VERSION "HNNBNNNYNNNNNNNNNNNNNNNNNNNNNNNNNNNNNNNNNN/4/%%%/4/'%**4NNN///"

NS_ :

BS_:

BU_: BAP_Tester BCM Gateway_Max TSGGen3_BFS TSGGen3_FS TSGGen3_HBFS TSGGen3_HFS WLC_01_CFD

BO_ 2527679923 ADA_01: 16 Gateway_Max
 SG_ ADA_DistractionLevel : 12|7@1+ (0.01,0) [0.00|1.00] "Unit_None"  Vector__XXX
 SG_ ADA_DrowsinessLevel : 19|7@1+ (0.01,0) [0.00|1.00] "Unit_None"  Vector__XXX
 SG_ ADA_AttentionLevel : 26|7@1+ (0.01,0) [0.00|1.00] "Unit_None"  Vector__XXX
 SG_ ADA_DriverIsOperating : 33|2@1+ (1.0,0.0) [0.0|3] ""  Vector__XXX
 SG_ ADA_HMI_Ablenkung_Deaktivierung : 35|1@1+ (1.0,0.0) [0.0|1] ""  Vector__XXX
 SG_ ADA_HMI_Ablenkung_Fehler_Popup : 36|2@1+ (1.0,0.0) [0.0|3] ""  Vector__XXX
 SG_ ADA_HMI_Ablenkung_Meldeakustik : 38|1@1+ (1.0,0.0) [0.0|1] ""  Vector__XXX
 SG_ ADA_HMI_Ablenkung_Meldung : 39|2@1+ (1.0,0.0) [0.0|3] ""  Vector__XXX
 SG_ ADA_HMI_Fahrzeit_seit_Pause : 41|10@1+ (1,0) [0|1022] "Unit_Minut"  Vector__XXX
 SG_ ADA_HMI_Muedigkeit_Deaktivierung : 51|1@1+ (1.0,0.0) [0.0|1] ""  Vector__XXX
 SG_ ADA_HMI_Muedigkeit_Fehler_Popup : 52|2@1+ (1.0,0.0) [0.0|3] ""  Vector__XXX
 SG_ ADA_HMI_Muedigkeit_Meldeakustik : 54|1@1+ (1.0,0.0) [0.0|1] ""  Vector__XXX
 SG_ ADA_HMI_Muedigkeit_Meldung : 55|3@1+ (1.0,0.0) [0.0|7] ""  BCM
 SG_ ADA_HMI_Muedigkeit_Event_Meldung : 58|2@1+ (1.0,0.0) [0.0|3] ""  BCM
 SG_ ADA_DrowsinessSystemState : 60|3@1+ (1.0,0.0) [0.0|7] ""  Vector__XXX
 SG_ ADA_Microsleep : 63|3@1+ (1.0,0.0) [0.0|7] ""  Vector__XXX
 SG_ ADA_TriggerEmergencyAssist : 66|3@1+ (1.0,0.0) [0.0|7] ""  Vector__XXX
 SG_ ADA_Upcoming_Microsleep : 69|1@1+ (1.0,0.0) [0.0|1] ""  Vector__XXX
 SG_ SOK_ADA_01_Signatur : 96|32@1+ (1,0) [0|4294967295] ""  Vector__XXX

BO_ 64 Airbag_01: 8 Gateway_Max
 SG_ Airbag_01_CRC : 0|8@1+ (1,0) [0|255] ""  BCM,TSGGen3_BFS,TSGGen3_FS,TSGGen3_HBFS,TSGGen3_HFS
 SG_ Airbag_01_BZ : 8|4@1+ (1,0) [0|15] ""  BCM,TSGGen3_BFS,TSGGen3_FS,TSGGen3_HBFS,TSGGen3_HFS
 SG_ AB_RGS_Anst : 12|4@1+ (1.0,0.0) [0.0|15] ""  BCM
 SG_ AB_Front_Crash : 16|1@1+ (1.0,0.0) [0.0|1] ""  BCM,TSGGen3_BFS,TSGGen3_FS,TSGGen3_HBFS,TSGGen3_HFS
 SG_ AB_Heck_Crash : 17|1@1+ (1.0,0.0) [0.0|1] ""  BCM,TSGGen3_BFS,TSGGen3_FS,TSGGen3_HBFS,TSGGen3_HFS
 SG_ AB_SF_Crash : 18|1@1+ (1.0,0.0) [0.0|1] ""  BCM,TSGGen3_BFS,TSGGen3_FS,TSGGen3_HBFS,TSGGen3_HFS
 SG_ AB_SB_Crash : 19|1@1+ (1.0,0.0) [0.0|1] ""  BCM,TSGGen3_BFS,TSGGen3_FS,TSGGen3_HBFS,TSGGen3_HFS
 SG_ AB_Rollover_Crash : 20|1@1+ (1.0,0.0) [0.0|1] ""  BCM,TSGGen3_BFS,TSGGen3_FS,TSGGen3_HBFS,TSGGen3_HFS
 SG_ AB_Crash_Int : 21|3@1+ (1.0,0.0) [0.0|7] ""  BCM,TSGGen3_BFS,TSGGen3_FS,TSGGen3_HBFS,TSGGen3_HFS
 SG_ AB_Lampe : 24|1@1+ (1.0,0.0) [0.0|1] ""  BCM
 SG_ AB_Deaktiviert : 25|1@1+ (1.0,0.0) [0.0|1] ""  BCM
 SG_ AB_VB_deaktiviert : 26|1@1+ (1.0,0.0) [0.0|1] ""  BCM
 SG_ AB_Systemfehler : 27|1@1+ (1.0,0.0) [0.0|1] ""  BCM
 SG_ AB_Diagnose : 28|1@1+ (1.0,0.0) [0.0|1] ""  BCM
 SG_ AB_Stellgliedtest : 29|1@1+ (1.0,0.0) [0.0|1] ""  BCM
 SG_ AB_Erh_Auf_VB : 30|2@1+ (1.0,0.0) [0.0|3] ""  BCM
 SG_ AB_Gurtwarn_VF : 32|1@1+ (1.0,0.0) [0.0|1] ""  BCM,TSGGen3_FS,TSGGen3_HBFS,TSGGen3_HFS
 SG_ AB_Gurtwarn_VB : 33|1@1+ (1.0,0.0) [0.0|1] ""  BCM,TSGGen3_BFS,TSGGen3_HBFS,TSGGen3_HFS
 SG_ AB_Anzeige_Fussg : 34|2@1+ (1.0,0.0) [0.0|3] ""  BCM
 SG_ AB_Texte_AKS : 36|2@1+ (1.0,0.0) [0.0|3] ""  BCM
 SG_ AB_PAO_Leuchte_Anf : 38|1@1+ (1.0,0.0) [0.0|1] ""  BCM
 SG_ AB_MKB_gueltig : 39|1@1+ (1.0,0.0) [0.0|1] ""  BCM
 SG_ AB_MKB_Anforderung : 40|1@1+ (1.0,0.0) [0.0|1] ""  BCM
 SG_ AB_Versorgungsspannung : 41|1@1+ (1.0,0.0) [0.0|1] ""  BCM
 SG_ AB_Deaktivierung_HV : 42|3@1+ (1.0,0.0) [0.0|7] ""  BCM
 SG_ AB_EDR_Trigger : 45|2@1+ (1.0,0.0) [0.0|3] ""  BCM
 SG_ AB_Belegung_VF : 47|2@1+ (1.0,0.0) [0.0|3] ""  BCM
 SG_ AB_Gurtschloss_FA_ext : 49|3@1+ (1.0,0.0) [0.0|7] ""  BCM
 SG_ AB_Gurtschloss_FA_ext_aktiv : 52|1@1+ (1.0,0.0) [0.0|1] ""  BCM
 SG_ AB_eCS_Error : 53|1@1+ (1.0,0.0) [0.0|1] ""  BCM
 SG_ ASM_Masterzeit_02 : 56|8@1+ (0.04,0) [0.00|10.16] "Unit_Secon"  BCM

BO_ 1312 Airbag_02: 8 Gateway_Max
 SG_ Airbag_02_CRC : 0|8@1+ (1,0) [0|255] ""  BCM
 SG_ Airbag_02_BZ : 8|4@1+ (1,0) [0|15] ""  BCM
 SG_ LoGeWa_Event_Kombiwarnung : 12|4@1+ (1.0,0.0) [0.0|15] ""  BCM
 SG_ AB_Anforderung_eCall : 16|1@1+ (1.0,0.0) [0.0|1] ""  BCM
 SG_ AB_Anprall_Seite_Beifahrer : 17|1@1+ (1.0,0.0) [0.0|1] ""  BCM
 SG_ AB_Anprall_Rollover : 18|1@1+ (1.0,0.0) [0.0|1] ""  BCM
 SG_ AB_Anprall_FGS : 19|1@1+ (1.0,0.0) [0.0|1] ""  BCM
 SG_ AB_Anprall_Front_Beifahrer : 20|1@1+ (1.0,0.0) [0.0|1] ""  BCM
 SG_ AB_Anprall_Front_Fahrer : 21|1@1+ (1.0,0.0) [0.0|1] ""  BCM
 SG_ AB_Anprall_Heck_Beifahrer : 22|1@1+ (1.0,0.0) [0.0|1] ""  BCM
 SG_ AB_Anprall_Heck_Fahrer : 23|1@1+ (1.0,0.0) [0.0|1] ""  BCM
 SG_ AB_Wickelklappung_Reihe2_MI : 24|2@1+ (1.0,0.0) [0.0|3] ""  BCM
 SG_ AB_Belegung_VB : 26|2@1+ (1.0,0.0) [0.0|3] ""  BCM,TSGGen3_BFS
 SG_ AB_Abschaltanf_SIH_BF : 28|1@1+ (1.0,0.0) [0.0|1] ""  BCM
 SG_ AB_Anprall_Seite_Fahrer : 29|1@1+ (1.0,0.0) [0.0|1] ""  BCM
 SG_ SC_PAO_Schriftzug_Anf : 30|2@1+ (1.0,0.0) [0.0|3] ""  BCM
 SG_ SC_PAO_ON_Anf : 32|2@1+ (1.0,0.0) [0.0|3] ""  BCM
 SG_ SC_PAO_OFF_Anf : 34|2@1+ (1.0,0.0) [0.0|3] ""  BCM
 SG_ AB_Crashschwere : 36|3@1+ (1.0,0.0) [0.0|7] ""  BCM
 SG_ AB_Anforderung_USM : 39|1@1+ (1.0,0.0) [0.0|1] ""  BCM
 SG_ AB_Gurtschloss_FA : 40|2@1+ (1.0,0.0) [0.0|3] ""  BCM,TSGGen3_FS,TSGGen3_HBFS,TSGGen3_HFS
 SG_ AB_Gurtschloss_BF : 42|2@1+ (1.0,0.0) [0.0|3] ""  BCM,TSGGen3_BFS,TSGGen3_HBFS,TSGGen3_HFS
 SG_ AB_Gurtschloss_Reihe2_FA : 44|2@1+ (1.0,0.0) [0.0|3] ""  BCM
 SG_ AB_Gurtschloss_Reihe2_MI : 46|2@1+ (1.0,0.0) [0.0|3] ""  BCM
 SG_ AB_Gurtschloss_Reihe2_BF : 48|2@1+ (1.0,0.0) [0.0|3] ""  BCM
 SG_ AB_Gurtschloss_Reihe3_FA : 50|2@1+ (1.0,0.0) [0.0|3] ""  BCM
 SG_ AB_Gurtschloss_Reihe3_MI : 52|2@1+ (1.0,0.0) [0.0|3] ""  BCM
 SG_ AB_Gurtschloss_Reihe3_BF : 54|2@1+ (1.0,0.0) [0.0|3] ""  BCM
 SG_ AB_Sitzpos_Sens_FA : 56|2@1+ (1.0,0.0) [0.0|3] ""  BCM,TSGGen3_FS,TSGGen3_HBFS,TSGGen3_HFS
 SG_ AB_Sitzpos_Sens_BF : 58|2@1+ (1.0,0.0) [0.0|3] ""  BCM,TSGGen3_BFS,TSGGen3_HBFS,TSGGen3_HFS
 SG_ AB_Wickelklappung_Reihe2_BF : 60|2@1+ (1.0,0.0) [0.0|3] ""  BCM
 SG_ AB_Wickelklappung_Reihe2_FA : 62|2@1+ (1.0,0.0) [0.0|3] ""  BCM

BO_ 1349 Airbag_04: 8 Gateway_Max
 SG_ Airbag_04_CRC : 0|8@1+ (1,0) [0|255] ""  BCM
 SG_ Airbag_04_BZ : 8|4@1+ (1,0) [0|15] ""  BCM
 SG_ AB_Anprall_Front : 12|1@1+ (1.0,0.0) [0.0|1] ""  Vector__XXX
 SG_ AB_Anprall_Heck : 13|1@1+ (1.0,0.0) [0.0|1] ""  Vector__XXX
 SG_ AB_Gurtwarn_Reihe4_FA : 14|2@1+ (1.0,0.0) [0.0|3] ""  BCM
 SG_ AB_Gurtwarn_Reihe4_BF : 16|2@1+ (1.0,0.0) [0.0|3] ""  BCM
 SG_ AB_Gurtwarn_Reihe4_MI : 18|2@1+ (1.0,0.0) [0.0|3] ""  BCM
 SG_ AB_Gurtwarn_Reihe2_FA : 20|2@1+ (1.0,0.0) [0.0|3] ""  BCM
 SG_ AB_Gurtwarn_Reihe2_BF : 22|2@1+ (1.0,0.0) [0.0|3] ""  BCM
 SG_ AbstWarn_MV_FAS_Fkt_Status : 24|2@1+ (1.0,0.0) [0.0|3] ""  Vector__XXX
 SG_ WarnBrems_Charisma_Status : 26|2@1+ (1.0,0.0) [0.0|3] ""  Vector__XXX
 SG_ WarnBrems_Charisma_FahrPr : 28|4@1+ (1.0,0.0) [0.0|15] ""  Vector__XXX
 SG_ AB_Gurtwarn_Reihe2_MI : 32|2@1+ (1.0,0.0) [0.0|3] ""  BCM
 SG_ AB_Gurtwarn_Reihe3_FA : 34|2@1+ (1.0,0.0) [0.0|3] ""  BCM
 SG_ AB_Gurtwarn_Reihe3_MI : 36|2@1+ (1.0,0.0) [0.0|3] ""  BCM
 SG_ AB_Gurtwarn_Reihe3_BF : 38|2@1+ (1.0,0.0) [0.0|3] ""  BCM
 SG_ LGI_FAS_Fkt_Status : 40|2@1+ (1.0,0.0) [0.0|3] ""  Vector__XXX
 SG_ PreCrash_FAS_Fkt_Status : 42|3@1+ (1.0,0.0) [0.0|7] ""  Vector__XXX
 SG_ AB_Belegung_VF_ext : 45|3@1+ (1.0,0.0) [0.0|7] ""  BCM
 SG_ AB_SBR_hinten_verbau : 48|2@1+ (1.0,0.0) [0.0|3] ""  Vector__XXX
 SG_ AB_Belegung_VF_ext_aktiv : 50|1@1+ (1.0,0.0) [0.0|1] ""  BCM
 SG_ AWV_Einstellung_System_ASG : 51|1@1+ (1.0,0.0) [0.0|1] ""  Vector__XXX
 SG_ AWV_Einstellung_Warnung_ASG : 52|3@1+ (1.0,0.0) [0.0|7] ""  Vector__XXX
 SG_ SC_PreSense_Modus_Warnung_NV : 55|3@1+ (1.0,0.0) [0.0|7] ""  Vector__XXX
 SG_ SC_PreSense_Modus_Warnung_MV : 58|3@1+ (1.0,0.0) [0.0|7] ""  Vector__XXX
 SG_ SC_PreSense_Modus_System_MV : 61|1@1+ (1.0,0.0) [0.0|1] ""  Vector__XXX
 SG_ SC_PreSense_Modus_System_NV : 62|1@1+ (1.0,0.0) [0.0|1] ""  Vector__XXX
 SG_ SC_PreSense_Modus_System_KAS : 63|1@1+ (1.0,0.0) [0.0|1] ""  Vector__XXX

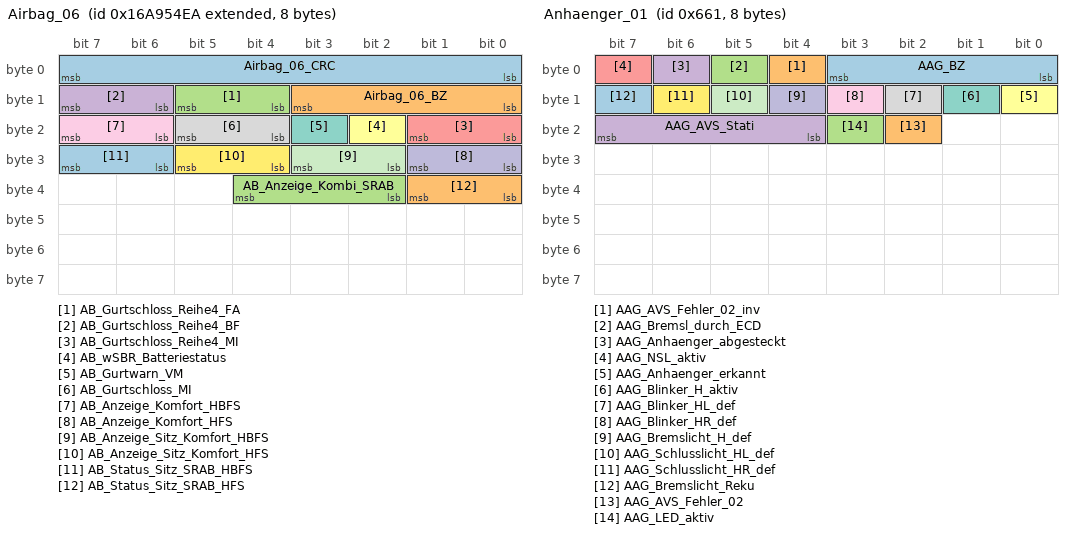
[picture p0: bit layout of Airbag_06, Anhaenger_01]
BO_ 2527679722 Airbag_06: 8 Gateway_Max
 SG_ Airbag_06_CRC : 0|8@1+ (1,0) [0|255] ""  Vector__XXX
 SG_ Airbag_06_BZ : 8|4@1+ (1,0) [0|15] ""  Vector__XXX
 SG_ AB_Gurtschloss_Reihe4_FA : 12|2@1+ (1.0,0.0) [0.0|3] ""  BCM
 SG_ AB_Gurtschloss_Reihe4_BF : 14|2@1+ (1.0,0.0) [0.0|3] ""  BCM
 SG_ AB_Gurtschloss_Reihe4_MI : 16|2@1+ (1.0,0.0) [0.0|3] ""  BCM
 SG_ AB_wSBR_Batteriestatus : 18|1@1+ (1.0,0.0) [0.0|1] ""  Vector__XXX
 SG_ AB_Gurtwarn_VM : 19|1@1+ (1.0,0.0) [0.0|1] ""  BCM
 SG_ AB_Gurtschloss_MI : 20|2@1+ (1.0,0.0) [0.0|3] ""  BCM
 SG_ AB_Anzeige_Komfort_HBFS : 22|2@1+ (1.0,0.0) [0.0|3] ""  Vector__XXX
 SG_ AB_Anzeige_Komfort_HFS : 24|2@1+ (1.0,0.0) [0.0|3] ""  Vector__XXX
 SG_ AB_Anzeige_Sitz_Komfort_HBFS : 26|2@1+ (1.0,0.0) [0.0|3] ""  Vector__XXX
 SG_ AB_Anzeige_Sitz_Komfort_HFS : 28|2@1+ (1.0,0.0) [0.0|3] ""  Vector__XXX
 SG_ AB_Status_Sitz_SRAB_HBFS : 30|2@1+ (1.0,0.0) [0.0|3] ""  Vector__XXX
 SG_ AB_Status_Sitz_SRAB_HFS : 32|2@1+ (1.0,0.0) [0.0|3] ""  Vector__XXX
 SG_ AB_Anzeige_Kombi_SRAB : 34|3@1+ (1.0,0.0) [0.0|7] ""  Vector__XXX

BO_ 1633 Anhaenger_01: 8 Gateway_Max
 SG_ AAG_BZ : 0|4@1+ (1,0) [0|15] ""  Vector__XXX
 SG_ AAG_AVS_Fehler_02_inv : 4|1@1+ (1.0,0.0) [0.0|1] ""  BCM
 SG_ AAG_Bremsl_durch_ECD : 5|1@1+ (1.0,0.0) [0.0|1] ""  Vector__XXX
 SG_ AAG_Anhaenger_abgesteckt : 6|1@1+ (1.0,0.0) [0.0|1] ""  Vector__XXX
 SG_ AAG_NSL_aktiv : 7|1@1+ (1.0,0.0) [0.0|1] ""  Vector__XXX
 SG_ AAG_Anhaenger_erkannt : 8|1@1+ (1.0,0.0) [0.0|1] ""  BCM
 SG_ AAG_Blinker_H_aktiv : 9|1@1+ (1.0,0.0) [0.0|1] ""  Vector__XXX
 SG_ AAG_Blinker_HL_def : 10|1@1+ (1.0,0.0) [0.0|1] ""  BCM
 SG_ AAG_Blinker_HR_def : 11|1@1+ (1.0,0.0) [0.0|1] ""  BCM
 SG_ AAG_Bremslicht_H_def : 12|1@1+ (1.0,0.0) [0.0|1] ""  Vector__XXX
 SG_ AAG_Schlusslicht_HL_def : 13|1@1+ (1.0,0.0) [0.0|1] ""  Vector__XXX
 SG_ AAG_Schlusslicht_HR_def : 14|1@1+ (1.0,0.0) [0.0|1] ""  Vector__XXX
 SG_ AAG_Bremslicht_Reku : 15|1@1+ (1.0,0.0) [0.0|1] ""  Vector__XXX
 SG_ AAG_AVS_Fehler_02 : 18|1@1+ (1.0,0.0) [0.0|1] ""  BCM
 SG_ AAG_LED_aktiv : 19|1@1+ (1.0,0.0) [0.0|1] ""  Vector__XXX
 SG_ AAG_AVS_Stati : 20|4@1+ (1.0,0.0) [0.0|15] ""  BCM

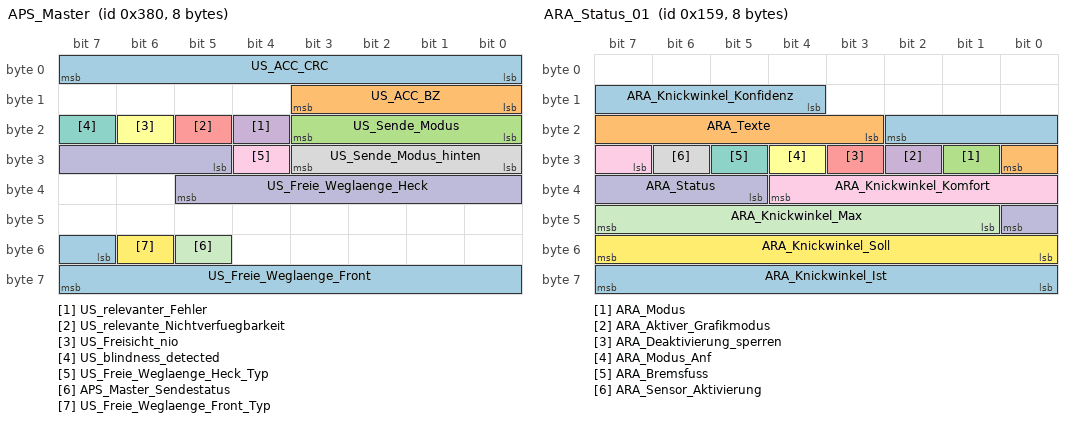
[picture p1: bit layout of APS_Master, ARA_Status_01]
BO_ 896 APS_Master: 8 Gateway_Max
 SG_ US_ACC_CRC : 0|8@1+ (1,0) [0|255] ""  Vector__XXX
 SG_ US_ACC_BZ : 8|4@1+ (1,0) [0|15] ""  Vector__XXX
 SG_ US_Sende_Modus : 16|4@1+ (1.0,0.0) [0.0|15] ""  Vector__XXX
 SG_ US_relevanter_Fehler : 20|1@1+ (1.0,0.0) [0.0|1] ""  Vector__XXX
 SG_ US_relevante_Nichtverfuegbarkeit : 21|1@1+ (1.0,0.0) [0.0|1] ""  Vector__XXX
 SG_ US_Freisicht_nio : 22|1@1+ (1.0,0.0) [0.0|1] ""  Vector__XXX
 SG_ US_blindness_detected : 23|1@1+ (1.0,0.0) [0.0|1] ""  Vector__XXX
 SG_ US_Sende_Modus_hinten : 24|4@1+ (1.0,0.0) [0.0|15] ""  Vector__XXX
 SG_ US_Freie_Weglaenge_Heck_Typ : 28|1@1+ (1.0,0.0) [0.0|1] ""  BCM
 SG_ US_Freie_Weglaenge_Heck : 29|9@1+ (0.01,0) [0.00|5.00] "Unit_Meter"  BCM
 SG_ APS_Master_Sendestatus : 53|1@1+ (1.0,0.0) [0.0|1] ""  Vector__XXX
 SG_ US_Freie_Weglaenge_Front_Typ : 54|1@1+ (1.0,0.0) [0.0|1] ""  Vector__XXX
 SG_ US_Freie_Weglaenge_Front : 55|9@1+ (0.01,0) [0.00|5.00] "Unit_Meter"  Vector__XXX

BO_ 345 ARA_Status_01: 8 Gateway_Max
 SG_ ARA_Knickwinkel_Konfidenz : 12|7@1+ (1,0) [0|120] "Unit_DegreOfArc"  Vector__XXX
 SG_ ARA_Texte : 19|6@1+ (1.0,0.0) [0.0|63] ""  Vector__XXX
 SG_ ARA_Modus : 25|1@1+ (1.0,0.0) [0.0|1] ""  Vector__XXX
 SG_ ARA_Aktiver_Grafikmodus : 26|1@1+ (1.0,0.0) [0.0|1] ""  Vector__XXX
 SG_ ARA_Deaktivierung_sperren : 27|1@1+ (1.0,0.0) [0.0|1] ""  Vector__XXX
 SG_ ARA_Modus_Anf : 28|1@1+ (1.0,0.0) [0.0|1] ""  TSGGen3_FS
 SG_ ARA_Bremsfuss : 29|1@1+ (1.0,0.0) [0.0|1] ""  Vector__XXX
 SG_ ARA_Sensor_Aktivierung : 30|1@1+ (1.0,0.0) [0.0|1] ""  Vector__XXX
 SG_ ARA_Knickwinkel_Komfort : 31|6@1+ (1,0) [0|60] "Unit_DegreOfArc"  Vector__XXX
 SG_ ARA_Status : 37|4@1+ (1.0,0.0) [0.0|15] ""  Vector__XXX
 SG_ ARA_Knickwinkel_Max : 41|7@1+ (1,0) [0|120] "Unit_DegreOfArc"  Vector__XXX
 SG_ ARA_Knickwinkel_Soll : 48|8@1+ (1,-125) [-125|126] "Unit_DegreOfArc"  Vector__XXX
 SG_ ARA_Knickwinkel_Ist : 56|8@1+ (1,-125) [-125|126] "Unit_DegreOfArc"  Vector__XXX

BO_ 2527679661 AWV_02: 8 Gateway_Max
 SG_ WBA_Warnblinken : 0|2@1+ (1.0,0.0) [0.0|3] ""  BCM
 SG_ AWV_KA_Konfiguration : 2|1@1+ (1.0,0.0) [0.0|1] ""  Vector__XXX
 SG_ AWV_Warnung : 12|3@1+ (1.0,0.0) [0.0|7] ""  Vector__XXX
 SG_ AWV_Texte_02 : 15|3@1+ (1.0,0.0) [0.0|7] ""  Vector__XXX
 SG_ AWV_Warnlevel : 18|6@1+ (1.0,0.0) [0.0|63] ""  Vector__XXX
 SG_ AWV_Einstellung_System_FSG : 24|1@1+ (1.0,0.0) [0.0|1] ""  Vector__XXX
 SG_ AWV_Einstellung_Warnung_FSG : 25|3@1+ (1.0,0.0) [0.0|7] ""  Vector__XXX
 SG_ AWV_Status_Anzeige : 28|2@1+ (1.0,0.0) [0.0|3] ""  Vector__XXX
 SG_ AWV_LED_Leiste : 30|2@1+ (1.0,0.0) [0.0|3] ""  Vector__XXX
 SG_ AWV_Priowarnung : 32|1@1+ (1.0,0.0) [0.0|1] ""  Vector__XXX
 SG_ AWV_AW_Abstand : 33|9@1+ (1,0) [0|508] "Unit_Meter"  Vector__XXX
 SG_ AWV_AW_Zeitluecke : 42|3@1+ (1.0,0.0) [0.0|7] ""  Vector__XXX
 SG_ AWV_AW_Texte : 45|3@1+ (1.0,0.0) [0.0|7] ""  Vector__XXX
 SG_ AWV_AW_Texte_Zusatzanzeige : 48|4@1+ (1.0,0.0) [0.0|15] ""  Vector__XXX
 SG_ AWV_KA_ObjektFront : 52|1@1+ (1.0,0.0) [0.0|1] ""  Vector__XXX
 SG_ AWV_Warnung_Richtung : 53|3@1+ (1.0,0.0) [0.0|7] ""  Vector__XXX
 SG_ AWV_Kamera_Objekt_ID : 56|8@1+ (1,0) [1|255] "Unit_None"  Vector__XXX

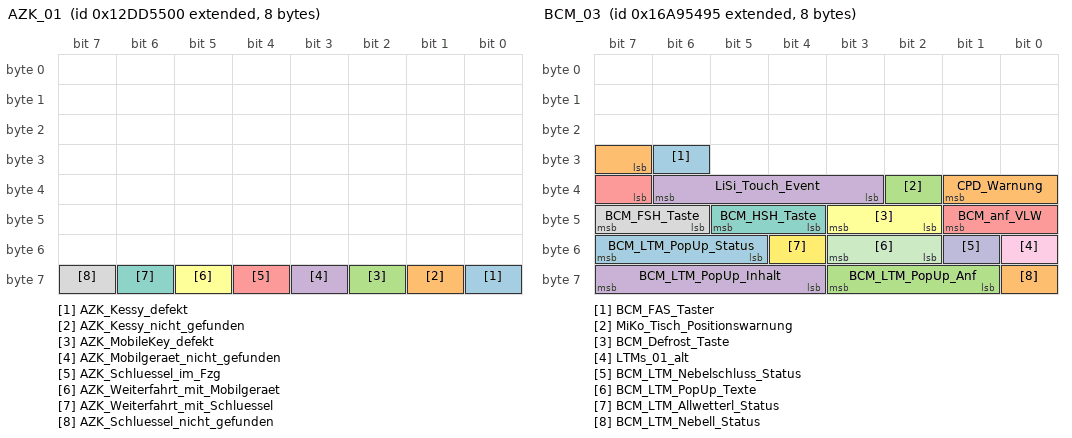
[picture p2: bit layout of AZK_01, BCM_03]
BO_ 2463978752 AZK_01: 8 BCM
 SG_ AZK_Kessy_defekt : 56|1@1+ (1.0,0.0) [0.0|1] ""  Gateway_Max
 SG_ AZK_Kessy_nicht_gefunden : 57|1@1+ (1.0,0.0) [0.0|1] ""  Gateway_Max
 SG_ AZK_MobileKey_defekt : 58|1@1+ (1.0,0.0) [0.0|1] ""  Gateway_Max
 SG_ AZK_Mobilgeraet_nicht_gefunden : 59|1@1+ (1.0,0.0) [0.0|1] ""  Gateway_Max
 SG_ AZK_Schluessel_im_Fzg : 60|1@1+ (1.0,0.0) [0.0|1] ""  Gateway_Max
 SG_ AZK_Weiterfahrt_mit_Mobilgeraet : 61|1@1+ (1.0,0.0) [0.0|1] ""  Gateway_Max
 SG_ AZK_Weiterfahrt_mit_Schluessel : 62|1@1+ (1.0,0.0) [0.0|1] ""  Gateway_Max
 SG_ AZK_Schluessel_nicht_gefunden : 63|1@1+ (1.0,0.0) [0.0|1] ""  Gateway_Max

BO_ 2536704256 BAP_Aussenlicht_ASG_01: 8 Gateway_Max
 SG_ BAP_Aussenlicht_ASG_01_Header : 0|8@1+ (1.0,0.0) [0.0|255] ""  BCM

BO_ 2536704257 BAP_Aussenlicht_ASG_02: 8 Gateway_Max
 SG_ BAP_Aussenlicht_ASG_02_Header : 0|8@1+ (1,0) [0|255] "Unit_None"  BCM

BO_ 2536704272 BAP_Aussenlicht_FSG_01: 8 BCM
 SG_ BAP_Aussenlicht_FSG_01_Header : 0|8@1+ (1.0,0.0) [0.0|255] ""  Gateway_Max

BO_ 2536726786 BAP_Car2X_ASG_03: 8 Gateway_Max
 SG_ BAP_Car2X_ASG_03_Header : 0|64@1+ (1.0,0.0) [0.0|18446744073709551615] ""  BCM

BO_ 2536726802 BAP_Car2X_FSG_03: 8 BCM
 SG_ BAP_Car2X_FSG_03_Header : 0|64@1+ (1.0,0.0) [0.0|18446744073709551615] ""  Gateway_Max

BO_ 2536767264 BAP_Debug_Cmd: 8 BAP_Tester
 SG_ BAP_Debug_Cmd : 0|16@1+ (1.0,0.0) [0.0|65535] ""  BCM,TSGGen3_BFS,TSGGen3_FS

BO_ 2536767280 BAP_Debug_Data: 8 BCM
 SG_ BAP_Debug_Data : 0|64@1+ (1.0,0.0) [0.0|18446744073709551615] ""  BAP_Tester

BO_ 2536705280 BAP_Doorlocking_ASG_01: 8 Gateway_Max
 SG_ BAP_Doorlocking_ASG_01_Header : 0|8@1+ (1.0,0.0) [0.0|255] ""  BCM

BO_ 2536705281 BAP_Doorlocking_ASG_02: 8 Gateway_Max
 SG_ BAP_Doorlocking_ASG_02_Header : 0|8@1+ (1.0,0.0) [0.0|255] ""  BCM

BO_ 2536705282 BAP_Doorlocking_ASG_03: 8 Gateway_Max
 SG_ BAP_Doorlocking_ASG_03_Header : 0|8@1+ (1.0,0.0) [0.0|255] ""  BCM

BO_ 2536705296 BAP_Doorlocking_FSG_01: 8 BCM
 SG_ BAP_Doorlocking_FSG_01_Header : 0|8@1+ (1.0,0.0) [0.0|255] ""  Gateway_Max

BO_ 2536727296 BAP_Doors2_ASG_01: 8 Gateway_Max
 SG_ BAP_Doors2_ASG_01_Header : 0|64@1+ (1.0,0.0) [0.0|18446744073709551615] ""  TSGGen3_BFS

BO_ 2536727312 BAP_Doors2_FSG_01: 8 TSGGen3_BFS
 SG_ BAP_Doors2_FSG_01_Header : 0|64@1+ (1.0,0.0) [0.0|18446744073709551615] ""  Gateway_Max

BO_ 2536724736 BAP_Doors_ASG_01: 8 Gateway_Max
 SG_ BAP_Doors_ASG_01_Header : 0|8@1+ (1,0) [0|255] "Unit_None"  TSGGen3_FS

BO_ 2536724752 BAP_Doors_FSG_01: 8 TSGGen3_FS
 SG_ BAP_Doors_FSG_01_Header : 0|8@1+ (1,0) [0|255] "Unit_None"  Gateway_Max

BO_ 2536724480 BAP_ENI2_ASG_01: 8 Gateway_Max
 SG_ BAP_ENI2_ASG_01_Header : 0|8@1+ (1,0) [0|255] "Unit_None"  BCM

BO_ 2536724481 BAP_ENI2_ASG_02: 8 Gateway_Max
 SG_ BAP_ENI2_ASG_02_Header : 0|8@1+ (1,0) [0|255] "Unit_None"  BCM

BO_ 2536724496 BAP_ENI2_FSG_01: 8 BCM
 SG_ BAP_ENI2_FSG_01_Header : 0|8@1+ (1,0) [0|255] "Unit_None"  Gateway_Max

BO_ 2536724497 BAP_ENI2_FSG_02: 8 BCM
 SG_ BAP_ENI2_FSG_02_Header : 0|8@1+ (1,0) [0|255] "Unit_None"  Gateway_Max

BO_ 2536707072 BAP_Homelink_ASG_01: 8 Gateway_Max
 SG_ BAP_Homelink_ASG_01_Header : 0|64@1+ (1.0,0.0) [0.0|18446744073709551615] ""  BCM

BO_ 2536707088 BAP_Homelink_FSG_01: 8 BCM
 SG_ BAP_Homelink_FSG_01_Header : 0|64@1+ (1.0,0.0) [0.0|18446744073709551615] ""  Gateway_Max

BO_ 2536722946 BAP_IAA_PSO_ASG_03: 8 BCM
 SG_ BAP_IAA_PSO_ASG_03_Header : 0|8@1+ (1,0) [0|255] "Unit_None"  Gateway_Max

BO_ 2536722960 BAP_IAA_PSO_FSG_01: 8 Gateway_Max
 SG_ BAP_IAA_PSO_FSG_01_Header : 0|8@1+ (1,0) [0|255] "Unit_None"  BCM

BO_ 2536704000 BAP_Innenlicht_ASG_01: 8 Gateway_Max
 SG_ BAP_Innenlicht_ASG_01_Header : 0|8@1+ (1.0,0.0) [0.0|255] ""  BCM

BO_ 2536704001 BAP_Innenlicht_ASG_02: 8 Gateway_Max
 SG_ BAP_Innenlicht_ASG_02_Header : 0|8@1+ (1,0) [0|255] "Unit_None"  BCM

BO_ 2536704003 BAP_Innenlicht_ASG_04: 8 Gateway_Max
 SG_ BAP_Innenlicht_ASG_04_Header : 0|64@1+ (1.0,0.0) [0.0|18446744073709551615] ""  BCM

BO_ 2536704016 BAP_Innenlicht_FSG_01: 8 BCM
 SG_ BAP_Innenlicht_FSG_01_Header : 0|8@1+ (1.0,0.0) [0.0|255] ""  Gateway_Max

BO_ 2536705536 BAP_Mirror_ASG_01: 8 Gateway_Max
 SG_ BAP_Mirror_ASG_01_Header : 0|8@1+ (1.0,0.0) [0.0|255] ""  BCM

BO_ 2536705537 BAP_Mirror_ASG_02: 8 Gateway_Max
 SG_ BAP_Mirror_ASG_02_Header : 0|8@1+ (1,0) [0|255] "Unit_None"  BCM

BO_ 2536705552 BAP_Mirror_FSG_01: 8 BCM
 SG_ BAP_Mirror_FSG_01_Header : 0|8@1+ (1.0,0.0) [0.0|255] ""  Gateway_Max

BO_ 2536732416 BAP_MobDevKey_ASG_01: 8 Gateway_Max
 SG_ BAP_MobDevKey_ASG_01_Header : 0|64@1+ (1.0,0.0) [0.0|18446744073709551615] ""  BCM

BO_ 2536732417 BAP_MobDevKey_ASG_02: 8 Gateway_Max
 SG_ BAP_MobDevKey_ASG_02_Header : 0|64@1+ (1.0,0.0) [0.0|18446744073709551615] ""  BCM

BO_ 2536732432 BAP_MobDevKey_FSG_01: 8 BCM
 SG_ BAP_MobDevKey_FSG_01_Header : 0|64@1+ (1.0,0.0) [0.0|18446744073709551615] ""  Gateway_Max

BO_ 2536734464 BAP_MobDevKeyOnline_ASG_01: 8 BCM
 SG_ BAP_MobDevKeyOnline_ASG_01_Heade : 0|64@1+ (1.0,0.0) [0.0|18446744073709551615] ""  Gateway_Max

BO_ 2536734480 BAP_MobDevKeyOnline_FSG_01: 8 Gateway_Max
 SG_ BAP_MobDevKeyOnline_FSG_01_Heade : 0|64@1+ (1.0,0.0) [0.0|18446744073709551615] ""  BCM

BO_ 2536704517 BAP_OPS_ASG_06: 8 BCM
 SG_ BAP_OPS_ASG_06_Header : 0|64@1+ (1.0,0.0) [0.0|18446744073709551615] ""  Gateway_Max

BO_ 2536704528 BAP_OPS_FSG_01: 8 Gateway_Max
 SG_ BAP_OPS_FSG_01_Header : 0|8@1+ (1.0,0.0) [0.0|255] ""  BCM

BO_ 2536704529 BAP_OPS_FSG_02: 8 Gateway_Max
 SG_ BAP_OPS_FSG_02_Header : 0|8@1+ (1.0,0.0) [0.0|255] ""  BCM

BO_ 2536721920 BAP_RemoteServices_ASG_01: 8 Gateway_Max
 SG_ BAP_RemoteServices_ASG_01_Header : 0|8@1+ (1,0) [0|255] "Unit_None"  BCM

BO_ 2536721921 BAP_RemoteServices_ASG_02: 8 Gateway_Max
 SG_ BAP_RemoteServices_ASG_02_Header : 0|8@1+ (1,0) [0|255] "Unit_None"  BCM

BO_ 2536721936 BAP_RemoteServices_FSG_01: 8 BCM
 SG_ BAP_RemoteServices_FSG_01_Header : 0|8@1+ (1,0) [0|255] "Unit_None"  Gateway_Max

BO_ 2536731904 BAP_RollingAbility_ASG_01: 8 Gateway_Max
 SG_ BAP_RollingAbility_ASG_01_Header : 0|64@1+ (1.0,0.0) [0.0|18446744073709551615] ""  BCM

BO_ 2536731920 BAP_RollingAbility_FSG_01: 8 BCM
 SG_ BAP_RollingAbility_FSG_01_Header : 0|64@1+ (1.0,0.0) [0.0|18446744073709551615] ""  Gateway_Max

BO_ 2536730624 BAP_RSO_ASG_01: 8 Gateway_Max
 SG_ BAP_RSO_ASG_01_Header : 0|64@1+ (1.0,0.0) [0.0|18446744073709551615] ""  BCM

BO_ 2536730640 BAP_RSO_FSG_01: 8 BCM
 SG_ BAP_RSO_FSG_01_Header : 0|64@1+ (1.0,0.0) [0.0|18446744073709551615] ""  Gateway_Max

BO_ 2536717056 BAP_SeatPneumatic_ASG_01: 8 Gateway_Max
 SG_ BAP_SeatPneumatic_ASG_01_Header : 0|8@1+ (1.0,0.0) [0.0|255] ""  BCM

BO_ 2536717057 BAP_SeatPneumatic_ASG_02: 8 Gateway_Max
 SG_ BAP_SeatPneumatic_ASG_02_Header : 0|64@1+ (1.0,0.0) [0.0|18446744073709551615] ""  BCM

BO_ 2536717072 BAP_SeatPneumatic_FSG_01: 8 BCM
 SG_ BAP_SeatPneumatic_FSG_01_Header : 0|8@1+ (1.0,0.0) [0.0|255] ""  Gateway_Max

BO_ 2536705024 BAP_Wiper_ASG_01: 8 Gateway_Max
 SG_ BAP_Wiper_ASG_01_Header : 0|8@1+ (1.0,0.0) [0.0|255] ""  BCM

BO_ 2536705025 BAP_Wiper_ASG_02: 8 Gateway_Max
 SG_ BAP_Wiper_ASG_02_Header : 0|8@1+ (1,0) [0|255] "Unit_None"  BCM

BO_ 2536705040 BAP_Wiper_FSG_01: 8 BCM
 SG_ BAP_Wiper_FSG_01_Header : 0|8@1+ (1.0,0.0) [0.0|255] ""  Gateway_Max

BO_ 2583694872 BCM1_AuthTime_Req: 8 BCM
 SG_ BCM1_AuthTime_Req_Data : 0|64@1+ (1.0,0.0) [0.0|18446744073709551615] ""  Gateway_Max

BO_ 2583825944 BCM1_AuthTime_Resp: 8 Gateway_Max
 SG_ BCM1_AuthTime_Resp_Data : 0|64@1+ (1.0,0.0) [0.0|18446744073709551615] ""  BCM

BO_ 2527679636 BCM1_DML_01: 8 BCM
 SG_ BCM1_DML_Einsteigelicht_aktiv : 7|1@1+ (1.0,0.0) [0.0|1] ""  Gateway_Max
 SG_ BCM1_DML_Lichtfuehrung_aktiv : 8|1@1+ (1.0,0.0) [0.0|1] ""  Gateway_Max
 SG_ BCM1_DML_Lichtassistenz_aktiv : 9|1@1+ (1.0,0.0) [0.0|1] ""  Gateway_Max
 SG_ BCM1_DML_Fahrbereit : 10|1@1+ (1.0,0.0) [0.0|1] ""  Gateway_Max
 SG_ BCM1_DML_Aussteigelicht_aktiv : 11|1@1+ (1.0,0.0) [0.0|1] ""  Gateway_Max
 SG_ BCM1_DML_TraLi_Variante : 12|4@1+ (1.0,0.0) [0.0|15] ""  Gateway_Max
 SG_ BCM1_DML_BauLi_Variante : 16|4@1+ (1.0,0.0) [0.0|15] ""  Gateway_Max
 SG_ BCM1_DML_SitLi_Variante : 20|4@1+ (1.0,0.0) [0.0|15] ""  Gateway_Max
 SG_ BCM1_DML_aCH_Variante : 24|4@1+ (1.0,0.0) [0.0|15] ""  Gateway_Max
 SG_ BCM1_DML_aLH_Variante : 28|4@1+ (1.0,0.0) [0.0|15] ""  Gateway_Max
 SG_ BCM1_DML_AbbiegeWa_Variante : 32|4@1+ (1.0,0.0) [0.0|15] ""  Gateway_Max
 SG_ BCM1_DML_AbsAss_Variante : 36|4@1+ (1.0,0.0) [0.0|15] ""  Gateway_Max
 SG_ BCM1_DML_AccAss_Variante : 40|4@1+ (1.0,0.0) [0.0|15] ""  Gateway_Max
 SG_ BCM1_DML_BeAss_Variante : 44|4@1+ (1.0,0.0) [0.0|15] ""  Gateway_Max
 SG_ BCM1_DML_EffAss_Variante : 48|4@1+ (1.0,0.0) [0.0|15] ""  Gateway_Max
 SG_ BCM1_DML_PreSAss_Variante : 52|4@1+ (1.0,0.0) [0.0|15] ""  Gateway_Max
 SG_ BCM1_DML_RouLi_Variante : 56|4@1+ (1.0,0.0) [0.0|15] ""  Gateway_Max
 SG_ BCM1_DML_SpuLi_Variante : 60|4@1+ (1.0,0.0) [0.0|15] ""  Gateway_Max

BO_ 1626 BCM_01: 8 BCM
 SG_ BCM_Bremsbelag_Sensor : 12|1@1+ (1.0,0.0) [0.0|1] ""  Gateway_Max
 SG_ BCM_Bremsfluessigkeit_Sensor : 13|1@1+ (1.0,0.0) [0.0|1] ""  Gateway_Max
 SG_ BCM1_Licht_Warn : 14|1@1+ (1.0,0.0) [0.0|1] ""  Gateway_Max
 SG_ BCM_Waschwasser_Sensor : 15|1@1+ (1.0,0.0) [0.0|1] ""  Gateway_Max
 SG_ BCM_Kuehlmittel_Sensor : 16|1@1+ (1.0,0.0) [0.0|1] ""  Gateway_Max
 SG_ BCM1_Kl_15_HW_erkannt : 17|1@1+ (1.0,0.0) [0.0|1] ""  Gateway_Max
 SG_ BCM1_Kl_15_Sig_HW_erkannt : 18|1@1+ (1.0,0.0) [0.0|1] ""  Gateway_Max
 SG_ BCM_Kuehlmittel_Sensor_02 : 19|1@1+ (1.0,0.0) [0.0|1] ""  Gateway_Max
 SG_ BCM1_Hinweis_Lichtnachlauf : 20|1@1+ (1.0,0.0) [0.0|1] ""  Gateway_Max
 SG_ BCM_Offroad_Taste : 21|1@1+ (1.0,0.0) [0.0|1] ""  Gateway_Max
 SG_ BCM_Charisma_Taste2 : 22|1@1+ (1.0,0.0) [0.0|1] ""  Gateway_Max
 SG_ BCM_Hybrid_StSt_Taste_Fehler : 23|1@1+ (1.0,0.0) [0.0|1] ""  Gateway_Max
 SG_ BCM_Hybrid_StartStopp_Taste : 24|1@1+ (1.0,0.0) [0.0|1] ""  Gateway_Max
 SG_ BCM1_Warnblink_Taster : 25|1@1+ (1.0,0.0) [0.0|1] ""  Gateway_Max
 SG_ BCM1_Valet_Parking_Taster : 26|1@1+ (1.0,0.0) [0.0|1] ""  Gateway_Max
 SG_ BCM1_LDS_Stellung : 27|3@1+ (1.0,0.0) [0.0|7] ""  Gateway_Max
 SG_ BCM1_Rueckfahrlicht_Schalter : 30|1@1+ (1.0,0.0) [0.0|1] ""  Gateway_Max,TSGGen3_BFS,TSGGen3_FS,TSGGen3_HBFS,TSGGen3_HFS
 SG_ BCM1_MH_Schalter : 31|1@1+ (1.0,0.0) [0.0|1] ""  Gateway_Max
 SG_ BCM1_MH_WIV_Schalter : 32|1@1+ (1.0,0.0) [0.0|1] ""  Gateway_Max
 SG_ BCM_Eco_Charisma_Taste : 33|1@1+ (1.0,0.0) [0.0|1] ""  Gateway_Max
 SG_ BCM1_NV_Taster : 34|1@1+ (1.0,0.0) [0.0|1] ""  Gateway_Max
 SG_ BCM1_AFS_Lampe : 35|1@1+ (1.0,0.0) [0.0|1] ""  Gateway_Max
 SG_ BCM1_Reisemodus_Texte : 36|2@1+ (1.0,0.0) [0.0|3] ""  Gateway_Max
 SG_ BCM1_Lichtwarn_Texte : 38|2@1+ (1.0,0.0) [0.0|3] ""  Gateway_Max
 SG_ Gong_TFL_Umschaltung : 40|1@1+ (1.0,0.0) [0.0|1] ""  Gateway_Max
 SG_ BCM_ValetTaster_Fkts_LED : 42|1@1+ (1.0,0.0) [0.0|1] ""  Gateway_Max
 SG_ LRH_Taster : 43|1@1+ (1.0,0.0) [0.0|1] ""  Gateway_Max
 SG_ APS_Tongeber_defekt : 44|1@1+ (1.0,0.0) [0.0|1] ""  Gateway_Max
 SG_ BCM1_EasyEntry_Status : 45|1@1+ (1.0,0.0) [0.0|1] ""  Gateway_Max
 SG_ BCM1_Lenksaeule_aktiv : 46|1@1+ (1.0,0.0) [0.0|1] ""  Gateway_Max
 SG_ BCM1_Spannungs_Anf : 47|2@1+ (1.0,0.0) [0.0|3] ""  Gateway_Max
 SG_ DWA_Alarmquelle : 49|5@1+ (1.0,0.0) [0.0|31] ""  Gateway_Max
 SG_ DWA_Einschraenkung : 54|1@1+ (1.0,0.0) [0.0|1] ""  Gateway_Max
 SG_ BCM_HBFS_EOE_aktiv : 56|1@1+ (1.0,0.0) [0.0|1] ""  Gateway_Max
 SG_ BCM_HFS_EOE_aktiv : 57|1@1+ (1.0,0.0) [0.0|1] ""  Gateway_Max
 SG_ BCM_Anf_AAW_MoLaWa : 58|2@1+ (1.0,0.0) [0.0|3] ""  Gateway_Max
 SG_ BCM_Handbremse_Hinweis : 60|1@1+ (1.0,0.0) [0.0|1] ""  Gateway_Max
 SG_ BCM_Waehlhebel_P_Hinweis : 61|1@1+ (1.0,0.0) [0.0|1] ""  Gateway_Max
 SG_ BCM1_Fahrlicht_Hinweis : 62|1@1+ (1.0,0.0) [0.0|1] ""  Gateway_Max
 SG_ BCM_HDF_betaetigt : 63|1@1+ (1.0,0.0) [0.0|1] ""  Gateway_Max

BO_ 2527679637 BCM_03: 8 BCM
 SG_ BCM_FAS_Taster : 30|1@1+ (1.0,0.0) [0.0|1] ""  Gateway_Max
 SG_ CPD_Warnung : 31|3@1+ (1.0,0.0) [0.0|7] ""  Gateway_Max
 SG_ MiKo_Tisch_Positionswarnung : 34|1@1+ (1.0,0.0) [0.0|1] ""  Gateway_Max
 SG_ LiSi_Touch_Event : 35|4@1+ (1.0,0.0) [0.0|15] ""  Gateway_Max
 SG_ BCM_anf_VLW : 39|3@1+ (1.0,0.0) [0.0|7] ""  Gateway_Max
 SG_ BCM_Defrost_Taste : 42|2@1+ (1.0,0.0) [0.0|3] ""  Gateway_Max
 SG_ BCM_HSH_Taste : 44|2@1+ (1.0,0.0) [0.0|3] ""  Gateway_Max
 SG_ BCM_FSH_Taste : 46|2@1+ (1.0,0.0) [0.0|3] ""  Gateway_Max
 SG_ LTMs_01_alt : 48|1@1+ (1.0,0.0) [0.0|1] ""  Gateway_Max
 SG_ BCM_LTM_Nebelschluss_Status : 49|1@1+ (1.0,0.0) [0.0|1] ""  Gateway_Max
 SG_ BCM_LTM_PopUp_Texte : 50|2@1+ (1.0,0.0) [0.0|3] ""  Gateway_Max
 SG_ BCM_LTM_Allwetterl_Status : 52|1@1+ (1.0,0.0) [0.0|1] ""  Gateway_Max
 SG_ BCM_LTM_PopUp_Status : 53|3@1+ (1.0,0.0) [0.0|7] ""  Gateway_Max
 SG_ BCM_LTM_Nebell_Status : 56|1@1+ (1.0,0.0) [0.0|1] ""  Gateway_Max
 SG_ BCM_LTM_PopUp_Anf : 57|3@1+ (1.0,0.0) [0.0|7] ""  Gateway_Max
 SG_ BCM_LTM_PopUp_Inhalt : 60|4@1+ (1.0,0.0) [0.0|15] ""  Gateway_Max

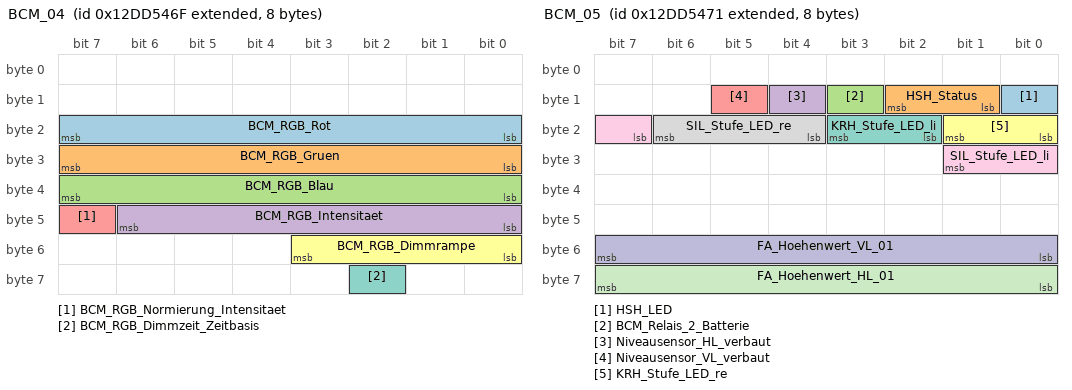
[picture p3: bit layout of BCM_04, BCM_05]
BO_ 2463978607 BCM_04: 8 BCM
 SG_ BCM_RGB_Rot : 16|8@1+ (1,0) [0|255] ""  Gateway_Max
 SG_ BCM_RGB_Gruen : 24|8@1+ (1,0) [0|255] ""  Gateway_Max
 SG_ BCM_RGB_Blau : 32|8@1+ (1,0) [0|255] ""  Gateway_Max
 SG_ BCM_RGB_Intensitaet : 40|7@1+ (1,0) [0|100] "Unit_PerCent"  Gateway_Max
 SG_ BCM_RGB_Normierung_Intensitaet : 47|1@1+ (1.0,0.0) [0.0|1] ""  Gateway_Max
 SG_ BCM_RGB_Dimmrampe : 48|4@1+ (0.25,0) [0.00|3.75] "Unit_Secon"  Gateway_Max
 SG_ BCM_RGB_Dimmzeit_Zeitbasis : 58|1@1+ (1.0,0.0) [0.0|1] ""  Gateway_Max

BO_ 2463978609 BCM_05: 8 BCM
 SG_ HSH_LED : 8|1@1+ (1.0,0.0) [0.0|1] ""  Gateway_Max
 SG_ HSH_Status : 9|2@1+ (1.0,0.0) [0.0|3] ""  Gateway_Max,TSGGen3_BFS,TSGGen3_FS
 SG_ BCM_Relais_2_Batterie : 11|1@1+ (1.0,0.0) [0.0|1] ""  Gateway_Max
 SG_ Niveausensor_HL_verbaut : 12|1@1+ (1.0,0.0) [0.0|1] ""  Gateway_Max
 SG_ Niveausensor_VL_verbaut : 13|1@1+ (1.0,0.0) [0.0|1] ""  Gateway_Max
 SG_ KRH_Stufe_LED_re : 16|2@1+ (1.0,0.0) [0.0|3] ""  Gateway_Max
 SG_ KRH_Stufe_LED_li : 18|2@1+ (1.0,0.0) [0.0|3] ""  Gateway_Max
 SG_ SIL_Stufe_LED_re : 20|3@1+ (1.0,0.0) [0.0|7] ""  Gateway_Max
 SG_ SIL_Stufe_LED_li : 23|3@1+ (1.0,0.0) [0.0|7] ""  Gateway_Max
 SG_ FA_Hoehenwert_VL_01 : 48|8@1+ (0.4,0) [0.0|100.0] "Unit_PerCent"  Gateway_Max
 SG_ FA_Hoehenwert_HL_01 : 56|8@1+ (0.4,0) [0.0|100.0] "Unit_PerCent"  Gateway_Max

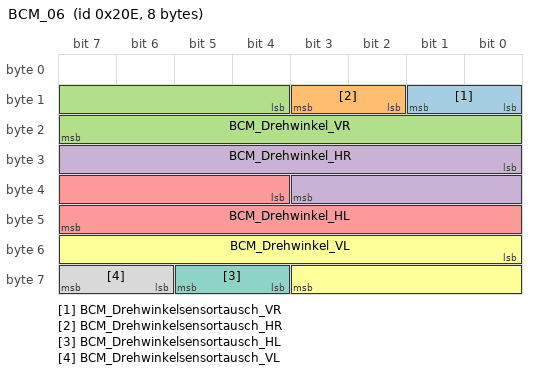
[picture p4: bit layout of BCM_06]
BO_ 526 BCM_06: 8 BCM
 SG_ BCM_Drehwinkelsensortausch_VR : 8|2@1+ (1,0) [1|3] ""  Gateway_Max
 SG_ BCM_Drehwinkelsensortausch_HR : 10|2@1+ (1,0) [1|3] ""  Gateway_Max
 SG_ BCM_Drehwinkel_VR : 12|12@1+ (0.088,0) [0.000|359.920] ""  Gateway_Max
 SG_ BCM_Drehwinkel_HR : 24|12@1+ (0.088,0) [0.000|359.920] ""  Gateway_Max
 SG_ BCM_Drehwinkel_HL : 36|12@1+ (0.088,0) [0.000|359.920] ""  Gateway_Max
 SG_ BCM_Drehwinkel_VL : 48|12@1+ (0.088,0) [0.000|359.920] ""  Gateway_Max
 SG_ BCM_Drehwinkelsensortausch_HL : 60|2@1+ (1,0) [1|3] ""  Gateway_Max
 SG_ BCM_Drehwinkelsensortausch_VL : 62|2@1+ (1,0) [1|3] ""  Gateway_Max

BO_TX_BU_ 2536767280 :BCM,TSGGen3_BFS,TSGGen3_FS;

CM_ "K2CANFD_V14.09F Generated by BusNet_NG_Produktiv 9.25.5";
CM_ BU_ BCM "Body Controller Module im MQBw_Baseline";
CM_ BU_ TSGGen3_BFS "TSG Gen3 Module";
CM_ BU_ TSGGen3_FS "TSG Gen3 Module";
CM_ BU_ TSGGen3_HBFS "TSG Gen3 Module";
CM_ BU_ TSGGen3_HFS "TSG Gen3 Module";
CM_ BU_ WLC_01_CFD "Wireless Charger 1 - Ladegerät 1 für mobile Endgeräte - Charger 1 Mobile Devices";

CM_ BO_ 1633 "ab MQB 7.2";

CM_ SG_ 2527679923 ADA_AttentionLevel "combined attention level";
CM_ SG_ 2527679923 ADA_DistractionLevel "combined distraction level";
CM_ SG_ 2527679923 ADA_DriverIsOperating "combined signal from all driver HMI inputs";
CM_ SG_ 2527679923 ADA_DrowsinessLevel "combined drowsiness level.";
CM_ SG_ 2527679923 ADA_DrowsinessSystemState "This signal contain the system state of the drowsiness detection of the customer driving function Attention and Drowsiness Assist (ADA).";
CM_ SG_ 2527679923 ADA_HMI_Ablenkung_Deaktivierung "This signal contain the deactivation notification of the distraction detection in form of a popup of the customer driving function Attention and Drowsiness Assist (ADA).";
CM_ SG_ 2527679923 ADA_HMI_Ablenkung_Fehler_Popup "This signal contain the different distraction detection error notifications in form of a popup of the customer driving function Attention and Drowsiness Assist (ADA).";
CM_ SG_ 2527679923 ADA_HMI_Ablenkung_Meldeakustik "This signal contain the information, if the different distraction detection notifications of the customer driving function Attention and Drowsiness Assist (ADA) should play with acoustic or without acoustic.";
CM_ SG_ 2527679923 ADA_HMI_Ablenkung_Meldung "This signal contain the different distraction detection notifications in form of a popup of the customer driving function Attention and Drowsiness Assist (ADA).";
CM_ SG_ 2527679923 ADA_HMI_Fahrzeit_seit_Pause "This signal contain the driving time since the last break of the driver.";
CM_ SG_ 2527679923 ADA_HMI_Muedigkeit_Deaktivierung "This signal contain the deactivation notification of the drowsiness detection in form of a popup of the customer driving function Attention and Drowsiness Assist (ADA).";
CM_ SG_ 2527679923 ADA_HMI_Muedigkeit_Event_Meldung "This signal contain the different drowsiness event notifications (e. g. yawning, microsleep, ...) in form of a popup of the customer driving function Attention and Drowsiness Assist (ADA).";
CM_ SG_ 2527679923 ADA_HMI_Muedigkeit_Fehler_Popup "This signal contain the different drowsiness detection error notifications in form of a popup of the customer driving function Attention and Drowsiness Assist (ADA).";
CM_ SG_ 2527679923 ADA_HMI_Muedigkeit_Meldeakustik "This signal contain the information, if the different drowsiness detection notifications of the customer driving function Attention and Drowsiness Assist (ADA) should play with acoustic or without acoustic.";
CM_ SG_ 2527679923 ADA_HMI_Muedigkeit_Meldung "This signal contain the different drowsiness detection notifications in form of a popup of the customer driving function Attention and Drowsiness Assist (ADA).";
CM_ SG_ 2527679923 ADA_Microsleep "microsleep detection";
CM_ SG_ 2527679923 ADA_TriggerEmergencyAssist "Signal dient zum Triggern des Emergency Assists durch ADA im Fall von einem unresponsed Driver";
CM_ SG_ 2527679923 ADA_Upcoming_Microsleep "Über das Signal wird der Zustand ausgegeben, ob der Fahrer kurz vor einem Sekundenschlaf steht";
CM_ SG_ 2527679923 SOK_ADA_01_Signatur "Signatur im Rahmen der durch SOK geschützen Broadcast-Kommunikation
";

CM_ SG_ 64 AB_Anzeige_Fussg "Anzeige für ausgelöste Fussgängerschutz-Aktuatorik";
CM_ SG_ 64 AB_Belegung_VF "Belegungserkennung vorne Fahrer.";
CM_ SG_ 64 AB_Crash_Int "Crash_Intensität_1 = fahrzeugabhängige Reaktionen im Crash
Crash_Intensität_2 = fahrzeugabhängige Reaktionen im Crash
Crash_Intensität_3 = fahrzeugabhängige Reaktionen im Crash

Die jeweiligen fahrzeugabhängigen Reaktionen im Crash sind in einem separ";
CM_ SG_ 64 AB_Deaktiviert "Airbag oder Gurtstraffer wurden per Anpassung deaktiviert: Aktualisierung erst nach Selbsttest";
CM_ SG_ 64 AB_Deaktivierung_HV "Deaktivierung des HV-Systems und der HV-Teilnehmer im Crash (u.a. Hybrid- und Elektrofahrzeuge)";
CM_ SG_ 64 AB_Diagnose "Airbag in Diagnose";
CM_ SG_ 64 AB_eCS_Error "Signal zur Anforderung der Anzeige von Störungen im System der elektrischen Gurtverriegelung";
CM_ SG_ 64 AB_EDR_Trigger "Triggerbedingung zur dezentralen Aufzeichnung unfallrelevanter Daten im Event Data Recorder";
CM_ SG_ 64 AB_Erh_Auf_VB "Der Fahrer soll bei einem Statuswechsel des Beifahrerairbags (ausgelöst durch die Beifahrerinsassenerkennung oder den Schlüsselschloßschalter) aufmerksam gemacht werden durch eine Anzeige im Kombi. Nur Audi: gültig für: AB2 (4-Türer AU352), B7, C6, D3";
CM_ SG_ 64 AB_Front_Crash "Bit wird bei Überschreitung der Gurtstraffer-, US- und RdW-Schwelle gesetzt";
CM_ SG_ 64 AB_Gurtschloss_FA_ext "Das Ergebnis der Basisfunktion 'Plausibilisierung Gurtschloss' des Verlassenskonzepts wird im Signal dargestellt.";
CM_ SG_ 64 AB_Gurtschloss_FA_ext_aktiv "Über dieses Signal wird signalisiert ob die Erweiterte Gurtdiagnose (Ergebnis wird im Signal AB_Gurtschloss_FA_ext dargestellt) aktiviert oder deaktiviert ist.";
CM_ SG_ 64 AB_Gurtwarn_VB "Beifahrer hat Gurt nicht gesteckt, Anzeige im Kombi";
CM_ SG_ 64 AB_Gurtwarn_VF "Fahrer hat Gurt nicht gesteckt, Anzeige im Kombi";
CM_ SG_ 64 AB_Heck_Crash "Wird für alle neu anlaufenden Projekte umgesetzt: AB8.4, Audi8/VW8";
CM_ SG_ 64 AB_Lampe "Sicherheitswarnlampe im Kombi wird vom Airbag-SG angesteuert; Zustand der Lampe wird auf dem CAN-Bus ausgegeben (auch Blinkinformation).";
CM_ SG_ 64 AB_MKB_Anforderung "Anforderung Multi-Kollisions-Bremsung";
CM_ SG_ 64 AB_MKB_gueltig "Multi-Kollisions-Bremsung im Airbag freigeschaltet";
CM_ SG_ 64 AB_PAO_Leuchte_Anf "Anforderung an die Passenger-Airbag-Off Leuchte in der Dachkonsole (ein / aus), Einsatz nur bei PAG";
CM_ SG_ 64 AB_RGS_Anst "PreCrash-Ansteuerung reversibler Gurtstraffer (Aktivierung und Kraftniveau)

10xx = deaktiviert";
CM_ SG_ 64 AB_Rollover_Crash "Wird im B6/B7 Cabrio und New Beetle Cabrio bedient. ";
CM_ SG_ 64 AB_SB_Crash "Z.Zt. nur in Verbindung mit Crash-Intensität >= 100b (Kraftstoffpumpenabschaltung) verwendet.
";
CM_ SG_ 64 AB_SF_Crash "Z.Zt. nur in Verbindung mit Crash-Intensität >= 100b (Kraftstoffpumpenabschaltung) verwendet.";
CM_ SG_ 64 AB_Stellgliedtest "Information, ob Airbag im Stellgliedtest ist, um eine Notrufauflösung beim Stellgliedtest zu verhindern";
CM_ SG_ 64 AB_Systemfehler "Systemfehler Ggf. wird Warnlampe dauernd eingeschaltet.";
CM_ SG_ 64 AB_Texte_AKS "Textanzeige für pyrotechnische Auslösung der aktiven Kopfstütze (AKS)";
CM_ SG_ 64 AB_VB_deaktiviert "Als Option vorgehalten, Beifahrerairbag wurden per Schlüsselschalter oder Insassenerkennung deaktiviert";
CM_ SG_ 64 AB_Versorgungsspannung "Übertragung der Plausibilitätsinformation Kl.15-Last vs. Kl.15-CAN.
Bedienung im Fall Kl.15-Last 'EIN' und Kl.15-CAN 'AUS' mit Ausgabe Warnung/Akustik im Kombi.";
CM_ SG_ 64 Airbag_01_CRC "Für MLB:
'Berechnung siehe Lastenheft 'Kommunikationsabsicherung für FlexRay und CAN''

Ab MQB und MLBevo:
'Berechnung siehe Lastenheft 'End-to-End Kommunikationsabsicherung''

Endwerte siehe Begleitdokument 'S-PDU Kennungsfolgen'";
CM_ SG_ 64 ASM_Masterzeit_02 "Masterzeit für alle ASM Sender";

CM_ SG_ 1312 AB_Abschaltanf_SIH_BF "Die Insassenerkennung auf der Beifahrerseite fordert bei Übertemperatur eine Abschaltung der Sitzheizung an. Die Übertemperatur kann bei niederohmigen Nebenschlüssen der Sitzheizungsmatte als Folge von zu hohem resultierenden Strom auftreten.";
CM_ SG_ 1312 AB_Anforderung_eCall "Trigger für Car2X Steuergerät das ein eCall Ereignis erkannt wurde.";
CM_ SG_ 1312 AB_Anforderung_USM "Trigger für Gateway (OBDC) und MIB/MMI, dass ein USM-Ereignis erkannt wurde.";
CM_ SG_ 1312 AB_Anprall_FGS "Uebermittlung der Lage einer Kollision, Fussgaengerschutz-Aktorik";
CM_ SG_ 1312 AB_Anprall_Front_Beifahrer "Uebermittlung der Lage einer Kollision, Anprallzone Front Beifahrerseite";
CM_ SG_ 1312 AB_Anprall_Front_Fahrer "Uebermittlung der Lage einer Kollision, Anprallzone Front Fahrerseite";
CM_ SG_ 1312 AB_Anprall_Heck_Beifahrer "Uebermittlung der Lage einer Kollision, Anprallzone Beifahrerseite hinten";
CM_ SG_ 1312 AB_Anprall_Heck_Fahrer "Uebermittlung der Lage einer Kollision, Anprallzone Fahrerseite hinten";
CM_ SG_ 1312 AB_Anprall_Rollover "Uebermittlung der Lage einer Kollision, Rollover erkannt";
CM_ SG_ 1312 AB_Anprall_Seite_Beifahrer "Uebermittlung der Lage einer Kollision, Anprallzone Beifahrerseite Seite";
CM_ SG_ 1312 AB_Anprall_Seite_Fahrer "Uebermittlung der Lage einer Kollision, Anprallzone Fahrerseite Seite";
CM_ SG_ 1312 AB_Belegung_VB "Belegungserkennung vorne Beifahrer. Wird in US-Steuergeräten über Bladder-Matte bedient, optional bei RdW, falls SBE_EuroNCAP entschieden wird.";
CM_ SG_ 1312 AB_Crashschwere "Übermittlung der Crashschwere an das Gateway (OBDC)";
CM_ SG_ 1312 AB_Gurtschloss_BF "Gurtschlossstatus Beifahrerseite";
CM_ SG_ 1312 AB_Gurtschloss_FA "Gurtschlosstatatus Fahrerseite";
CM_ SG_ 1312 AB_Gurtschloss_Reihe2_BF "Gurtschlossstatus 2. Reihe Beifahrerseite,  Mehrausstattung";
CM_ SG_ 1312 AB_Gurtschloss_Reihe2_FA "Gurtschlossstatus 2. Reihe Fahrerseite, Mehrausstattung";
CM_ SG_ 1312 AB_Gurtschloss_Reihe2_MI "Gurtschlossstatus 2. Reihe Mitte,  Mehrausstattung";
CM_ SG_ 1312 AB_Gurtschloss_Reihe3_BF "Gurtschlossstatus 3. Reihe Beifahrerseite,  Mehrausstattung";
CM_ SG_ 1312 AB_Gurtschloss_Reihe3_FA "Gurtschlossstatus 3. Reihe Fahrerseite,  Mehrausstattung";
CM_ SG_ 1312 AB_Gurtschloss_Reihe3_MI "Gurtschlossstatus 3. Reihe Mitte,  Mehrausstattung";
CM_ SG_ 1312 AB_Sitzpos_Sens_BF "Ausgabe Sitzposition Beifahrer";
CM_ SG_ 1312 AB_Sitzpos_Sens_FA "Ausgabe Sitzposition Fahrer";
CM_ SG_ 1312 AB_Wickelklappung_Reihe2_BF "Status Wickelklappung 2. Reihe Beifahrerseite, Mehrausstattung";
CM_ SG_ 1312 AB_Wickelklappung_Reihe2_FA "Status Wickelklappung 2. Reihe Fahrerseite, Mehrausstattung";
CM_ SG_ 1312 AB_Wickelklappung_Reihe2_MI "Status Wickelklappung 2. Reihe Mitte, Mehrausstattung";
CM_ SG_ 1312 Airbag_02_CRC "Für MLB:
'Berechnung siehe Lastenheft 'Kommunikationsabsicherung für FlexRay und CAN''

Ab MQB und MLBevo:
'Berechnung siehe Lastenheft 'End-to-End Kommunikationsabsicherung''

Endwerte siehe Begleitdokument 'S-PDU Kennungsfolgen'";
CM_ SG_ 1312 LoGeWa_Event_Kombiwarnung "Event für Kombiwarnung";
CM_ SG_ 1312 SC_PAO_OFF_Anf "Sollwert für LED 'OFF' in Anzeige Passenger Airbag On/Off";
CM_ SG_ 1312 SC_PAO_ON_Anf "Sollwert für LED 'ON' in Anzeige Passenger Airbag On/Off";
CM_ SG_ 1312 SC_PAO_Schriftzug_Anf "Sollwert für LED 'PASSENGER AIRBAG' in Anzeige Passenger Airbag On/Off";

CM_ SG_ 1349 AB_Anprall_Front "Uebermittlung der Lage einer Kollision, Anprallzone Front";
CM_ SG_ 1349 AB_Anprall_Heck "Uebermittlung der Lage einer Kollision, Anprallzone Heck";
CM_ SG_ 1349 AB_Belegung_VF_ext "Das Signal kommuniziert den Status des Sitzbelegsensors Fahrer incl. dauerhafter Zustände mit Signalqualität ASIL A.";
CM_ SG_ 1349 AB_Belegung_VF_ext_aktiv "Kennzeichnet aktive Funktion 'Erweiterte Sitzbelegdiagnose' für Signal AB_Belegung_VF_ext";
CM_ SG_ 1349 AB_Gurtwarn_Reihe2_BF "Status Gurtwarnung 2. Sitzreihe Beifahrerseite";
CM_ SG_ 1349 AB_Gurtwarn_Reihe2_FA "Status Gurtwarnung 2. Sitzreihe Fahrerseite";
CM_ SG_ 1349 AB_Gurtwarn_Reihe2_MI "Status Gurtwarnung 2. Sitzreihe Mitte";
CM_ SG_ 1349 AB_Gurtwarn_Reihe3_BF "Status Gurtwarnung 3. Sitzreihe Beifahrerseite";
CM_ SG_ 1349 AB_Gurtwarn_Reihe3_FA "Status Gurtwarnung 3. Sitzreihe Fahrerseite";
CM_ SG_ 1349 AB_Gurtwarn_Reihe3_MI "Status Gurtwarnung 3. Sitzreihe Mitte";
CM_ SG_ 1349 AB_Gurtwarn_Reihe4_BF "Status Gurtwarnung 4. Sitzreihe Beifahrerseite";
CM_ SG_ 1349 AB_Gurtwarn_Reihe4_FA "Status Gurtwarnung 4. Sitzreihe Fahrerseite";
CM_ SG_ 1349 AB_Gurtwarn_Reihe4_MI "Status Gurtwarnung 4. Sitzreihe Mitte";
CM_ SG_ 1349 AB_SBR_hinten_verbau "Verbauinformation Sitzbelegungssensor hinten (2. und 3. Sitzreihe)";
CM_ SG_ 1349 AbstWarn_MV_FAS_Fkt_Status "FAS-ProfileMaster Iststatus der Kundenfunktion";
CM_ SG_ 1349 Airbag_04_BZ "4bit Botschaftszähler, wird mit jeder Sendebotschaft inkrementiert";
CM_ SG_ 1349 Airbag_04_CRC "Für MLB:
Berechnung siehe Lastenheft 'Kommunikationsabsicherung für FlexRay und CAN'
Ab MQB und MLBevo:
Berechnung siehe Lastenheft 'End-to-End Kommunikationsabsicherung'

Endwerte siehe Begleitdokument 'S-PDU Kennungsfolgen'";
CM_ SG_ 1349 AWV_Einstellung_System_ASG "Signal zur Realisierung des BAP-Koordinators";
CM_ SG_ 1349 AWV_Einstellung_Warnung_ASG "Signal zur Realisierung des BAP-Koordinators";
CM_ SG_ 1349 LGI_FAS_Fkt_Status "FAS-ProfileMaster Iststatus der Kundenfunktion (LGI: Lokale Gefahreninformation)";
CM_ SG_ 1349 PreCrash_FAS_Fkt_Status "FAS-ProfileMaster Iststatus der Kundenfunktion";
CM_ SG_ 1349 SC_PreSense_Modus_System_KAS "BAP-Kommunikation zum Kreuzungsassistent";
CM_ SG_ 1349 SC_PreSense_Modus_System_MV "Signal zur Realisierung der BAP-Kommunikation für PreSense";
CM_ SG_ 1349 SC_PreSense_Modus_System_NV "Signal zur Realisierung der BAP-Kommunikation für PreSense";
CM_ SG_ 1349 SC_PreSense_Modus_Warnung_MV "Signal zur Realisierung der BAP-Kommunikation für PreSense";
CM_ SG_ 1349 SC_PreSense_Modus_Warnung_NV "Signal zur Realisierung der BAP-Kommunikation für PreSense";
CM_ SG_ 1349 WarnBrems_Charisma_FahrPr "Aktuell eingestelltes Fahrprogramm der Funktion Warn- und/oder Notbremsfunktion";
CM_ SG_ 1349 WarnBrems_Charisma_Status "Verfügbarkeit der Funktion Warn- und/oder Notbremsfunktion für die Ansteuerung durch den Charisma-Koordinator.";

CM_ SG_ 2527679722 AB_Anzeige_Kombi_SRAB "Status SRAB HMI";
CM_ SG_ 2527679722 AB_Anzeige_Komfort_HBFS "Komfortposition überschritten HBFS";
CM_ SG_ 2527679722 AB_Anzeige_Komfort_HFS "Komfortposition überschritten HFS";
CM_ SG_ 2527679722 AB_Anzeige_Sitz_Komfort_HBFS "Sitzdisplay Komfortposition überschritten HBFS";
CM_ SG_ 2527679722 AB_Anzeige_Sitz_Komfort_HFS "Sitzdisplay Komfortposition überschritten HFS";
CM_ SG_ 2527679722 AB_Gurtschloss_MI "Gurtschloss-Status 1. Reihe Mitte
Ersteinsetzer: T6PA";
CM_ SG_ 2527679722 AB_Gurtschloss_Reihe4_BF "Gurtschlossstatus 4. Reihe Beifahrerseite,  Mehrausstattung";
CM_ SG_ 2527679722 AB_Gurtschloss_Reihe4_FA "Gurtschlossstatus 4. Reihe Fahrerseite, Mehrausstattung";
CM_ SG_ 2527679722 AB_Gurtschloss_Reihe4_MI "Gurtschlossstatus 4. Reihe Mitte,  Mehrausstattung";
CM_ SG_ 2527679722 AB_Gurtwarn_VM "Beifahrer auf mittlerem Sitz (Nutzfahrzeug) hat Gurt nicht gesteckt, Anzeige im Kombi";
CM_ SG_ 2527679722 AB_Status_Sitz_SRAB_HBFS "Status SRAB Sitzdisplay HBFS";
CM_ SG_ 2527679722 AB_Status_Sitz_SRAB_HFS "Status SRAB Sitzdisplay HFS";
CM_ SG_ 2527679722 AB_wSBR_Batteriestatus "Anzeige einer schwachen Batterie in einer Sitzeinheit des wSBR-Systems im Kombi.";
CM_ SG_ 2527679722 Airbag_06_BZ "4bit Botschaftszähler, wird mit jeder Sendebotschaft inkrementiert";
CM_ SG_ 2527679722 Airbag_06_CRC "Für MLB:
Berechnung siehe Lastenheft 'Kommunikationsabsicherung für FlexRay und CAN'
Ab MQB und MLBevo:
Berechnung siehe Lastenheft 'End-to-End Kommunikationsabsicherung'

Endwerte siehe Begleitdokument 'S-PDU Kennungsfolgen'";

CM_ SG_ 1633 AAG_Anhaenger_abgesteckt "Anhaenger wurde bei Kl. 15 aus abgesteckt";
CM_ SG_ 1633 AAG_Anhaenger_erkannt "Erkennung Anhaenger ";
CM_ SG_ 1633 AAG_AVS_Fehler_02 "Fehler AVS";
CM_ SG_ 1633 AAG_AVS_Fehler_02_inv "Fehler AVS (inverses Signal)";
CM_ SG_ 1633 AAG_AVS_Stati "Status AVS (bei abnehmbarer oder mech.schwenkbarer Anhängerkupplung ist der Status immer 0)";
CM_ SG_ 1633 AAG_Blinker_H_aktiv "Status: Anhaenger Blinker aktiv";
CM_ SG_ 1633 AAG_Blinker_HL_def "Anhaenger Blinker links defekt";
CM_ SG_ 1633 AAG_Blinker_HR_def "Anhaenger Blinker rechts defekt";
CM_ SG_ 1633 AAG_Bremsl_durch_ECD "Bremslicht durch ECD aktiv";
CM_ SG_ 1633 AAG_Bremslicht_H_def "Anhaenger Bremslicht defekt";
CM_ SG_ 1633 AAG_Bremslicht_Reku "AAG_Bremslicht_Reku meldet zyklisch den empfangenen Zustand des CAN-Signals MO_Bremslicht_Reku zurück.";
CM_ SG_ 1633 AAG_BZ "4bit-Botschaftszaehler, wird in jeder Sendebotschaft inkrementiert

";
CM_ SG_ 1633 AAG_LED_aktiv "Dieses Signal sendet der Beleuchtungsart des Anhängers (LED oder Lampe)
Bei LED aktiv erfolgt kein Kaltüberwachung";
CM_ SG_ 1633 AAG_NSL_aktiv "Anhaenger Nebelschlusslicht aktiv";
CM_ SG_ 1633 AAG_Schlusslicht_HL_def "Anhaenger Schlußlicht links defekt";
CM_ SG_ 1633 AAG_Schlusslicht_HR_def "Anhaenger Schlußlicht rechts defekt";

CM_ SG_ 896 APS_Master_Sendestatus "Gibt den Sendestatus der Botschaft APS_Master an (notwendig für IL-Unterstützung)";
CM_ SG_ 896 US_ACC_CRC "Ab MQB und MLBevo:
'Berechnung siehe Lastenheft 'End-to-End Kommunikationsabsicherung''

Endwerte siehe Begleitdokument 'S-PDU Kennungsfolgen'";
CM_ SG_ 896 US_blindness_detected "US erkennt selbständig eigene Blindheit durch äußere Einflüsse.";
CM_ SG_ 896 US_Freie_Weglaenge_Front "US_Freie Weglaenge vor dem Fahrzeug - lenkwinkelabhängig. Die freie Weglänge kann dabei durch Hindernisse oder den maximalen Sichtbereich beschränkt sein. Siehe Signal US_Freie_Weglaenge_Front_Typ";
CM_ SG_ 896 US_Freie_Weglaenge_Front_Typ "Beschreibt die Begrenzung der freien Weglänge vor dem Fahrzeug. Gehört somit zum Signal US_Freie_Weglaenge_Front. Die freie Weglänge kann bei einem gemessenen Objekt enden oder bei der maximalen Sensorreichweite.";
CM_ SG_ 896 US_Freie_Weglaenge_Heck "Gibt lenkwinkelabhängig einen Abstand hinter dem Fahrzeug aus. Dabei kann der Abstand entweder den Abstand zu einem Hindernis oder den maximalen Sichtbereich darstellen. Zur Unterscheidung Hindernis oder maximaler Sichtbereich siehe Signal US_Freie_Weglae";
CM_ SG_ 896 US_Freie_Weglaenge_Heck_Typ "US_Freie_Weglaenge_Typ gibt an, ob es sich bei dem Signal US_Freie_Weglaenge_Heck um ein gemessenes Objekt handelt oder um die maximale Sensorreichweite. Gehört somit zum Signal US_Freie_Weglaenge_Front";
CM_ SG_ 896 US_Freisicht_nio "Blindheitserkennung
Nach KL15-Ein konnte Freisichtprüfung noch nicht erfüllt werden";
CM_ SG_ 896 US_relevante_Nichtverfuegbarkeit "US erkennt eine Nichtverfuegbarkeit, die Objektdetektion im Frontbereich betreffend, ohne FSP-Eintrag";
CM_ SG_ 896 US_relevanter_Fehler "US erkennt einen Fehler, die Objektdetektion im Frontbereich betreffend, mit FSP-Eintrag.";
CM_ SG_ 896 US_Sende_Modus "US=Ultraschall
US_SendeModus:
0x0: keine für das ACC-SG relevanten Abstandswerte werden gesendet
0x1: 4K ext. range, 10 Signalwege verfügbar ('4m')
0x2: 4K norm. range, 10 Signalwege verfügbar ('2m')
0x3: 6K ext. range, 16 Signalwege verfügbar ('4m')";
CM_ SG_ 896 US_Sende_Modus_hinten "US=Ultraschall
US_Sende_Modus_hinten:
0x0: keine für das ACC-SG relevanten Abstandswerte werden gesendet
0x1....0x4: frei
0x5: 2-K. ext. range (PLA), 2 Signalwege verfügbar ('4m')
0x6: Modeumschaltung (ext -> norm oder norm -> ext)
0x7: Blindheitspr";

CM_ SG_ 345 ARA_Aktiver_Grafikmodus "Zeigt an  das eine Grafik für ARA aktiviert werden soll";
CM_ SG_ 345 ARA_Bremsfuss "Anforderung des Bremsfusssymbols im Kombi";
CM_ SG_ 345 ARA_Deaktivierung_sperren "Unterdrückt die Deaktivierung der ARA- Visualisierung";
CM_ SG_ 345 ARA_Knickwinkel_Ist "Gibt den aktuellen Knickwinkel zwischen Anhänger und Fahrzeug wieder";
CM_ SG_ 345 ARA_Knickwinkel_Komfort "Knickwinkelgrenze bis zu der, bei maximalem Lenkeinschlag, eine sofortige gerade Rückwärtsfahrt möglich ist.";
CM_ SG_ 345 ARA_Knickwinkel_Konfidenz "irregular trailer angle area value for HMI display";
CM_ SG_ 345 ARA_Knickwinkel_Max "Gibt den maximalen ausregelbaren Knickwinkel zwischen Anhänger und Fahrzeug wieder.";
CM_ SG_ 345 ARA_Knickwinkel_Soll "Vom Fahrer vorgegebener Knickwinkel.";
CM_ SG_ 345 ARA_Modus "Regelmodus ARA für Kombidarstellung";
CM_ SG_ 345 ARA_Modus_Anf "Anforderung des ARA-Modus im Türsteuergerät";
CM_ SG_ 345 ARA_Sensor_Aktivierung "activation  of ARA IP (image processing)";
CM_ SG_ 345 ARA_Status "Status of ARA Controller";
CM_ SG_ 345 ARA_Texte "Anforderung für Kombianzeigetexte und Akustik";

CM_ SG_ 2527679661 AWV_AW_Abstand "Signal dient zur Anzeige des Abstands im Kombi.";
CM_ SG_ 2527679661 AWV_AW_Texte "Signal zur Ansteuerung von Fahrer- und Warnhinweisen des Abstandswarners im Mitteldisplay";
CM_ SG_ 2527679661 AWV_AW_Texte_Zusatzanzeige "Signal zur Ansteuerung von Fahrer- und Warnhinweisen des Abstandswarners im Mitteldisplay";
CM_ SG_ 2527679661 AWV_AW_Zeitluecke "Anzeige der aktuellen Zeitluecke zum vorausfahrenden Fahrzeug (AW == Abstandswarner)";
CM_ SG_ 2527679661 AWV_Einstellung_System_FSG "Signal zur Realisierung des BAP-Koordiantors";
CM_ SG_ 2527679661 AWV_Einstellung_Warnung_FSG "Signal zur Realisierung des BAP-Koordinators";
CM_ SG_ 2527679661 AWV_KA_Konfiguration "Systemstatus Bedienung vom Kreuzungsassistent zum PaCo.";
CM_ SG_ 2527679661 AWV_KA_ObjektFront "Anforderung der MIB Parkenanzeige vom Kreuzungsassistent zum PaCo.";
CM_ SG_ 2527679661 AWV_Kamera_Objekt_ID "Kamera Objekt-ID des AWV-Zielobjekts";
CM_ SG_ 2527679661 AWV_LED_Leiste "Ansteuerung LED Warnleiste";
CM_ SG_ 2527679661 AWV_Priowarnung "Priorisierung der AWV-Warnung über die Spurverlassensanzeige des HCA";
CM_ SG_ 2527679661 AWV_Status_Anzeige "Signal zur Realisierung des BAP-Koordiantors
Signal identisch zu AWV_BAP_Status 
Kl15 aus: nicht bereitgestellt.";
CM_ SG_ 2527679661 AWV_Texte_02 "Hinweisanzeige im Kombi 'Hauptdisplay'
Wert 6 - Eingeschränkte Verfügbarkeit der weiteren Fusionsteilnehmer (z.B. MFK, FER)";
CM_ SG_ 2527679661 AWV_Warnlevel "Warnlevel der Funktion Anhaltewegverkürzung";
CM_ SG_ 2527679661 AWV_Warnung "Hinweisanzeige im Kombi 'Hauptdisplay'";
CM_ SG_ 2527679661 AWV_Warnung_Richtung "Zusätzliche Richtungsanzeige zum Signal AWV_Warnung für die Darstellung im Smartlight und HUD.";
CM_ SG_ 2527679661 WBA_Warnblinken "Ansteuerung des Warnblinkers für die Funktion Warnen, Bremsen, Ausweichen";

CM_ SG_ 2463978752 AZK_Kessy_defekt "Signalisierung der Kessy-Meldung 'Kessy defekt' vom AZK an ein Anzeigeinstrument (Kombiinstrument, I-ID etc.)";
CM_ SG_ 2463978752 AZK_Kessy_nicht_gefunden "Signalisierung der Kessy-Meldung 'Kessy nicht gefunden' vom AZK an ein Anzeigeinstrument (Kombiinstrument, I-ID etc.)";
CM_ SG_ 2463978752 AZK_MobileKey_defekt "Signalisierung der DKM-Meldung 'System Mobile Key defekt' vom AZK an ein Anzeigeinstrument (Kombiinstrument, I-ID etc.)";
CM_ SG_ 2463978752 AZK_Mobilgeraet_nicht_gefunden "Signalisierung der DKM-Meldung 'Mobilgerät nicht gefunden' vom AZK an ein Anzeigeinstrument (Kombiinstrument, I-ID etc.)";
CM_ SG_ 2463978752 AZK_Schluessel_im_Fzg "Signalisierung der Kessy-Meldung 'Schlüssel im Fahrzeug' vom AZK an ein Anzeigeinstrument (Kombiinstrument, I-ID etc.)";
CM_ SG_ 2463978752 AZK_Schluessel_nicht_gefunden "Signalisierung der Meldung 'Schluessel nicht gefunden' der AZK SW-Unit im MDK-ZuKo an ein Anzeigeinstrument (Kombiinstrument, I-ID etc.)";
CM_ SG_ 2463978752 AZK_Weiterfahrt_mit_Mobilgeraet "Signalisierung der DKM-Meldung 'Weiterfahrt mit Mobilgerät möglich' vom AZK an ein Anzeigeinstrument (Kombiinstrument, I-ID etc.)";
CM_ SG_ 2463978752 AZK_Weiterfahrt_mit_Schluessel "Signalisierung der Kessy-Meldung 'Weiterfahrt mit Schlüssel möglich' vom AZK an ein Anzeigeinstrument (Kombiinstrument, I-ID etc.)";

CM_ SG_ 2536704257 BAP_Aussenlicht_ASG_02_Header "Aussenlicht Anzeigesteuergeraet";

CM_ SG_ 2536726786 BAP_Car2X_ASG_03_Header "Car2X-Objekte Anzeigesteuergerät3";

CM_ SG_ 2536726802 BAP_Car2X_FSG_03_Header "Car2X-Objekte Funktionssteuergeraet";

CM_ SG_ 2536727296 BAP_Doors2_ASG_01_Header "BAP Strecke für Tür Beifahrerseite
Anzeigesteuergerät
(Im-/Export PSO2.0)";

CM_ SG_ 2536727312 BAP_Doors2_FSG_01_Header "BAP Strecke für Tür Beifahrerseite
Funktionssteuergerät
(Im-/Export PSO2.0)";

CM_ SG_ 2536724736 BAP_Doors_ASG_01_Header "Doors
Anzeigesteuergerät";

CM_ SG_ 2536724752 BAP_Doors_FSG_01_Header "BAP Strecke für Türen
Funktionssteuergerät
(Im-/Export PSO2.0)";

CM_ SG_ 2536724480 BAP_ENI2_ASG_01_Header "zweite Instanz für ENI für Online-Update für DDA
zweite FSG-Botschaft (DDA)";

CM_ SG_ 2536724481 BAP_ENI2_ASG_02_Header "zweite Instanz für ENI für Online-Update für DDA
zweite ASG-Botschaft (MIB)";

CM_ SG_ 2536724496 BAP_ENI2_FSG_01_Header "zweite Instanz für ENI für Online-Update für DDA
zweite FSG-Botschaft (DDA)";

CM_ SG_ 2536724497 BAP_ENI2_FSG_02_Header "zweite Instanz für ENI für Online-Update für DDA
zweite FSG-Botschaft (DDA)";

CM_ SG_ 2536707072 BAP_Homelink_ASG_01_Header "Homelink Anzeigesteuergeraet";

CM_ SG_ 2536707088 BAP_Homelink_FSG_01_Header "Homelink Funktionssteuergeraet";

CM_ SG_ 2536722946 BAP_IAA_PSO_ASG_03_Header "BAP Strecke für IAA & PSO
Anzeigesteuergeräte BCM";

CM_ SG_ 2536722960 BAP_IAA_PSO_FSG_01_Header "BAP Strecke für IAA & PSO";

CM_ SG_ 2536704001 BAP_Innenlicht_ASG_02_Header "Innenlicht Anzeigesteuergeraet 2";

CM_ SG_ 2536704003 BAP_Innenlicht_ASG_04_Header "Innenlicht Anzeigesteuergeraet4";

CM_ SG_ 2536705537 BAP_Mirror_ASG_02_Header "Mirror Anzeigesteuergeraet";

CM_ SG_ 2536732416 BAP_MobDevKey_ASG_01_Header "MobDevKey Anzeigesteuergeraet 01";

CM_ SG_ 2536732417 BAP_MobDevKey_ASG_02_Header "MobDevKey Anzeigesteuergeraet 02";

CM_ SG_ 2536732432 BAP_MobDevKey_FSG_01_Header "MobDevKey Funktionssteuergeraet 01";

CM_ SG_ 2536734464 BAP_MobDevKeyOnline_ASG_01_Heade "MobDevKeyOnline Anzeigesteuergeraet 01";

CM_ SG_ 2536734480 BAP_MobDevKeyOnline_FSG_01_Heade "MobDevKeyOnline Funktionssteuergeraet 01";

CM_ SG_ 2536704517 BAP_OPS_ASG_06_Header "OPS Anzeigesteuergeraet 6";

CM_ SG_ 2536721920 BAP_RemoteServices_ASG_01_Header "RemoteServices Anzeigesteuergeraet";

CM_ SG_ 2536721921 BAP_RemoteServices_ASG_02_Header "RemoteServices Anzeigesteuergeraet";

CM_ SG_ 2536721936 BAP_RemoteServices_FSG_01_Header "RemoteServices Funktionssteuergeraet";

CM_ SG_ 2536731904 BAP_RollingAbility_ASG_01_Header "RollingAbility ASG-Botschaft";

CM_ SG_ 2536731920 BAP_RollingAbility_FSG_01_Header "RollingAbility FSG-Botschaft";

CM_ SG_ 2536730624 BAP_RSO_ASG_01_Header "RemoteStartOnline ASG1-Botschaft";

CM_ SG_ 2536730640 BAP_RSO_FSG_01_Header "RemoteStartOnline FSG-Botschaft";

CM_ SG_ 2536717057 BAP_SeatPneumatic_ASG_02_Header "Bap für SeatPneumatic";

CM_ SG_ 2536705025 BAP_Wiper_ASG_02_Header "Wiper Anzeigesteuergeraet";

CM_ SG_ 2583694872 BCM1_AuthTime_Req_Data "AuthTime - Authentische Zeit
ISO-TP Datenkanal - NA2FID

BCM1 an Funktion Authentische Zeit (Request)";

CM_ SG_ 2583825944 BCM1_AuthTime_Resp_Data "AuthTime - Authentische Zeit
ISO-TP Datenkanal - NA2FID
Response Funktion 0x18 AuthTime

Funktion Authentische Zeit an BCM1 (Transceiver Modul) (Response)";

CM_ SG_ 2527679636 BCM1_DML_AbbiegeWa_Variante "Gibt die Variante der DML Abbiegewarnung an.";
CM_ SG_ 2527679636 BCM1_DML_AbsAss_Variante "Gibt die Variante des DML Abstandsassistenten an.";
CM_ SG_ 2527679636 BCM1_DML_AccAss_Variante "Gibt die Variante des DML ACC-Assistenten an.";
CM_ SG_ 2527679636 BCM1_DML_aCH_Variante "Gibt die advanced CH Variante des DML an";
CM_ SG_ 2527679636 BCM1_DML_aLH_Variante "Gibt die advanced LH Variante des DML an";
CM_ SG_ 2527679636 BCM1_DML_Aussteigelicht_aktiv "Gibt die De-/Aktivierung des Aussteigelichts für das DML an.";
CM_ SG_ 2527679636 BCM1_DML_BauLi_Variante "Gibt die Variante des Baustellenlichts für das DML an.";
CM_ SG_ 2527679636 BCM1_DML_BeAss_Variante "Gibt die Variante des DML Beschleunigungsassistenten an.";
CM_ SG_ 2527679636 BCM1_DML_EffAss_Variante "Gibt die Variante des DML Effizienzassistenten an.";
CM_ SG_ 2527679636 BCM1_DML_Einsteigelicht_aktiv "Gibt die De-/Aktivierung des Einsteigelichts für das DML an.";
CM_ SG_ 2527679636 BCM1_DML_Fahrbereit "Gibt den Fahrbereitschaftsstatus für das DML an.";
CM_ SG_ 2527679636 BCM1_DML_Lichtassistenz_aktiv "Gibt die De-/Aktivierung der Lichtassistenz für das DML an.";
CM_ SG_ 2527679636 BCM1_DML_Lichtfuehrung_aktiv "Gibt die De-/Aktivierung der Lichtführung für das DML an.";
CM_ SG_ 2527679636 BCM1_DML_PreSAss_Variante "Gibt die Variante des DML PreSense-Assistenten an.";
CM_ SG_ 2527679636 BCM1_DML_RouLi_Variante "Gibt die Variante des Routenlichts für das DML an.";
CM_ SG_ 2527679636 BCM1_DML_SitLi_Variante "Gibt die Variante des Situationslichts für das DML an.";
CM_ SG_ 2527679636 BCM1_DML_SpuLi_Variante "Gibt die Variante des Spurlichts für das DML an.";
CM_ SG_ 2527679636 BCM1_DML_TraLi_Variante "Gibt die Variante des Trajektorienlichts für das DML an.";

CM_ SG_ 1626 APS_Tongeber_defekt "Status APS-Tongeber zur HMI-Ansteuerng der RCTA-Funktion";
CM_ SG_ 1626 BCM1_AFS_Lampe "Ansteuerung der AFS-Fehlermeldung im Kombi";
CM_ SG_ 1626 BCM1_EasyEntry_Status "Status EasyEntry für Lenksäule (wird auch von IVB verwendet)";
CM_ SG_ 1626 BCM1_Fahrlicht_Hinweis "Signal zum Kombi um den Hinweis 'Bitte Fahrlicht einschalten' anzufordern";
CM_ SG_ 1626 BCM1_Hinweis_Lichtnachlauf "Signal dient der Anzeige eines aktiven Lichtnachlaufes beim automatischen Abschalten der Klemme S und Klemme 15. Der Lichtnachlauf wird gestartet, wenn die Klemme 15 bei aktivem Fahrlicht deaktiviert wird.";
CM_ SG_ 1626 BCM1_Kl_15_HW_erkannt "Erkennung Klemme 15 (Hardware) vom BCM1
";
CM_ SG_ 1626 BCM1_Kl_15_Sig_HW_erkannt "Erkennung Klemme 15 Signal (Hardware) vom BCM1";
CM_ SG_ 1626 BCM1_LDS_Stellung "Das Signal wird vom AFS / LWR Steuergerät empfangen und dient der Verifizierung der Lichtdrehschalterstellung. Intelligente Lichtfunktionen wie dyn. KL und gleitende Leuchtweite (GLW) nur bei LDS = 'AUTO'.";
CM_ SG_ 1626 BCM1_Lenksaeule_aktiv "Lenksaeulenverstellung aktiv";
CM_ SG_ 1626 BCM1_Licht_Warn "Lichtwarnung";
CM_ SG_ 1626 BCM1_Lichtwarn_Texte "Anforderung von Lichtwarnungen vom BCM1 zum Kombi
MLB: nur Werte 0..2";
CM_ SG_ 1626 BCM1_MH_Schalter "Motorhaubenkontakt";
CM_ SG_ 1626 BCM1_MH_WIV_Schalter "Bewerteter Motorhaubenkontakt fuer WIV";
CM_ SG_ 1626 BCM1_NV_Taster "BCM1_NV_Taster gibt an, ob der NightVision-Taster im Lichtdrehschalter-Modul aktuell betaetigt wird.";
CM_ SG_ 1626 BCM1_Reisemodus_Texte "Ansteuerung der Reisemodus-Texte im Kombi";
CM_ SG_ 1626 BCM1_Rueckfahrlicht_Schalter "Rückfahrlichtschalter
ab MQB/ MLBevo: Die Ganginformation wird unentprellt übertragen, im AT-Getriebe wird evtl. kurzzeitig der R-Gang angezeigt. Eine Entprellung muß im Empfänger erfolgen (typisch 400ms).";
CM_ SG_ 1626 BCM1_Spannungs_Anf "Forderung des BCM1-SG's zur Spannungsanhebung.";
CM_ SG_ 1626 BCM1_Valet_Parking_Taster "Valet Parking Taster ";
CM_ SG_ 1626 BCM1_Warnblink_Taster "Warnblinktaster";
CM_ SG_ 1626 BCM_Anf_AAW_MoLaWa "Signal zur Anforderung der Antrieb-Aktiv-Warnung und Motorlaufwarnung. Die Berechnung erfolgt im BCM. Die Ausgabe der Warnungen wird vom Kombiinstrument realisiert";
CM_ SG_ 1626 BCM_Bremsbelag_Sensor "Sensorsignal der Stromschleife  für Bremsbelagverschleiß aktuell, entstört, unbewertet";
CM_ SG_ 1626 BCM_Bremsfluessigkeit_Sensor "Kontaktsignal des Sensorschalters für die Bremsflüssigkeitsreserve aktuell, entstört, unbewertet";
CM_ SG_ 1626 BCM_Charisma_Taste2 "Betätigung der Charisma-Taste 2";
CM_ SG_ 1626 BCM_Eco_Charisma_Taste "Betätigung Taster ECO alias BlueKey oder Charisma";
CM_ SG_ 1626 BCM_Handbremse_Hinweis "Infotext fuer das Kombiinstrument zur Oeffnung der elektr. Heckklappe.";
CM_ SG_ 1626 BCM_HBFS_EOE_aktiv "Elektrisch-Oeffnen-Motor aktiv";
CM_ SG_ 1626 BCM_HDF_betaetigt "Betätigung Taster für Heckdeckelfernentriegelung in Mittelkonsole";
CM_ SG_ 1626 BCM_HFS_EOE_aktiv "Elektrisch-Oeffnen-Motor aktiv";
CM_ SG_ 1626 BCM_Hybrid_StartStopp_Taste "Betaetigung Taster 'Hybrid' oder alternativ Taster 'Start/Stopp Deaktivierung', je nach Verbau";
CM_ SG_ 1626 BCM_Hybrid_StSt_Taste_Fehler "Fehlerflag, wenn Tasterdiagnose im BCM für den StSt-Taster anschlägt.";
CM_ SG_ 1626 BCM_Kuehlmittel_Sensor "Signal der Sensorelektroden für die Kühlmittelreserve aktuell, entstört, bewertet (OK/Mangel)";
CM_ SG_ 1626 BCM_Kuehlmittel_Sensor_02 "Signal der zweiten Sensorelektroden für die Kühlmittelreserve aktuell, entstört, bewertet (OK/Mangel)";
CM_ SG_ 1626 BCM_Offroad_Taste "Betätigung der Offroad-Taste";
CM_ SG_ 1626 BCM_ValetTaster_Fkts_LED "Im MQB beschreibt das Signal nur den Zustand der Funktion Valet Parking (aktiv/ inaktiv)
Im MLBevo wird über das Signal zusätzlich die ValetTaster_Fkts_LED (an/ aus) gesteuert";
CM_ SG_ 1626 BCM_Waehlhebel_P_Hinweis "Infotext NAR für die Vorbedingung 'Waehlhebel in P' für Öffnen der Heckklappe über den Fahrerrauminnentaster.";
CM_ SG_ 1626 BCM_Waschwasser_Sensor "Signal der Sensorelektroden für die Waschwasserreserve aktuell, entstört, bewertet (OK/Mangel)";
CM_ SG_ 1626 DWA_Alarmquelle "Signalisiert den Auslösegrund der DWA";
CM_ SG_ 1626 DWA_Einschraenkung "Signalisiert Fehler der DWA";
CM_ SG_ 1626 Gong_TFL_Umschaltung "Aktivierung / Deaktivierung des TFL per Affengriff wird mit einem Gong im Kombi quittiert.";
CM_ SG_ 1626 LRH_Taster "Tasterbetätigung Lenkradheizung";

CM_ SG_ 2527679637 BCM_anf_VLW "Über dieses Signal wird die vom BCM errechnete Verlassenswarnung sowie die Meldung eines aktiven Rollfaehigkeitsmodus zur Ausgabe durch das Kombinstrument angefordert.";
CM_ SG_ 2527679637 BCM_Defrost_Taste "Defrost AN/AUS und Status";
CM_ SG_ 2527679637 BCM_FAS_Taster "Betätigung des FAS-Tasters Schalterleiste.";
CM_ SG_ 2527679637 BCM_FSH_Taste "Frontscheibenheizung AN/AUS und Status";
CM_ SG_ 2527679637 BCM_HSH_Taste "Heckscheibenheizung AN/AUS und Status";
CM_ SG_ 2527679637 BCM_LTM_Allwetterl_Status "Allwetterlicht Status zur Anzeige im Allwetterlicht-PopUp";
CM_ SG_ 2527679637 BCM_LTM_Nebell_Status "Nebellicht Status zur Anzeige im Nebellicht-PopUp";
CM_ SG_ 2527679637 BCM_LTM_Nebelschluss_Status "Nebelschlusslicht Status zur Anzeige im Nebelschlusslicht-PopUp";
CM_ SG_ 2527679637 BCM_LTM_PopUp_Anf "Anforderung der entsprechenden Anzeige im Kombi bei Aussenlichtsteuerung über LTM (LichtTastenModul)";
CM_ SG_ 2527679637 BCM_LTM_PopUp_Inhalt "Definition Inhalt des PopUps zur Aussenlichtbedienung";
CM_ SG_ 2527679637 BCM_LTM_PopUp_Status "Auswahl der aktiven Aussenlichtfunktion im LTM PopUp";
CM_ SG_ 2527679637 BCM_LTM_PopUp_Texte "Anforderung Kombi-Texte bei Bedienung Aussenlicht über LTM (LichtTastenModul)";
CM_ SG_ 2527679637 CPD_Warnung "Ansteuerung einer Warnung im Kombi/ iID mit Ton oder ohne Ton durch die Fkt. ChildPresenceDetection";
CM_ SG_ 2527679637 LiSi_Touch_Event "Touch_Events für Informationen einer Funktionsauslösung auf der LiSi, welches dann für bspw. ein akustiches Signal zentral umgesetzt werden können.";
CM_ SG_ 2527679637 LTMs_01_alt "Veraltet-Bit für den LIN-Frame LTMs_01";
CM_ SG_ 2527679637 MiKo_Tisch_Positionswarnung "Positionswarnung des Tisches in der Mittelkonsole";

CM_ SG_ 2463978607 BCM_RGB_Blau "Farbanteil 'Blau'";
CM_ SG_ 2463978607 BCM_RGB_Dimmrampe "Vorgabe 'Dimmzeit' für RGB-Slave";
CM_ SG_ 2463978607 BCM_RGB_Dimmzeit_Zeitbasis "Umschaltung der Zeitbasis für die Berechnung der Dimmzeit zwischen 250ms (Altwert, log. Signalwert: 1) und 50ms (log. Signalwert: 0)";
CM_ SG_ 2463978607 BCM_RGB_Gruen "Farbanteil 'Grün'";
CM_ SG_ 2463978607 BCM_RGB_Intensitaet "Intensität für RGB-Slave";
CM_ SG_ 2463978607 BCM_RGB_Normierung_Intensitaet "Normierung der Intensität für die RGB-Slaves:
0 = keine Normierung
1 = Normierung";
CM_ SG_ 2463978607 BCM_RGB_Rot "Farbanteil 'Rot'";

CM_ SG_ 2463978609 BCM_Relais_2_Batterie "Zeigt den Zustand des vom BCM bzw KFG angesteuerten Laderelais einer verbauten 2. Batterie an";
CM_ SG_ 2463978609 FA_Hoehenwert_HL_01 "Aktueller Höhenwert (Rohwerte) Hinten Links; ungefiltertes Signal
Einheit, Offset und Faktor sind abhänig von 'FA_Hoehenwert_kalibriert'";
CM_ SG_ 2463978609 FA_Hoehenwert_VL_01 "Aktueller Höhenwert (Rohwerte) Vorne Links; ungefiltertes Signal
Einheit, Offset und Faktor sind abhänig von 'FA_Hoehenwert_kalibriert'";
CM_ SG_ 2463978609 HSH_LED "LED Ansteuerung Heckscheibenheizung";
CM_ SG_ 2463978609 HSH_Status "Status Heckscheibenheizung
";
CM_ SG_ 2463978609 KRH_Stufe_LED_li "Statusmeldung Kopfraumheizung links";
CM_ SG_ 2463978609 KRH_Stufe_LED_re "Statusmeldung Kopfraumheizung rechts";
CM_ SG_ 2463978609 Niveausensor_HL_verbaut "Signal wird gesetzt, wenn Niveausensor_hinten codiert wird.";
CM_ SG_ 2463978609 Niveausensor_VL_verbaut "Signal wird gesetzt, wenn Niveausensor_vorne codiert wird.";
CM_ SG_ 2463978609 SIL_Stufe_LED_li "Statusmeldung Sitzlüftung links";
CM_ SG_ 2463978609 SIL_Stufe_LED_re "Statusmeldung Sitzlüftung rechts";

CM_ SG_ 526 BCM_Drehwinkel_HL "Drehwinkelsensor zur Berechnung von Dämpferweg und  für LWR";
CM_ SG_ 526 BCM_Drehwinkel_HR "Drehwinkelsensor zur Berechnung von Dämpferweg und  für LWR";
CM_ SG_ 526 BCM_Drehwinkel_VL "Drehwinkelsensor zur Berechnung von Dämpferweg und  für LWR";
CM_ SG_ 526 BCM_Drehwinkel_VR "Drehwinkelsensor zur Berechnung von Dämpferweg und  für LWR";
CM_ SG_ 526 BCM_Drehwinkelsensortausch_HL "Zähler der bei jedem erkannten Drehwinkelsensortausch inkrementiert wird. Systeme die den Drehwinkelwert empfangen können notwendigen Inbetriebnahmefunktionen starten";
CM_ SG_ 526 BCM_Drehwinkelsensortausch_HR "Zähler der bei jedem erkannten Drehwinkelsensortausch inkrementiert wird. Systeme die den Drehwinkelwert empfangen können notwendigen Inbetriebnahmefunktionen starten";
CM_ SG_ 526 BCM_Drehwinkelsensortausch_VL "Zähler der bei jedem erkannten Drehwinkelsensortausch inkrementiert wird. Systeme die den Drehwinkelwert empfangen können notwendigen Inbetriebnahmefunktionen starten";
CM_ SG_ 526 BCM_Drehwinkelsensortausch_VR "Zähler der bei jedem erkannten Drehwinkelsensortausch inkrementiert wird. Systeme die den Drehwinkelwert empfangen können notwendigen Inbetriebnahmefunktionen starten";

BA_DEF_  "DBName" STRING;
BA_DEF_  "GenNWMApBusSleep" STRING;
BA_DEF_  "GenNWMApCanNormal" STRING;
BA_DEF_  "GenNWMApCanOff" STRING;
BA_DEF_  "GenNWMApCanOn" STRING;
BA_DEF_  "GenNWMApCanSleep" STRING;
BA_DEF_  "GenNWMApCanWakeUp" STRING;
BA_DEF_  "GenNWMGotoMode_Awake" STRING;
BA_DEF_  "GenNWMGotoMode_BusSleep" STRING;
BA_DEF_  "GenNWMSleepTime" INT 0 1000000;
BA_DEF_  "GenNWMTalkNM" STRING;
BA_DEF_  "Manufacturer" STRING;
BA_DEF_  "NmhBaseAddress" HEX 0 536870911;
BA_DEF_  "NmhMessageCount" INT 0 1024;
BA_DEF_  "NmType" STRING;
BA_DEF_  "VAGTP20_SetupMessageCount" INT 0 255;
BA_DEF_  "VAGTP20_SetupStartAddress" HEX 0 2047;
BA_DEF_  "VersionDay" INT 1 31;
BA_DEF_  "VersionMonth" INT 1 12;
BA_DEF_  "VersionWeek" INT 1 52;
BA_DEF_  "VersionYear" INT 0 99;
BA_DEF_  "VersionNumber" INT 0 65535;
BA_DEF_  "BusType" STRING;
BA_DEF_  "Baudrate" INT 1 1000000;
BA_DEF_  "BaudrateCANFD" INT 1 16000000;
BA_DEF_  "NmhTimeoutTimer" INT 0 65535;
BA_DEF_  "NmhWaitBusSleepTimer" INT 0 65535;
BA_DEF_  "NmhPrepareBusSleepTimer" INT 0 65535;
BA_DEF_  "NmhLongTimer" INT 0 65535;
BA_DEF_  "NmhNStart" INT 0 255;
BA_DEF_ BU_  "GenNodAutoGenDsp" ENUM "No", "Yes";
BA_DEF_ BU_  "GenNodAutoGenSnd" ENUM "No", "Yes";
BA_DEF_ BU_  "GenNodSleepTime" INT 0 1000000;
BA_DEF_ BU_  "ILUsed" ENUM "No", "Yes";
BA_DEF_ BU_  "ECUVariantDefault" ENUM "No", "Yes";
BA_DEF_ BU_  "ECUVariantGroup" STRING;
BA_DEF_ BU_  "NodeLayerModules" STRING;
BA_DEF_ BU_  "NmhNode" ENUM "No", "Yes";
BA_DEF_ BU_  "NmNode" ENUM "No", "Yes";
BA_DEF_ BU_  "SamplePointMin" FLOAT 50.0 99.9;
BA_DEF_ BU_  "SamplePointMax" FLOAT 50.0 99.9;
BA_DEF_ BU_  "SyncJumpWidthMin" FLOAT 0.0 50.0;
BA_DEF_ BU_  "SyncJumpWidthMax" FLOAT 0.0 50.0;
BA_DEF_ BU_  "SyncJumpWidthCANFDMin" FLOAT 0.0 50.0;
BA_DEF_ BU_  "SyncJumpWidthCANFDMax" FLOAT 0.0 50.0;
BA_DEF_ BU_  "SamplePointCANFDMin" FLOAT 50.0 99.9;
BA_DEF_ BU_  "SamplePointCANFDMax" FLOAT 50.0 99.9;
BA_DEF_ BU_  "SSPOffsetCANFDMin" FLOAT 50.0 99.9;
BA_DEF_ BU_  "SSPOffsetCANFDMax" FLOAT 50.0 99.9;
BA_DEF_ BU_  "TimeQuantaMin" INT 4 257;
BA_DEF_ BU_  "TimeQuantaMax" INT 4 257;
BA_DEF_ BU_  "TimeQuantaCANFDMin" INT 4 257;
BA_DEF_ BU_  "TimeQuantaCANFDMax" INT 4 257;
BA_DEF_REL_ BU_SG_REL_  "GenSigTimeoutTime" INT 0 65535;
BA_DEF_ BO_  "DiagRequest" ENUM "No", "Yes";
BA_DEF_ BO_  "DiagResponse" ENUM "No", "Yes";
BA_DEF_ BO_  "DiagState" ENUM "No", "Yes";
BA_DEF_ BO_  "GenMsgChkConstant" HEX 0 4095;
BA_DEF_ BO_  "GenMsgCycleTime" INT 0 65535;
BA_DEF_ BO_  "GenMsgCycleTimeFast" INT 0 65535;
BA_DEF_ BO_  "GenMsgDelayTime" INT 0 100000;
BA_DEF_ BO_  "GenMsgILSupport" ENUM "No", "Yes";
BA_DEF_ BO_  "GenMsgNrOfRepetition" INT 0 100;
BA_DEF_ BO_  "GenMsgPDUConstants" STRING;
BA_DEF_ BO_  "GenMsgSendType" ENUM "Cyclic", "not_used", "not_used", "not_used", "not_used", "not_used", "not_used", "IfActive", "NoMsgSendType";
BA_DEF_ BO_  "GenMsgStartDelayTime" INT 0 100000;
BA_DEF_ BO_  "NmMessage" ENUM "No", "Yes";
BA_DEF_ BO_  "NmhMessage" ENUM "No", "Yes";
BA_DEF_ BO_  "MsgType" ENUM "Application", "NM ", "NMH", "TP2.0", "ISO-TP ", "BAP", "EID", "KS", "XCP_PRE_CONFIGURED", "XCP_RUNTIME_CONFIGURED";
BA_DEF_ BO_  "VAGTP20_API" HEX 0 255;
BA_DEF_ BO_  "VAGTP20_DynConnection" ENUM "No", "Yes";
BA_DEF_ BO_  "VAGTP20_DynSetup" ENUM "No", "Yes";
BA_DEF_ BO_  "VAGTP20_StatConnection" ENUM "No", "Yes";
BA_DEF_ BO_  "CANFD_BRS" ENUM "0", "1";
BA_DEF_ BO_  "VFrameFormat" ENUM "StandardCAN", "ExtendedCAN", "reserved", "reserved", "reserved", "reserved", "reserved", "reserved", "reserved", "reserved", "reserved", "reserved", "reserved", "reserved", "StandardCAN_FD", "ExtendedCAN_FD";
BA_DEF_ SG_  "GenSigActiveRepetitions" INT -2147483648 2147483647;
BA_DEF_ SG_  "GenSigInactiveValue" INT -2147483648 2147483647;
BA_DEF_ SG_  "GenSigSendType" ENUM "Cyclic", "OnWrite", "OnWriteWithRepetition", "OnChange", "OnChangeWithRepetition", "IfActive", "IfActiveWithRepetition", "NoSigSendType", "OnChangeAndIfActive", "OnChangeAndIfActiveWithRepetition";
BA_DEF_ SG_  "GenSigStartValue" INT -2147483648 2147483647;
BA_DEF_ SG_  "NWM-WakeupAllowed" ENUM "No", "Yes";
BA_DEF_ SG_  "GenSigFuncType" ENUM "NoFunction", "MsgCounter", "CRC-8", "XOR", "XOR-2", "DatedBit", "SW-Kl15", "CHK", "Constant", "Protocol", "CRC-8-SAE_J1850", "CRC-32", "DataLength", "DataID", "MsgCounter16", "SOK-Signatur", "Cluster";
BA_DEF_ SG_  "GenSigSwitchedByIgnition" ENUM "No", "Yes";
BA_DEF_ SG_  "Fehlerwert" HEX 0 2147483647;
BA_DEF_ SG_  "GenSigMissingSourceValue" HEX 0 2147483647;
BA_DEF_DEF_  "DBName" "";
BA_DEF_DEF_  "GenNWMApBusSleep" "";
BA_DEF_DEF_  "GenNWMApCanNormal" "";
BA_DEF_DEF_  "GenNWMApCanOff" "";
BA_DEF_DEF_  "GenNWMApCanOn" "";
BA_DEF_DEF_  "GenNWMApCanSleep" "";
BA_DEF_DEF_  "GenNWMApCanWakeUp" "";
BA_DEF_DEF_  "GenNWMGotoMode_Awake" "";
BA_DEF_DEF_  "GenNWMGotoMode_BusSleep" "";
BA_DEF_DEF_  "GenNWMSleepTime" 0;
BA_DEF_DEF_  "GenNWMTalkNM" "";
BA_DEF_DEF_  "Manufacturer" "";
BA_DEF_DEF_  "NmhBaseAddress" 0;
BA_DEF_DEF_  "NmhMessageCount" 1;
BA_DEF_DEF_  "NmType" "None";
BA_DEF_DEF_  "VAGTP20_SetupMessageCount" 0;
BA_DEF_DEF_  "VAGTP20_SetupStartAddress" 0;
BA_DEF_DEF_  "VersionDay" 12;
BA_DEF_DEF_  "VersionMonth" 6;
BA_DEF_DEF_  "VersionWeek" 24;
BA_DEF_DEF_  "VersionYear" 23;
BA_DEF_DEF_  "VersionNumber" 0;
BA_DEF_DEF_  "BusType" "";
BA_DEF_DEF_  "Baudrate" 500000;
BA_DEF_DEF_  "BaudrateCANFD" 2000000;
BA_DEF_DEF_  "NmhTimeoutTimer" 0;
BA_DEF_DEF_  "NmhWaitBusSleepTimer" 0;
BA_DEF_DEF_  "NmhPrepareBusSleepTimer" 0;
BA_DEF_DEF_  "NmhLongTimer" 0;
BA_DEF_DEF_  "NmhNStart" 0;
BA_DEF_DEF_  "GenNodAutoGenDsp" "Yes";
BA_DEF_DEF_  "GenNodAutoGenSnd" "Yes";
BA_DEF_DEF_  "GenNodSleepTime" 0;
BA_DEF_DEF_  "ILUsed" "Yes";
BA_DEF_DEF_  "ECUVariantDefault" "Yes";
BA_DEF_DEF_  "ECUVariantGroup" "";
BA_DEF_DEF_  "NodeLayerModules" "";
BA_DEF_DEF_  "NmhNode" "Yes";
BA_DEF_DEF_  "NmNode" "No";
BA_DEF_DEF_  "SamplePointMin" 75;
BA_DEF_DEF_  "SamplePointMax" 75;
BA_DEF_DEF_  "SyncJumpWidthMin" 50;
BA_DEF_DEF_  "SyncJumpWidthMax" 50;
BA_DEF_DEF_  "SyncJumpWidthCANFDMin" 50;
BA_DEF_DEF_  "SyncJumpWidthCANFDMax" 50;
BA_DEF_DEF_  "SamplePointCANFDMin" 75;
BA_DEF_DEF_  "SamplePointCANFDMax" 75;
BA_DEF_DEF_  "SSPOffsetCANFDMin" 75;
BA_DEF_DEF_  "SSPOffsetCANFDMax" 75;
BA_DEF_DEF_  "TimeQuantaMin" 160;
BA_DEF_DEF_  "TimeQuantaMax" 160;
BA_DEF_DEF_  "TimeQuantaCANFDMin" 40;
BA_DEF_DEF_  "TimeQuantaCANFDMax" 40;
BA_DEF_DEF_REL_  "GenSigTimeoutTime" 0;
BA_DEF_DEF_  "DiagRequest" "No";
BA_DEF_DEF_  "DiagResponse" "No";
BA_DEF_DEF_  "DiagState" "No";
BA_DEF_DEF_  "GenMsgChkConstant" 0;
BA_DEF_DEF_  "GenMsgCycleTime" 0;
BA_DEF_DEF_  "GenMsgCycleTimeFast" 0;
BA_DEF_DEF_  "GenMsgDelayTime" 0;
BA_DEF_DEF_  "GenMsgILSupport" "No";
BA_DEF_DEF_  "GenMsgNrOfRepetition" 0;
BA_DEF_DEF_  "GenMsgPDUConstants" "";
BA_DEF_DEF_  "GenMsgSendType" "NoMsgSendType";
BA_DEF_DEF_  "GenMsgStartDelayTime" 0;
BA_DEF_DEF_  "NmMessage" "No";
BA_DEF_DEF_  "NmhMessage" "No";
BA_DEF_DEF_  "MsgType" "Application";
BA_DEF_DEF_  "VAGTP20_API" 0;
BA_DEF_DEF_  "VAGTP20_DynConnection" "No";
BA_DEF_DEF_  "VAGTP20_DynSetup" "No";
BA_DEF_DEF_  "VAGTP20_StatConnection" "No";
BA_DEF_DEF_  "CANFD_BRS" "1";
BA_DEF_DEF_  "VFrameFormat" "StandardCAN";
BA_DEF_DEF_  "GenSigActiveRepetitions" 0;
BA_DEF_DEF_  "GenSigInactiveValue" 0;
BA_DEF_DEF_  "GenSigSendType" "NoSigSendType";
BA_DEF_DEF_  "GenSigStartValue" 0;
BA_DEF_DEF_  "NWM-WakeupAllowed" "No";
BA_DEF_DEF_  "GenSigFuncType" "NoFunction";
BA_DEF_DEF_  "GenSigSwitchedByIgnition" "Yes";
BA_DEF_DEF_  "Fehlerwert" 0;
BA_DEF_DEF_  "GenSigMissingSourceValue" 0;
BA_  "DBName" "K2CANFD";
BA_  "GenNWMApBusSleep" "NMIndNetSDN()";
BA_  "GenNWMApCanNormal" "apCanNormal()";
BA_  "GenNWMApCanOff" "NMIndnetOff()";
BA_  "GenNWMApCanOn" "NMIndnetOn()";
BA_  "GenNWMApCanSleep" "apCanSleep()";
BA_  "GenNWMApCanWakeUp" "apCanWakeUp()";
BA_  "GenNWMGotoMode_Awake" "Nmh_ReqNetOn()";
BA_  "GenNWMGotoMode_BusSleep" "Nmh_ReqNetOff()";
BA_  "GenNWMSleepTime" 4000;
BA_  "GenNWMTalkNM" "Nmh_ReqNetOn()";
BA_  "Manufacturer" "VAG";
BA_  "NmhBaseAddress" 452984832;
BA_  "NmhMessageCount" 1024;
BA_  "NmType" "NM-High";
BA_  "VAGTP20_SetupMessageCount" 128;
BA_  "VAGTP20_SetupStartAddress" 512;
BA_  "VersionNumber" 9;
BA_  "BusType" "CAN FD";
BA_  "BaudrateCANFD" 500000;
BA_  "NmhTimeoutTimer" 1000;
BA_  "NmhWaitBusSleepTimer" 750;
BA_  "NmhPrepareBusSleepTimer" 500;
BA_  "NmhLongTimer" 200;
BA_  "NmhNStart" 20;
BA_ "GenNodSleepTime" BU_ BAP_Tester 4000;
BA_ "ECUVariantGroup" BU_ BAP_Tester "BAP";
BA_ "NmhNode" BU_ BAP_Tester 0;
BA_ "SamplePointMin" BU_ BAP_Tester 80;
BA_ "SamplePointMax" BU_ BAP_Tester 80;
BA_ "SyncJumpWidthMin" BU_ BAP_Tester 4;
BA_ "SyncJumpWidthMax" BU_ BAP_Tester 4;
BA_ "SyncJumpWidthCANFDMin" BU_ BAP_Tester 4;
BA_ "SyncJumpWidthCANFDMax" BU_ BAP_Tester 4;
BA_ "SamplePointCANFDMin" BU_ BAP_Tester 80;
BA_ "SamplePointCANFDMax" BU_ BAP_Tester 80;
BA_ "SSPOffsetCANFDMin" BU_ BAP_Tester 80;
BA_ "SSPOffsetCANFDMax" BU_ BAP_Tester 80;
BA_ "TimeQuantaMin" BU_ BAP_Tester 20;
BA_ "TimeQuantaMax" BU_ BAP_Tester 20;
BA_ "TimeQuantaCANFDMin" BU_ BAP_Tester 20;
BA_ "TimeQuantaCANFDMax" BU_ BAP_Tester 20;
BA_ "GenNodSleepTime" BU_ BCM 4000;
BA_ "NodeLayerModules" BU_ BCM "NMHigh.DLL";
BA_ "SamplePointMin" BU_ BCM 80;
BA_ "SamplePointMax" BU_ BCM 80;
BA_ "SyncJumpWidthMin" BU_ BCM 4;
BA_ "SyncJumpWidthMax" BU_ BCM 4;
BA_ "SyncJumpWidthCANFDMin" BU_ BCM 4;
BA_ "SyncJumpWidthCANFDMax" BU_ BCM 4;
BA_ "SamplePointCANFDMin" BU_ BCM 80;
BA_ "SamplePointCANFDMax" BU_ BCM 80;
BA_ "SSPOffsetCANFDMin" BU_ BCM 80;
BA_ "SSPOffsetCANFDMax" BU_ BCM 80;
BA_ "TimeQuantaMin" BU_ BCM 20;
BA_ "TimeQuantaMax" BU_ BCM 20;
BA_ "TimeQuantaCANFDMin" BU_ BCM 20;
BA_ "TimeQuantaCANFDMax" BU_ BCM 20;
BA_ "GenNodSleepTime" BU_ Gateway_Max 4000;
BA_ "ECUVariantGroup" BU_ Gateway_Max "Gateway";
BA_ "NodeLayerModules" BU_ Gateway_Max "NMHigh.DLL";
BA_ "SamplePointMin" BU_ Gateway_Max 80;
BA_ "SamplePointMax" BU_ Gateway_Max 80;
BA_ "SyncJumpWidthMin" BU_ Gateway_Max 4;
BA_ "SyncJumpWidthMax" BU_ Gateway_Max 4;
BA_ "SyncJumpWidthCANFDMin" BU_ Gateway_Max 4;
BA_ "SyncJumpWidthCANFDMax" BU_ Gateway_Max 4;
BA_ "SamplePointCANFDMin" BU_ Gateway_Max 80;
BA_ "SamplePointCANFDMax" BU_ Gateway_Max 80;
BA_ "SSPOffsetCANFDMin" BU_ Gateway_Max 80;
BA_ "SSPOffsetCANFDMax" BU_ Gateway_Max 80;
BA_ "TimeQuantaMin" BU_ Gateway_Max 20;
BA_ "TimeQuantaMax" BU_ Gateway_Max 20;
BA_ "TimeQuantaCANFDMin" BU_ Gateway_Max 20;
BA_ "TimeQuantaCANFDMax" BU_ Gateway_Max 20;
BA_ "GenNodSleepTime" BU_ TSGGen3_BFS 4000;
BA_ "NodeLayerModules" BU_ TSGGen3_BFS "NMHigh.DLL";
BA_ "SamplePointMin" BU_ TSGGen3_BFS 80;
BA_ "SamplePointMax" BU_ TSGGen3_BFS 80;
BA_ "SyncJumpWidthMin" BU_ TSGGen3_BFS 4;
BA_ "SyncJumpWidthMax" BU_ TSGGen3_BFS 4;
BA_ "SyncJumpWidthCANFDMin" BU_ TSGGen3_BFS 4;
BA_ "SyncJumpWidthCANFDMax" BU_ TSGGen3_BFS 4;
BA_ "SamplePointCANFDMin" BU_ TSGGen3_BFS 80;
BA_ "SamplePointCANFDMax" BU_ TSGGen3_BFS 80;
BA_ "SSPOffsetCANFDMin" BU_ TSGGen3_BFS 80;
BA_ "SSPOffsetCANFDMax" BU_ TSGGen3_BFS 80;
BA_ "TimeQuantaMin" BU_ TSGGen3_BFS 20;
BA_ "TimeQuantaMax" BU_ TSGGen3_BFS 20;
BA_ "TimeQuantaCANFDMin" BU_ TSGGen3_BFS 20;
BA_ "TimeQuantaCANFDMax" BU_ TSGGen3_BFS 20;
BA_ "GenNodSleepTime" BU_ TSGGen3_FS 4000;
BA_ "NodeLayerModules" BU_ TSGGen3_FS "NMHigh.DLL";
BA_ "SamplePointMin" BU_ TSGGen3_FS 80;
BA_ "SamplePointMax" BU_ TSGGen3_FS 80;
BA_ "SyncJumpWidthMin" BU_ TSGGen3_FS 4;
BA_ "SyncJumpWidthMax" BU_ TSGGen3_FS 4;
BA_ "SyncJumpWidthCANFDMin" BU_ TSGGen3_FS 4;
BA_ "SyncJumpWidthCANFDMax" BU_ TSGGen3_FS 4;
BA_ "SamplePointCANFDMin" BU_ TSGGen3_FS 80;
BA_ "SamplePointCANFDMax" BU_ TSGGen3_FS 80;
BA_ "SSPOffsetCANFDMin" BU_ TSGGen3_FS 80;
BA_ "SSPOffsetCANFDMax" BU_ TSGGen3_FS 80;
BA_ "TimeQuantaMin" BU_ TSGGen3_FS 20;
BA_ "TimeQuantaMax" BU_ TSGGen3_FS 20;
BA_ "TimeQuantaCANFDMin" BU_ TSGGen3_FS 20;
BA_ "TimeQuantaCANFDMax" BU_ TSGGen3_FS 20;
BA_ "GenNodSleepTime" BU_ TSGGen3_HBFS 4000;
BA_ "NodeLayerModules" BU_ TSGGen3_HBFS "NMHigh.DLL";
BA_ "SamplePointMin" BU_ TSGGen3_HBFS 80;
BA_ "SamplePointMax" BU_ TSGGen3_HBFS 80;
BA_ "SyncJumpWidthMin" BU_ TSGGen3_HBFS 4;
BA_ "SyncJumpWidthMax" BU_ TSGGen3_HBFS 4;
BA_ "SyncJumpWidthCANFDMin" BU_ TSGGen3_HBFS 4;
BA_ "SyncJumpWidthCANFDMax" BU_ TSGGen3_HBFS 4;
BA_ "SamplePointCANFDMin" BU_ TSGGen3_HBFS 80;
BA_ "SamplePointCANFDMax" BU_ TSGGen3_HBFS 80;
BA_ "SSPOffsetCANFDMin" BU_ TSGGen3_HBFS 80;
BA_ "SSPOffsetCANFDMax" BU_ TSGGen3_HBFS 80;
BA_ "TimeQuantaMin" BU_ TSGGen3_HBFS 20;
BA_ "TimeQuantaMax" BU_ TSGGen3_HBFS 20;
BA_ "TimeQuantaCANFDMin" BU_ TSGGen3_HBFS 20;
BA_ "TimeQuantaCANFDMax" BU_ TSGGen3_HBFS 20;
BA_ "GenNodSleepTime" BU_ TSGGen3_HFS 4000;
BA_ "NodeLayerModules" BU_ TSGGen3_HFS "NMHigh.DLL";
BA_ "SamplePointMin" BU_ TSGGen3_HFS 80;
BA_ "SamplePointMax" BU_ TSGGen3_HFS 80;
BA_ "SyncJumpWidthMin" BU_ TSGGen3_HFS 4;
BA_ "SyncJumpWidthMax" BU_ TSGGen3_HFS 4;
BA_ "SyncJumpWidthCANFDMin" BU_ TSGGen3_HFS 4;
BA_ "SyncJumpWidthCANFDMax" BU_ TSGGen3_HFS 4;
BA_ "SamplePointCANFDMin" BU_ TSGGen3_HFS 80;
BA_ "SamplePointCANFDMax" BU_ TSGGen3_HFS 80;
BA_ "SSPOffsetCANFDMin" BU_ TSGGen3_HFS 80;
BA_ "SSPOffsetCANFDMax" BU_ TSGGen3_HFS 80;
BA_ "TimeQuantaMin" BU_ TSGGen3_HFS 20;
BA_ "TimeQuantaMax" BU_ TSGGen3_HFS 20;
BA_ "TimeQuantaCANFDMin" BU_ TSGGen3_HFS 20;
BA_ "TimeQuantaCANFDMax" BU_ TSGGen3_HFS 20;
BA_ "GenNodSleepTime" BU_ WLC_01_CFD 4000;
BA_ "NodeLayerModules" BU_ WLC_01_CFD "NMHigh.DLL";
BA_ "SamplePointMin" BU_ WLC_01_CFD 80;
BA_ "SamplePointMax" BU_ WLC_01_CFD 80;
BA_ "SyncJumpWidthMin" BU_ WLC_01_CFD 4;
BA_ "SyncJumpWidthMax" BU_ WLC_01_CFD 4;
BA_ "SyncJumpWidthCANFDMin" BU_ WLC_01_CFD 4;
BA_ "SyncJumpWidthCANFDMax" BU_ WLC_01_CFD 4;
BA_ "SamplePointCANFDMin" BU_ WLC_01_CFD 80;
BA_ "SamplePointCANFDMax" BU_ WLC_01_CFD 80;
BA_ "SSPOffsetCANFDMin" BU_ WLC_01_CFD 80;
BA_ "SSPOffsetCANFDMax" BU_ WLC_01_CFD 80;
BA_ "TimeQuantaMin" BU_ WLC_01_CFD 20;
BA_ "TimeQuantaMax" BU_ WLC_01_CFD 20;
BA_ "TimeQuantaCANFDMin" BU_ WLC_01_CFD 20;
BA_ "TimeQuantaCANFDMax" BU_ WLC_01_CFD 20;
BA_ "GenMsgCycleTime" BO_ 2527679923 960;
BA_ "GenMsgCycleTimeFast" BO_ 2527679923 40;
BA_ "GenMsgDelayTime" BO_ 2527679923 40;
BA_ "GenMsgILSupport" BO_ 2527679923 1;
BA_ "GenMsgNrOfRepetition" BO_ 2527679923 10;
BA_ "GenMsgSendType" BO_ 2527679923 0;
BA_ "CANFD_BRS" BO_ 2527679923 0;
BA_ "VFrameFormat" BO_ 2527679923 15;
BA_ "GenMsgChkConstant" BO_ 64 64;
BA_ "GenMsgCycleTime" BO_ 64 40;
BA_ "GenMsgCycleTimeFast" BO_ 64 10;
BA_ "GenMsgDelayTime" BO_ 64 10;
BA_ "GenMsgILSupport" BO_ 64 1;
BA_ "GenMsgNrOfRepetition" BO_ 64 5;
BA_ "GenMsgPDUConstants" BO_ 64 "0x40,0x40,0x40,0x40,0x40,0x40,0x40,0x40,0x40,0x40,0x40,0x40,0x40,0x40,0x40,0x40";
BA_ "GenMsgSendType" BO_ 64 0;
BA_ "CANFD_BRS" BO_ 64 0;
BA_ "VFrameFormat" BO_ 64 14;
BA_ "GenMsgChkConstant" BO_ 1312 68;
BA_ "GenMsgCycleTime" BO_ 1312 200;
BA_ "GenMsgDelayTime" BO_ 1312 20;
BA_ "GenMsgILSupport" BO_ 1312 1;
BA_ "GenMsgPDUConstants" BO_ 1312 "0x44,0x44,0x44,0x44,0x44,0x44,0x44,0x44,0x44,0x44,0x44,0x44,0x44,0x44,0x44,0x44";
BA_ "GenMsgSendType" BO_ 1312 0;
BA_ "CANFD_BRS" BO_ 1312 0;
BA_ "VFrameFormat" BO_ 1312 14;
BA_ "GenMsgCycleTime" BO_ 1349 200;
BA_ "GenMsgDelayTime" BO_ 1349 40;
BA_ "GenMsgILSupport" BO_ 1349 1;
BA_ "GenMsgPDUConstants" BO_ 1349 "0x95,0x19,0xd1,0x36,0x89,0xd4,0x02,0x1e,0xb9,0x80,0xd0,0x22,0x8a,0xf4,0x15,0xb8";
BA_ "GenMsgSendType" BO_ 1349 0;
BA_ "CANFD_BRS" BO_ 1349 0;
BA_ "VFrameFormat" BO_ 1349 14;
BA_ "GenMsgCycleTime" BO_ 2527679722 200;
BA_ "GenMsgILSupport" BO_ 2527679722 1;
BA_ "GenMsgPDUConstants" BO_ 2527679722 "0x81,0x55,0xf0,0x94,0x56,0x5f,0xa4,0x5c,0x2f,0x61,0x48,0x01,0xf8,0xd7,0x33,0x87";
BA_ "GenMsgSendType" BO_ 2527679722 0;
BA_ "CANFD_BRS" BO_ 2527679722 0;
BA_ "VFrameFormat" BO_ 2527679722 15;
BA_ "GenMsgCycleTime" BO_ 1633 100;
BA_ "GenMsgILSupport" BO_ 1633 1;
BA_ "GenMsgSendType" BO_ 1633 0;
BA_ "CANFD_BRS" BO_ 1633 0;
BA_ "VFrameFormat" BO_ 1633 14;
BA_ "GenMsgChkConstant" BO_ 896 19;
BA_ "GenMsgCycleTime" BO_ 896 80;
BA_ "GenMsgCycleTimeFast" BO_ 896 20;
BA_ "GenMsgILSupport" BO_ 896 1;
BA_ "GenMsgPDUConstants" BO_ 896 "0x13,0x13,0x13,0x13,0x13,0x13,0x13,0x13,0x13,0x13,0x13,0x13,0x13,0x13,0x13,0x13";
BA_ "GenMsgSendType" BO_ 896 0;
BA_ "CANFD_BRS" BO_ 896 0;
BA_ "VFrameFormat" BO_ 896 14;
BA_ "GenMsgCycleTime" BO_ 345 100;
BA_ "GenMsgDelayTime" BO_ 345 10;
BA_ "GenMsgILSupport" BO_ 345 1;
BA_ "GenMsgSendType" BO_ 345 0;
BA_ "CANFD_BRS" BO_ 345 0;
BA_ "VFrameFormat" BO_ 345 14;
BA_ "GenMsgCycleTime" BO_ 2527679661 200;
BA_ "GenMsgDelayTime" BO_ 2527679661 40;
BA_ "GenMsgILSupport" BO_ 2527679661 1;
BA_ "GenMsgSendType" BO_ 2527679661 0;
BA_ "CANFD_BRS" BO_ 2527679661 0;
BA_ "VFrameFormat" BO_ 2527679661 15;
BA_ "GenMsgCycleTime" BO_ 2463978752 1000;
BA_ "GenMsgCycleTimeFast" BO_ 2463978752 100;
BA_ "GenMsgDelayTime" BO_ 2463978752 50;
BA_ "GenMsgILSupport" BO_ 2463978752 1;
BA_ "GenMsgNrOfRepetition" BO_ 2463978752 5;
BA_ "GenMsgSendType" BO_ 2463978752 0;
BA_ "CANFD_BRS" BO_ 2463978752 0;
BA_ "VFrameFormat" BO_ 2463978752 15;
BA_ "GenMsgCycleTimeFast" BO_ 2536704256 80;
BA_ "GenMsgSendType" BO_ 2536704256 7;
BA_ "MsgType" BO_ 2536704256 5;
BA_ "CANFD_BRS" BO_ 2536704256 0;
BA_ "VFrameFormat" BO_ 2536704256 15;
BA_ "GenMsgCycleTimeFast" BO_ 2536704257 80;
BA_ "GenMsgSendType" BO_ 2536704257 7;
BA_ "MsgType" BO_ 2536704257 5;
BA_ "CANFD_BRS" BO_ 2536704257 0;
BA_ "VFrameFormat" BO_ 2536704257 15;
BA_ "GenMsgCycleTime" BO_ 2536704272 1000;
BA_ "GenMsgCycleTimeFast" BO_ 2536704272 50;
BA_ "GenMsgSendType" BO_ 2536704272 7;
BA_ "MsgType" BO_ 2536704272 5;
BA_ "CANFD_BRS" BO_ 2536704272 0;
BA_ "VFrameFormat" BO_ 2536704272 15;
BA_ "GenMsgCycleTimeFast" BO_ 2536726786 20;
BA_ "GenMsgSendType" BO_ 2536726786 7;
BA_ "MsgType" BO_ 2536726786 5;
BA_ "CANFD_BRS" BO_ 2536726786 0;
BA_ "VFrameFormat" BO_ 2536726786 15;
BA_ "GenMsgCycleTime" BO_ 2536726802 1000;
BA_ "GenMsgCycleTimeFast" BO_ 2536726802 30;
BA_ "GenMsgSendType" BO_ 2536726802 7;
BA_ "MsgType" BO_ 2536726802 5;
BA_ "CANFD_BRS" BO_ 2536726802 0;
BA_ "VFrameFormat" BO_ 2536726802 15;
BA_ "MsgType" BO_ 2536767264 5;
BA_ "CANFD_BRS" BO_ 2536767264 0;
BA_ "VFrameFormat" BO_ 2536767264 15;
BA_ "MsgType" BO_ 2536767280 5;
BA_ "CANFD_BRS" BO_ 2536767280 0;
BA_ "VFrameFormat" BO_ 2536767280 15;
BA_ "GenMsgCycleTimeFast" BO_ 2536705280 80;
BA_ "GenMsgSendType" BO_ 2536705280 7;
BA_ "MsgType" BO_ 2536705280 5;
BA_ "CANFD_BRS" BO_ 2536705280 0;
BA_ "VFrameFormat" BO_ 2536705280 15;
BA_ "GenMsgCycleTimeFast" BO_ 2536705281 80;
BA_ "GenMsgSendType" BO_ 2536705281 7;
BA_ "MsgType" BO_ 2536705281 5;
BA_ "CANFD_BRS" BO_ 2536705281 0;
BA_ "VFrameFormat" BO_ 2536705281 15;
BA_ "GenMsgCycleTimeFast" BO_ 2536705282 80;
BA_ "GenMsgSendType" BO_ 2536705282 7;
BA_ "MsgType" BO_ 2536705282 5;
BA_ "CANFD_BRS" BO_ 2536705282 0;
BA_ "VFrameFormat" BO_ 2536705282 15;
BA_ "GenMsgCycleTime" BO_ 2536705296 1000;
BA_ "GenMsgCycleTimeFast" BO_ 2536705296 20;
BA_ "GenMsgSendType" BO_ 2536705296 7;
BA_ "MsgType" BO_ 2536705296 5;
BA_ "CANFD_BRS" BO_ 2536705296 0;
BA_ "VFrameFormat" BO_ 2536705296 15;
BA_ "GenMsgCycleTimeFast" BO_ 2536727296 50;
BA_ "GenMsgSendType" BO_ 2536727296 7;
BA_ "MsgType" BO_ 2536727296 5;
BA_ "CANFD_BRS" BO_ 2536727296 0;
BA_ "VFrameFormat" BO_ 2536727296 15;
BA_ "GenMsgCycleTime" BO_ 2536727312 1000;
BA_ "GenMsgCycleTimeFast" BO_ 2536727312 50;
BA_ "GenMsgSendType" BO_ 2536727312 7;
BA_ "MsgType" BO_ 2536727312 5;
BA_ "CANFD_BRS" BO_ 2536727312 0;
BA_ "VFrameFormat" BO_ 2536727312 15;
BA_ "GenMsgCycleTimeFast" BO_ 2536724736 80;
BA_ "GenMsgSendType" BO_ 2536724736 7;
BA_ "MsgType" BO_ 2536724736 5;
BA_ "CANFD_BRS" BO_ 2536724736 0;
BA_ "VFrameFormat" BO_ 2536724736 15;
BA_ "GenMsgCycleTime" BO_ 2536724752 1000;
BA_ "GenMsgCycleTimeFast" BO_ 2536724752 50;
BA_ "GenMsgSendType" BO_ 2536724752 7;
BA_ "MsgType" BO_ 2536724752 5;
BA_ "CANFD_BRS" BO_ 2536724752 0;
BA_ "VFrameFormat" BO_ 2536724752 15;
BA_ "GenMsgCycleTimeFast" BO_ 2536724480 50;
BA_ "GenMsgSendType" BO_ 2536724480 7;
BA_ "MsgType" BO_ 2536724480 5;
BA_ "CANFD_BRS" BO_ 2536724480 0;
BA_ "VFrameFormat" BO_ 2536724480 15;
BA_ "GenMsgCycleTimeFast" BO_ 2536724481 30;
BA_ "GenMsgSendType" BO_ 2536724481 7;
BA_ "MsgType" BO_ 2536724481 5;
BA_ "CANFD_BRS" BO_ 2536724481 0;
BA_ "VFrameFormat" BO_ 2536724481 15;
BA_ "GenMsgCycleTime" BO_ 2536724496 1000;
BA_ "GenMsgCycleTimeFast" BO_ 2536724496 30;
BA_ "GenMsgSendType" BO_ 2536724496 7;
BA_ "MsgType" BO_ 2536724496 5;
BA_ "CANFD_BRS" BO_ 2536724496 0;
BA_ "VFrameFormat" BO_ 2536724496 15;
BA_ "GenMsgCycleTime" BO_ 2536724497 1000;
BA_ "GenMsgCycleTimeFast" BO_ 2536724497 10;
BA_ "GenMsgSendType" BO_ 2536724497 7;
BA_ "MsgType" BO_ 2536724497 5;
BA_ "CANFD_BRS" BO_ 2536724497 0;
BA_ "VFrameFormat" BO_ 2536724497 15;
BA_ "GenMsgCycleTimeFast" BO_ 2536707072 120;
BA_ "GenMsgSendType" BO_ 2536707072 7;
BA_ "MsgType" BO_ 2536707072 5;
BA_ "CANFD_BRS" BO_ 2536707072 0;
BA_ "VFrameFormat" BO_ 2536707072 15;
BA_ "GenMsgCycleTime" BO_ 2536707088 1000;
BA_ "GenMsgCycleTimeFast" BO_ 2536707088 80;
BA_ "GenMsgSendType" BO_ 2536707088 7;
BA_ "MsgType" BO_ 2536707088 5;
BA_ "CANFD_BRS" BO_ 2536707088 0;
BA_ "VFrameFormat" BO_ 2536707088 15;
BA_ "GenMsgCycleTimeFast" BO_ 2536722946 80;
BA_ "GenMsgSendType" BO_ 2536722946 7;
BA_ "MsgType" BO_ 2536722946 5;
BA_ "CANFD_BRS" BO_ 2536722946 0;
BA_ "VFrameFormat" BO_ 2536722946 15;
BA_ "GenMsgCycleTime" BO_ 2536722960 1000;
BA_ "GenMsgCycleTimeFast" BO_ 2536722960 50;
BA_ "GenMsgSendType" BO_ 2536722960 7;
BA_ "MsgType" BO_ 2536722960 5;
BA_ "CANFD_BRS" BO_ 2536722960 0;
BA_ "VFrameFormat" BO_ 2536722960 15;
BA_ "DiagState" BO_ 2536704000 1;
BA_ "GenMsgCycleTimeFast" BO_ 2536704000 80;
BA_ "GenMsgSendType" BO_ 2536704000 7;
BA_ "MsgType" BO_ 2536704000 5;
BA_ "CANFD_BRS" BO_ 2536704000 0;
BA_ "VFrameFormat" BO_ 2536704000 15;
BA_ "GenMsgCycleTimeFast" BO_ 2536704001 50;
BA_ "GenMsgSendType" BO_ 2536704001 7;
BA_ "MsgType" BO_ 2536704001 5;
BA_ "CANFD_BRS" BO_ 2536704001 0;
BA_ "VFrameFormat" BO_ 2536704001 15;
BA_ "GenMsgCycleTimeFast" BO_ 2536704003 80;
BA_ "GenMsgSendType" BO_ 2536704003 7;
BA_ "MsgType" BO_ 2536704003 5;
BA_ "CANFD_BRS" BO_ 2536704003 0;
BA_ "VFrameFormat" BO_ 2536704003 15;
BA_ "GenMsgCycleTime" BO_ 2536704016 1000;
BA_ "GenMsgCycleTimeFast" BO_ 2536704016 50;
BA_ "GenMsgSendType" BO_ 2536704016 7;
BA_ "MsgType" BO_ 2536704016 5;
BA_ "CANFD_BRS" BO_ 2536704016 0;
BA_ "VFrameFormat" BO_ 2536704016 15;
BA_ "GenMsgCycleTimeFast" BO_ 2536705536 80;
BA_ "GenMsgSendType" BO_ 2536705536 7;
BA_ "MsgType" BO_ 2536705536 5;
BA_ "CANFD_BRS" BO_ 2536705536 0;
BA_ "VFrameFormat" BO_ 2536705536 15;
BA_ "GenMsgCycleTimeFast" BO_ 2536705537 80;
BA_ "GenMsgSendType" BO_ 2536705537 7;
BA_ "MsgType" BO_ 2536705537 5;
BA_ "CANFD_BRS" BO_ 2536705537 0;
BA_ "VFrameFormat" BO_ 2536705537 15;
BA_ "GenMsgCycleTime" BO_ 2536705552 1000;
BA_ "GenMsgCycleTimeFast" BO_ 2536705552 50;
BA_ "GenMsgSendType" BO_ 2536705552 7;
BA_ "MsgType" BO_ 2536705552 5;
BA_ "CANFD_BRS" BO_ 2536705552 0;
BA_ "VFrameFormat" BO_ 2536705552 15;
BA_ "GenMsgCycleTimeFast" BO_ 2536732416 80;
BA_ "GenMsgSendType" BO_ 2536732416 7;
BA_ "MsgType" BO_ 2536732416 5;
BA_ "CANFD_BRS" BO_ 2536732416 0;
BA_ "VFrameFormat" BO_ 2536732416 15;
BA_ "GenMsgCycleTimeFast" BO_ 2536732417 80;
BA_ "GenMsgSendType" BO_ 2536732417 7;
BA_ "MsgType" BO_ 2536732417 5;
BA_ "CANFD_BRS" BO_ 2536732417 0;
BA_ "VFrameFormat" BO_ 2536732417 15;
BA_ "GenMsgCycleTime" BO_ 2536732432 1000;
BA_ "GenMsgCycleTimeFast" BO_ 2536732432 50;
BA_ "GenMsgSendType" BO_ 2536732432 7;
BA_ "MsgType" BO_ 2536732432 5;
BA_ "CANFD_BRS" BO_ 2536732432 0;
BA_ "VFrameFormat" BO_ 2536732432 15;
BA_ "GenMsgCycleTimeFast" BO_ 2536734464 80;
BA_ "GenMsgSendType" BO_ 2536734464 7;
BA_ "MsgType" BO_ 2536734464 5;
BA_ "CANFD_BRS" BO_ 2536734464 0;
BA_ "VFrameFormat" BO_ 2536734464 15;
BA_ "GenMsgCycleTime" BO_ 2536734480 1000;
BA_ "GenMsgCycleTimeFast" BO_ 2536734480 50;
BA_ "GenMsgSendType" BO_ 2536734480 7;
BA_ "MsgType" BO_ 2536734480 5;
BA_ "CANFD_BRS" BO_ 2536734480 0;
BA_ "VFrameFormat" BO_ 2536734480 15;
BA_ "GenMsgCycleTimeFast" BO_ 2536704517 80;
BA_ "GenMsgSendType" BO_ 2536704517 7;
BA_ "MsgType" BO_ 2536704517 5;
BA_ "CANFD_BRS" BO_ 2536704517 0;
BA_ "VFrameFormat" BO_ 2536704517 15;
BA_ "GenMsgCycleTime" BO_ 2536704528 1000;
BA_ "GenMsgCycleTimeFast" BO_ 2536704528 50;
BA_ "GenMsgSendType" BO_ 2536704528 7;
BA_ "MsgType" BO_ 2536704528 5;
BA_ "CANFD_BRS" BO_ 2536704528 0;
BA_ "VFrameFormat" BO_ 2536704528 15;
BA_ "GenMsgCycleTime" BO_ 2536704529 1000;
BA_ "GenMsgCycleTimeFast" BO_ 2536704529 50;
BA_ "GenMsgSendType" BO_ 2536704529 7;
BA_ "MsgType" BO_ 2536704529 5;
BA_ "CANFD_BRS" BO_ 2536704529 0;
BA_ "VFrameFormat" BO_ 2536704529 15;
BA_ "GenMsgCycleTimeFast" BO_ 2536721920 80;
BA_ "GenMsgSendType" BO_ 2536721920 7;
BA_ "MsgType" BO_ 2536721920 5;
BA_ "CANFD_BRS" BO_ 2536721920 0;
BA_ "VFrameFormat" BO_ 2536721920 15;
BA_ "GenMsgCycleTimeFast" BO_ 2536721921 80;
BA_ "GenMsgSendType" BO_ 2536721921 7;
BA_ "MsgType" BO_ 2536721921 5;
BA_ "CANFD_BRS" BO_ 2536721921 0;
BA_ "VFrameFormat" BO_ 2536721921 15;
BA_ "GenMsgCycleTime" BO_ 2536721936 1000;
BA_ "GenMsgCycleTimeFast" BO_ 2536721936 50;
BA_ "GenMsgSendType" BO_ 2536721936 7;
BA_ "MsgType" BO_ 2536721936 5;
BA_ "CANFD_BRS" BO_ 2536721936 0;
BA_ "VFrameFormat" BO_ 2536721936 15;
BA_ "GenMsgCycleTimeFast" BO_ 2536731904 80;
BA_ "GenMsgSendType" BO_ 2536731904 7;
BA_ "MsgType" BO_ 2536731904 5;
BA_ "CANFD_BRS" BO_ 2536731904 0;
BA_ "VFrameFormat" BO_ 2536731904 15;
BA_ "GenMsgCycleTime" BO_ 2536731920 1000;
BA_ "GenMsgCycleTimeFast" BO_ 2536731920 50;
BA_ "GenMsgSendType" BO_ 2536731920 7;
BA_ "MsgType" BO_ 2536731920 5;
BA_ "CANFD_BRS" BO_ 2536731920 0;
BA_ "VFrameFormat" BO_ 2536731920 15;
BA_ "GenMsgCycleTimeFast" BO_ 2536730624 80;
BA_ "GenMsgSendType" BO_ 2536730624 7;
BA_ "MsgType" BO_ 2536730624 5;
BA_ "CANFD_BRS" BO_ 2536730624 0;
BA_ "VFrameFormat" BO_ 2536730624 15;
BA_ "GenMsgCycleTime" BO_ 2536730640 1000;
BA_ "GenMsgCycleTimeFast" BO_ 2536730640 50;
BA_ "GenMsgSendType" BO_ 2536730640 7;
BA_ "MsgType" BO_ 2536730640 5;
BA_ "CANFD_BRS" BO_ 2536730640 0;
BA_ "VFrameFormat" BO_ 2536730640 15;
BA_ "GenMsgCycleTimeFast" BO_ 2536717056 80;
BA_ "GenMsgSendType" BO_ 2536717056 7;
BA_ "MsgType" BO_ 2536717056 5;
BA_ "CANFD_BRS" BO_ 2536717056 0;
BA_ "VFrameFormat" BO_ 2536717056 15;
BA_ "GenMsgCycleTimeFast" BO_ 2536717057 80;
BA_ "GenMsgSendType" BO_ 2536717057 7;
BA_ "MsgType" BO_ 2536717057 5;
BA_ "CANFD_BRS" BO_ 2536717057 0;
BA_ "VFrameFormat" BO_ 2536717057 15;
BA_ "GenMsgCycleTime" BO_ 2536717072 1000;
BA_ "GenMsgCycleTimeFast" BO_ 2536717072 50;
BA_ "GenMsgSendType" BO_ 2536717072 7;
BA_ "MsgType" BO_ 2536717072 5;
BA_ "CANFD_BRS" BO_ 2536717072 0;
BA_ "VFrameFormat" BO_ 2536717072 15;
BA_ "GenMsgCycleTimeFast" BO_ 2536705024 80;
BA_ "GenMsgSendType" BO_ 2536705024 7;
BA_ "MsgType" BO_ 2536705024 5;
BA_ "CANFD_BRS" BO_ 2536705024 0;
BA_ "VFrameFormat" BO_ 2536705024 15;
BA_ "GenMsgCycleTimeFast" BO_ 2536705025 80;
BA_ "GenMsgSendType" BO_ 2536705025 7;
BA_ "MsgType" BO_ 2536705025 5;
BA_ "CANFD_BRS" BO_ 2536705025 0;
BA_ "VFrameFormat" BO_ 2536705025 15;
BA_ "GenMsgCycleTime" BO_ 2536705040 1000;
BA_ "GenMsgCycleTimeFast" BO_ 2536705040 50;
BA_ "GenMsgSendType" BO_ 2536705040 7;
BA_ "MsgType" BO_ 2536705040 5;
BA_ "CANFD_BRS" BO_ 2536705040 0;
BA_ "VFrameFormat" BO_ 2536705040 15;
BA_ "MsgType" BO_ 2583694872 4;
BA_ "CANFD_BRS" BO_ 2583694872 0;
BA_ "VFrameFormat" BO_ 2583694872 15;
BA_ "MsgType" BO_ 2583825944 4;
BA_ "CANFD_BRS" BO_ 2583825944 0;
BA_ "VFrameFormat" BO_ 2583825944 15;
BA_ "GenMsgCycleTime" BO_ 2527679636 1000;
BA_ "GenMsgDelayTime" BO_ 2527679636 100;
BA_ "GenMsgILSupport" BO_ 2527679636 1;
BA_ "GenMsgSendType" BO_ 2527679636 0;
BA_ "CANFD_BRS" BO_ 2527679636 0;
BA_ "VFrameFormat" BO_ 2527679636 15;
BA_ "GenMsgCycleTime" BO_ 1626 1000;
BA_ "GenMsgCycleTimeFast" BO_ 1626 100;
BA_ "GenMsgDelayTime" BO_ 1626 30;
BA_ "GenMsgILSupport" BO_ 1626 1;
BA_ "GenMsgNrOfRepetition" BO_ 1626 5;
BA_ "GenMsgSendType" BO_ 1626 0;
BA_ "CANFD_BRS" BO_ 1626 0;
BA_ "VFrameFormat" BO_ 1626 14;
BA_ "GenMsgCycleTime" BO_ 2527679637 1000;
BA_ "GenMsgCycleTimeFast" BO_ 2527679637 100;
BA_ "GenMsgDelayTime" BO_ 2527679637 50;
BA_ "GenMsgILSupport" BO_ 2527679637 1;
BA_ "GenMsgNrOfRepetition" BO_ 2527679637 5;
BA_ "GenMsgSendType" BO_ 2527679637 0;
BA_ "CANFD_BRS" BO_ 2527679637 0;
BA_ "VFrameFormat" BO_ 2527679637 15;
BA_ "GenMsgCycleTime" BO_ 2463978607 200;
BA_ "GenMsgDelayTime" BO_ 2463978607 20;
BA_ "GenMsgILSupport" BO_ 2463978607 1;
BA_ "GenMsgSendType" BO_ 2463978607 0;
BA_ "CANFD_BRS" BO_ 2463978607 0;
BA_ "VFrameFormat" BO_ 2463978607 15;
BA_ "GenMsgCycleTime" BO_ 2463978609 200;
BA_ "GenMsgDelayTime" BO_ 2463978609 20;
BA_ "GenMsgILSupport" BO_ 2463978609 1;
BA_ "GenMsgSendType" BO_ 2463978609 0;
BA_ "CANFD_BRS" BO_ 2463978609 0;
BA_ "VFrameFormat" BO_ 2463978609 15;
BA_ "GenMsgCycleTime" BO_ 526 200;
BA_ "GenMsgDelayTime" BO_ 526 20;
BA_ "GenMsgILSupport" BO_ 526 1;
BA_ "GenMsgSendType" BO_ 526 0;
BA_ "CANFD_BRS" BO_ 526 0;
BA_ "VFrameFormat" BO_ 526 14;
BA_ "GenSigSendType" SG_ 2527679923 ADA_AttentionLevel 3;
BA_ "GenSigStartValue" SG_ 2527679923 ADA_AttentionLevel 126;
BA_ "Fehlerwert" SG_ 2527679923 ADA_AttentionLevel 127;
BA_ "GenSigSendType" SG_ 2527679923 ADA_DistractionLevel 4;
BA_ "GenSigStartValue" SG_ 2527679923 ADA_DistractionLevel 126;
BA_ "Fehlerwert" SG_ 2527679923 ADA_DistractionLevel 127;
BA_ "GenSigSendType" SG_ 2527679923 ADA_DriverIsOperating 3;
BA_ "Fehlerwert" SG_ 2527679923 ADA_DriverIsOperating 3;
BA_ "GenSigSendType" SG_ 2527679923 ADA_DrowsinessLevel 4;
BA_ "GenSigStartValue" SG_ 2527679923 ADA_DrowsinessLevel 126;
BA_ "Fehlerwert" SG_ 2527679923 ADA_DrowsinessLevel 127;
BA_ "GenSigSendType" SG_ 2527679923 ADA_DrowsinessSystemState 4;
BA_ "GenSigSwitchedByIgnition" SG_ 2527679923 ADA_DrowsinessSystemState 0;
BA_ "GenSigSendType" SG_ 2527679923 ADA_HMI_Ablenkung_Deaktivierung 3;
BA_ "GenSigSendType" SG_ 2527679923 ADA_HMI_Ablenkung_Fehler_Popup 3;
BA_ "GenSigSendType" SG_ 2527679923 ADA_HMI_Ablenkung_Meldeakustik 3;
BA_ "GenSigSendType" SG_ 2527679923 ADA_HMI_Ablenkung_Meldung 3;
BA_ "GenSigSendType" SG_ 2527679923 ADA_HMI_Fahrzeit_seit_Pause 3;
BA_ "GenSigStartValue" SG_ 2527679923 ADA_HMI_Fahrzeit_seit_Pause 1023;
BA_ "GenSigSendType" SG_ 2527679923 ADA_HMI_Muedigkeit_Deaktivierung 3;
BA_ "GenSigSendType" SG_ 2527679923 ADA_HMI_Muedigkeit_Event_Meldung 3;
BA_ "GenSigSendType" SG_ 2527679923 ADA_HMI_Muedigkeit_Fehler_Popup 3;
BA_ "GenSigSendType" SG_ 2527679923 ADA_HMI_Muedigkeit_Meldeakustik 3;
BA_ "GenSigSendType" SG_ 2527679923 ADA_HMI_Muedigkeit_Meldung 3;
BA_ "GenSigSendType" SG_ 2527679923 ADA_Microsleep 3;
BA_ "GenSigStartValue" SG_ 2527679923 ADA_Microsleep 6;
BA_ "GenSigSendType" SG_ 2527679923 ADA_TriggerEmergencyAssist 3;
BA_ "GenSigStartValue" SG_ 2527679923 ADA_TriggerEmergencyAssist 6;
BA_ "Fehlerwert" SG_ 2527679923 ADA_TriggerEmergencyAssist 7;
BA_ "GenSigSendType" SG_ 2527679923 ADA_Upcoming_Microsleep 0;
BA_ "GenSigSendType" SG_ 2527679923 SOK_ADA_01_Signatur 0;
BA_ "GenSigFuncType" SG_ 2527679923 SOK_ADA_01_Signatur 15;
BA_ "GenSigSendType" SG_ 64 AB_Anzeige_Fussg 0;
BA_ "GenSigSwitchedByIgnition" SG_ 64 AB_Anzeige_Fussg 0;
BA_ "GenSigSendType" SG_ 64 AB_Belegung_VF 0;
BA_ "GenSigSwitchedByIgnition" SG_ 64 AB_Belegung_VF 0;
BA_ "Fehlerwert" SG_ 64 AB_Belegung_VF 1;
BA_ "GenSigSendType" SG_ 64 AB_Crash_Int 4;
BA_ "GenSigSwitchedByIgnition" SG_ 64 AB_Crash_Int 0;
BA_ "GenSigSendType" SG_ 64 AB_Deaktiviert 0;
BA_ "GenSigSwitchedByIgnition" SG_ 64 AB_Deaktiviert 0;
BA_ "GenSigSendType" SG_ 64 AB_Deaktivierung_HV 4;
BA_ "GenSigSwitchedByIgnition" SG_ 64 AB_Deaktivierung_HV 0;
BA_ "Fehlerwert" SG_ 64 AB_Deaktivierung_HV 7;
BA_ "GenSigSendType" SG_ 64 AB_Diagnose 0;
BA_ "GenSigSwitchedByIgnition" SG_ 64 AB_Diagnose 0;
BA_ "GenSigSendType" SG_ 64 AB_eCS_Error 0;
BA_ "GenSigSwitchedByIgnition" SG_ 64 AB_eCS_Error 0;
BA_ "GenSigSendType" SG_ 64 AB_EDR_Trigger 3;
BA_ "GenSigSwitchedByIgnition" SG_ 64 AB_EDR_Trigger 0;
BA_ "GenSigSendType" SG_ 64 AB_Erh_Auf_VB 0;
BA_ "GenSigSwitchedByIgnition" SG_ 64 AB_Erh_Auf_VB 0;
BA_ "GenSigSendType" SG_ 64 AB_Front_Crash 4;
BA_ "GenSigSwitchedByIgnition" SG_ 64 AB_Front_Crash 0;
BA_ "GenSigSendType" SG_ 64 AB_Gurtschloss_FA_ext 3;
BA_ "GenSigStartValue" SG_ 64 AB_Gurtschloss_FA_ext 6;
BA_ "GenSigSwitchedByIgnition" SG_ 64 AB_Gurtschloss_FA_ext 0;
BA_ "Fehlerwert" SG_ 64 AB_Gurtschloss_FA_ext 7;
BA_ "GenSigSendType" SG_ 64 AB_Gurtschloss_FA_ext_aktiv 0;
BA_ "GenSigSwitchedByIgnition" SG_ 64 AB_Gurtschloss_FA_ext_aktiv 0;
BA_ "GenSigSendType" SG_ 64 AB_Gurtwarn_VB 0;
BA_ "GenSigSwitchedByIgnition" SG_ 64 AB_Gurtwarn_VB 0;
BA_ "GenSigSendType" SG_ 64 AB_Gurtwarn_VF 0;
BA_ "GenSigSwitchedByIgnition" SG_ 64 AB_Gurtwarn_VF 0;
BA_ "GenSigSendType" SG_ 64 AB_Heck_Crash 4;
BA_ "GenSigSwitchedByIgnition" SG_ 64 AB_Heck_Crash 0;
BA_ "GenSigSendType" SG_ 64 AB_Lampe 0;
BA_ "GenSigStartValue" SG_ 64 AB_Lampe 1;
BA_ "GenSigSwitchedByIgnition" SG_ 64 AB_Lampe 0;
BA_ "GenSigSendType" SG_ 64 AB_MKB_Anforderung 4;
BA_ "GenSigSwitchedByIgnition" SG_ 64 AB_MKB_Anforderung 0;
BA_ "GenSigSendType" SG_ 64 AB_MKB_gueltig 0;
BA_ "GenSigSwitchedByIgnition" SG_ 64 AB_MKB_gueltig 0;
BA_ "GenSigSendType" SG_ 64 AB_PAO_Leuchte_Anf 0;
BA_ "GenSigStartValue" SG_ 64 AB_PAO_Leuchte_Anf 1;
BA_ "GenSigSwitchedByIgnition" SG_ 64 AB_PAO_Leuchte_Anf 0;
BA_ "GenSigSendType" SG_ 64 AB_RGS_Anst 3;
BA_ "GenSigStartValue" SG_ 64 AB_RGS_Anst 8;
BA_ "GenSigSwitchedByIgnition" SG_ 64 AB_RGS_Anst 0;
BA_ "GenSigSendType" SG_ 64 AB_Rollover_Crash 4;
BA_ "GenSigSwitchedByIgnition" SG_ 64 AB_Rollover_Crash 0;
BA_ "GenSigSendType" SG_ 64 AB_SB_Crash 4;
BA_ "GenSigSwitchedByIgnition" SG_ 64 AB_SB_Crash 0;
BA_ "GenSigSendType" SG_ 64 AB_SF_Crash 4;
BA_ "GenSigSwitchedByIgnition" SG_ 64 AB_SF_Crash 0;
BA_ "GenSigSendType" SG_ 64 AB_Stellgliedtest 0;
BA_ "GenSigSwitchedByIgnition" SG_ 64 AB_Stellgliedtest 0;
BA_ "GenSigSendType" SG_ 64 AB_Systemfehler 0;
BA_ "GenSigSwitchedByIgnition" SG_ 64 AB_Systemfehler 0;
BA_ "GenSigSendType" SG_ 64 AB_Texte_AKS 0;
BA_ "GenSigSwitchedByIgnition" SG_ 64 AB_Texte_AKS 0;
BA_ "GenSigSendType" SG_ 64 AB_VB_deaktiviert 0;
BA_ "GenSigStartValue" SG_ 64 AB_VB_deaktiviert 1;
BA_ "GenSigSwitchedByIgnition" SG_ 64 AB_VB_deaktiviert 0;
BA_ "GenSigSendType" SG_ 64 AB_Versorgungsspannung 0;
BA_ "GenSigSwitchedByIgnition" SG_ 64 AB_Versorgungsspannung 0;
BA_ "GenSigSendType" SG_ 64 Airbag_01_BZ 0;
BA_ "GenSigFuncType" SG_ 64 Airbag_01_BZ 1;
BA_ "GenSigSwitchedByIgnition" SG_ 64 Airbag_01_BZ 0;
BA_ "GenSigSendType" SG_ 64 Airbag_01_CRC 0;
BA_ "GenSigFuncType" SG_ 64 Airbag_01_CRC 2;
BA_ "GenSigSwitchedByIgnition" SG_ 64 Airbag_01_CRC 0;
BA_ "GenSigSendType" SG_ 64 ASM_Masterzeit_02 0;
BA_ "GenSigStartValue" SG_ 64 ASM_Masterzeit_02 255;
BA_ "GenSigSwitchedByIgnition" SG_ 64 ASM_Masterzeit_02 0;
BA_ "GenSigSendType" SG_ 1312 AB_Abschaltanf_SIH_BF 3;
BA_ "GenSigSendType" SG_ 1312 AB_Anforderung_eCall 0;
BA_ "GenSigSwitchedByIgnition" SG_ 1312 AB_Anforderung_eCall 0;
BA_ "GenSigSendType" SG_ 1312 AB_Anforderung_USM 0;
BA_ "GenSigSwitchedByIgnition" SG_ 1312 AB_Anforderung_USM 0;
BA_ "GenSigSendType" SG_ 1312 AB_Anprall_FGS 3;
BA_ "GenSigSendType" SG_ 1312 AB_Anprall_Front_Beifahrer 3;
BA_ "GenSigSendType" SG_ 1312 AB_Anprall_Front_Fahrer 3;
BA_ "GenSigSendType" SG_ 1312 AB_Anprall_Heck_Beifahrer 3;
BA_ "GenSigSendType" SG_ 1312 AB_Anprall_Heck_Fahrer 3;
BA_ "GenSigSendType" SG_ 1312 AB_Anprall_Rollover 3;
BA_ "GenSigSendType" SG_ 1312 AB_Anprall_Seite_Beifahrer 3;
BA_ "GenSigSendType" SG_ 1312 AB_Anprall_Seite_Fahrer 3;
BA_ "GenSigSendType" SG_ 1312 AB_Belegung_VB 0;
BA_ "GenSigSwitchedByIgnition" SG_ 1312 AB_Belegung_VB 0;
BA_ "Fehlerwert" SG_ 1312 AB_Belegung_VB 1;
BA_ "GenSigSendType" SG_ 1312 AB_Crashschwere 3;
BA_ "GenSigSwitchedByIgnition" SG_ 1312 AB_Crashschwere 0;
BA_ "Fehlerwert" SG_ 1312 AB_Crashschwere 7;
BA_ "GenSigSendType" SG_ 1312 AB_Gurtschloss_BF 3;
BA_ "GenSigStartValue" SG_ 1312 AB_Gurtschloss_BF 1;
BA_ "GenSigSwitchedByIgnition" SG_ 1312 AB_Gurtschloss_BF 0;
BA_ "GenSigSendType" SG_ 1312 AB_Gurtschloss_FA 3;
BA_ "GenSigStartValue" SG_ 1312 AB_Gurtschloss_FA 1;
BA_ "GenSigSwitchedByIgnition" SG_ 1312 AB_Gurtschloss_FA 0;
BA_ "GenSigSendType" SG_ 1312 AB_Gurtschloss_Reihe2_BF 3;
BA_ "GenSigStartValue" SG_ 1312 AB_Gurtschloss_Reihe2_BF 1;
BA_ "GenSigSwitchedByIgnition" SG_ 1312 AB_Gurtschloss_Reihe2_BF 0;
BA_ "GenSigSendType" SG_ 1312 AB_Gurtschloss_Reihe2_FA 3;
BA_ "GenSigStartValue" SG_ 1312 AB_Gurtschloss_Reihe2_FA 1;
BA_ "GenSigSwitchedByIgnition" SG_ 1312 AB_Gurtschloss_Reihe2_FA 0;
BA_ "GenSigSendType" SG_ 1312 AB_Gurtschloss_Reihe2_MI 3;
BA_ "GenSigStartValue" SG_ 1312 AB_Gurtschloss_Reihe2_MI 1;
BA_ "GenSigSwitchedByIgnition" SG_ 1312 AB_Gurtschloss_Reihe2_MI 0;
BA_ "GenSigSendType" SG_ 1312 AB_Gurtschloss_Reihe3_BF 3;
BA_ "GenSigStartValue" SG_ 1312 AB_Gurtschloss_Reihe3_BF 1;
BA_ "GenSigSwitchedByIgnition" SG_ 1312 AB_Gurtschloss_Reihe3_BF 0;
BA_ "GenSigSendType" SG_ 1312 AB_Gurtschloss_Reihe3_FA 3;
BA_ "GenSigStartValue" SG_ 1312 AB_Gurtschloss_Reihe3_FA 1;
BA_ "GenSigSwitchedByIgnition" SG_ 1312 AB_Gurtschloss_Reihe3_FA 0;
BA_ "GenSigSendType" SG_ 1312 AB_Gurtschloss_Reihe3_MI 3;
BA_ "GenSigStartValue" SG_ 1312 AB_Gurtschloss_Reihe3_MI 1;
BA_ "GenSigSwitchedByIgnition" SG_ 1312 AB_Gurtschloss_Reihe3_MI 0;
BA_ "GenSigSendType" SG_ 1312 AB_Sitzpos_Sens_BF 0;
BA_ "GenSigSwitchedByIgnition" SG_ 1312 AB_Sitzpos_Sens_BF 0;
BA_ "Fehlerwert" SG_ 1312 AB_Sitzpos_Sens_BF 1;
BA_ "GenSigSendType" SG_ 1312 AB_Sitzpos_Sens_FA 0;
BA_ "GenSigSwitchedByIgnition" SG_ 1312 AB_Sitzpos_Sens_FA 0;
BA_ "Fehlerwert" SG_ 1312 AB_Sitzpos_Sens_FA 1;
BA_ "GenSigSendType" SG_ 1312 AB_Wickelklappung_Reihe2_BF 3;
BA_ "GenSigStartValue" SG_ 1312 AB_Wickelklappung_Reihe2_BF 1;
BA_ "GenSigSwitchedByIgnition" SG_ 1312 AB_Wickelklappung_Reihe2_BF 0;
BA_ "GenSigSendType" SG_ 1312 AB_Wickelklappung_Reihe2_FA 3;
BA_ "GenSigStartValue" SG_ 1312 AB_Wickelklappung_Reihe2_FA 1;
BA_ "GenSigSwitchedByIgnition" SG_ 1312 AB_Wickelklappung_Reihe2_FA 0;
BA_ "GenSigSendType" SG_ 1312 AB_Wickelklappung_Reihe2_MI 3;
BA_ "GenSigStartValue" SG_ 1312 AB_Wickelklappung_Reihe2_MI 1;
BA_ "GenSigSwitchedByIgnition" SG_ 1312 AB_Wickelklappung_Reihe2_MI 0;
BA_ "GenSigSendType" SG_ 1312 Airbag_02_BZ 0;
BA_ "GenSigFuncType" SG_ 1312 Airbag_02_BZ 1;
BA_ "GenSigSwitchedByIgnition" SG_ 1312 Airbag_02_BZ 0;
BA_ "GenSigSendType" SG_ 1312 Airbag_02_CRC 0;
BA_ "GenSigFuncType" SG_ 1312 Airbag_02_CRC 2;
BA_ "GenSigSwitchedByIgnition" SG_ 1312 Airbag_02_CRC 0;
BA_ "GenSigSendType" SG_ 1312 LoGeWa_Event_Kombiwarnung 3;
BA_ "GenSigSwitchedByIgnition" SG_ 1312 LoGeWa_Event_Kombiwarnung 0;
BA_ "GenSigSendType" SG_ 1312 SC_PAO_OFF_Anf 3;
BA_ "GenSigSwitchedByIgnition" SG_ 1312 SC_PAO_OFF_Anf 0;
BA_ "GenSigSendType" SG_ 1312 SC_PAO_ON_Anf 3;
BA_ "GenSigSwitchedByIgnition" SG_ 1312 SC_PAO_ON_Anf 0;
BA_ "GenSigSendType" SG_ 1312 SC_PAO_Schriftzug_Anf 3;
BA_ "GenSigSwitchedByIgnition" SG_ 1312 SC_PAO_Schriftzug_Anf 0;
BA_ "GenSigSendType" SG_ 1349 AB_Anprall_Front 3;
BA_ "GenSigSwitchedByIgnition" SG_ 1349 AB_Anprall_Front 0;
BA_ "GenSigSendType" SG_ 1349 AB_Anprall_Heck 3;
BA_ "GenSigSwitchedByIgnition" SG_ 1349 AB_Anprall_Heck 0;
BA_ "GenSigSendType" SG_ 1349 AB_Belegung_VF_ext 3;
BA_ "GenSigStartValue" SG_ 1349 AB_Belegung_VF_ext 6;
BA_ "GenSigSwitchedByIgnition" SG_ 1349 AB_Belegung_VF_ext 0;
BA_ "Fehlerwert" SG_ 1349 AB_Belegung_VF_ext 7;
BA_ "GenSigSendType" SG_ 1349 AB_Belegung_VF_ext_aktiv 3;
BA_ "GenSigSwitchedByIgnition" SG_ 1349 AB_Belegung_VF_ext_aktiv 0;
BA_ "GenSigSendType" SG_ 1349 AB_Gurtwarn_Reihe2_BF 0;
BA_ "GenSigSwitchedByIgnition" SG_ 1349 AB_Gurtwarn_Reihe2_BF 0;
BA_ "GenSigSendType" SG_ 1349 AB_Gurtwarn_Reihe2_FA 0;
BA_ "GenSigSwitchedByIgnition" SG_ 1349 AB_Gurtwarn_Reihe2_FA 0;
BA_ "GenSigSendType" SG_ 1349 AB_Gurtwarn_Reihe2_MI 0;
BA_ "GenSigSwitchedByIgnition" SG_ 1349 AB_Gurtwarn_Reihe2_MI 0;
BA_ "GenSigSendType" SG_ 1349 AB_Gurtwarn_Reihe3_BF 0;
BA_ "GenSigSwitchedByIgnition" SG_ 1349 AB_Gurtwarn_Reihe3_BF 0;
BA_ "GenSigSendType" SG_ 1349 AB_Gurtwarn_Reihe3_FA 0;
BA_ "GenSigSwitchedByIgnition" SG_ 1349 AB_Gurtwarn_Reihe3_FA 0;
BA_ "GenSigSendType" SG_ 1349 AB_Gurtwarn_Reihe3_MI 0;
BA_ "GenSigSwitchedByIgnition" SG_ 1349 AB_Gurtwarn_Reihe3_MI 0;
BA_ "GenSigSendType" SG_ 1349 AB_Gurtwarn_Reihe4_BF 0;
BA_ "GenSigSwitchedByIgnition" SG_ 1349 AB_Gurtwarn_Reihe4_BF 0;
BA_ "GenSigSendType" SG_ 1349 AB_Gurtwarn_Reihe4_FA 0;
BA_ "GenSigSwitchedByIgnition" SG_ 1349 AB_Gurtwarn_Reihe4_FA 0;
BA_ "GenSigSendType" SG_ 1349 AB_Gurtwarn_Reihe4_MI 0;
BA_ "GenSigSwitchedByIgnition" SG_ 1349 AB_Gurtwarn_Reihe4_MI 0;
BA_ "GenSigSendType" SG_ 1349 AB_SBR_hinten_verbau 0;
BA_ "GenSigStartValue" SG_ 1349 AB_SBR_hinten_verbau 3;
BA_ "GenSigSwitchedByIgnition" SG_ 1349 AB_SBR_hinten_verbau 0;
BA_ "GenSigSendType" SG_ 1349 AbstWarn_MV_FAS_Fkt_Status 3;
BA_ "GenSigSwitchedByIgnition" SG_ 1349 AbstWarn_MV_FAS_Fkt_Status 0;
BA_ "Fehlerwert" SG_ 1349 AbstWarn_MV_FAS_Fkt_Status 3;
BA_ "GenSigSendType" SG_ 1349 Airbag_04_BZ 0;
BA_ "GenSigFuncType" SG_ 1349 Airbag_04_BZ 1;
BA_ "GenSigSwitchedByIgnition" SG_ 1349 Airbag_04_BZ 0;
BA_ "GenSigSendType" SG_ 1349 Airbag_04_CRC 0;
BA_ "GenSigFuncType" SG_ 1349 Airbag_04_CRC 2;
BA_ "GenSigSwitchedByIgnition" SG_ 1349 Airbag_04_CRC 0;
BA_ "GenSigSendType" SG_ 1349 AWV_Einstellung_System_ASG 3;
BA_ "GenSigSwitchedByIgnition" SG_ 1349 AWV_Einstellung_System_ASG 0;
BA_ "GenSigSendType" SG_ 1349 AWV_Einstellung_Warnung_ASG 3;
BA_ "GenSigSwitchedByIgnition" SG_ 1349 AWV_Einstellung_Warnung_ASG 0;
BA_ "GenSigSendType" SG_ 1349 LGI_FAS_Fkt_Status 3;
BA_ "GenSigSwitchedByIgnition" SG_ 1349 LGI_FAS_Fkt_Status 0;
BA_ "Fehlerwert" SG_ 1349 LGI_FAS_Fkt_Status 3;
BA_ "GenSigSendType" SG_ 1349 PreCrash_FAS_Fkt_Status 3;
BA_ "GenSigSwitchedByIgnition" SG_ 1349 PreCrash_FAS_Fkt_Status 0;
BA_ "Fehlerwert" SG_ 1349 PreCrash_FAS_Fkt_Status 3;
BA_ "GenSigSendType" SG_ 1349 SC_PreSense_Modus_System_KAS 3;
BA_ "GenSigSwitchedByIgnition" SG_ 1349 SC_PreSense_Modus_System_KAS 0;
BA_ "GenSigSendType" SG_ 1349 SC_PreSense_Modus_System_MV 3;
BA_ "GenSigSwitchedByIgnition" SG_ 1349 SC_PreSense_Modus_System_MV 0;
BA_ "GenSigSendType" SG_ 1349 SC_PreSense_Modus_System_NV 3;
BA_ "GenSigSwitchedByIgnition" SG_ 1349 SC_PreSense_Modus_System_NV 0;
BA_ "GenSigSendType" SG_ 1349 SC_PreSense_Modus_Warnung_MV 3;
BA_ "GenSigSwitchedByIgnition" SG_ 1349 SC_PreSense_Modus_Warnung_MV 0;
BA_ "GenSigSendType" SG_ 1349 SC_PreSense_Modus_Warnung_NV 3;
BA_ "GenSigSwitchedByIgnition" SG_ 1349 SC_PreSense_Modus_Warnung_NV 0;
BA_ "GenSigSendType" SG_ 1349 WarnBrems_Charisma_FahrPr 0;
BA_ "GenSigSendType" SG_ 1349 WarnBrems_Charisma_Status 0;
BA_ "GenSigSendType" SG_ 2527679722 AB_Anzeige_Kombi_SRAB 0;
BA_ "GenSigSendType" SG_ 2527679722 AB_Anzeige_Komfort_HBFS 0;
BA_ "GenSigSendType" SG_ 2527679722 AB_Anzeige_Komfort_HFS 0;
BA_ "GenSigSendType" SG_ 2527679722 AB_Anzeige_Sitz_Komfort_HBFS 0;
BA_ "GenSigSendType" SG_ 2527679722 AB_Anzeige_Sitz_Komfort_HFS 0;
BA_ "GenSigSendType" SG_ 2527679722 AB_Gurtschloss_MI 0;
BA_ "GenSigStartValue" SG_ 2527679722 AB_Gurtschloss_MI 1;
BA_ "GenSigSwitchedByIgnition" SG_ 2527679722 AB_Gurtschloss_MI 0;
BA_ "GenSigSendType" SG_ 2527679722 AB_Gurtschloss_Reihe4_BF 0;
BA_ "GenSigStartValue" SG_ 2527679722 AB_Gurtschloss_Reihe4_BF 1;
BA_ "GenSigSwitchedByIgnition" SG_ 2527679722 AB_Gurtschloss_Reihe4_BF 0;
BA_ "GenSigSendType" SG_ 2527679722 AB_Gurtschloss_Reihe4_FA 0;
BA_ "GenSigStartValue" SG_ 2527679722 AB_Gurtschloss_Reihe4_FA 1;
BA_ "GenSigSwitchedByIgnition" SG_ 2527679722 AB_Gurtschloss_Reihe4_FA 0;
BA_ "GenSigSendType" SG_ 2527679722 AB_Gurtschloss_Reihe4_MI 0;
BA_ "GenSigStartValue" SG_ 2527679722 AB_Gurtschloss_Reihe4_MI 1;
BA_ "GenSigSwitchedByIgnition" SG_ 2527679722 AB_Gurtschloss_Reihe4_MI 0;
BA_ "GenSigSendType" SG_ 2527679722 AB_Gurtwarn_VM 0;
BA_ "GenSigSwitchedByIgnition" SG_ 2527679722 AB_Gurtwarn_VM 0;
BA_ "GenSigSendType" SG_ 2527679722 AB_Status_Sitz_SRAB_HBFS 0;
BA_ "GenSigStartValue" SG_ 2527679722 AB_Status_Sitz_SRAB_HBFS 2;
BA_ "GenSigSwitchedByIgnition" SG_ 2527679722 AB_Status_Sitz_SRAB_HBFS 0;
BA_ "Fehlerwert" SG_ 2527679722 AB_Status_Sitz_SRAB_HBFS 3;
BA_ "GenSigSendType" SG_ 2527679722 AB_Status_Sitz_SRAB_HFS 0;
BA_ "GenSigStartValue" SG_ 2527679722 AB_Status_Sitz_SRAB_HFS 2;
BA_ "Fehlerwert" SG_ 2527679722 AB_Status_Sitz_SRAB_HFS 3;
BA_ "GenSigSendType" SG_ 2527679722 AB_wSBR_Batteriestatus 0;
BA_ "GenSigSwitchedByIgnition" SG_ 2527679722 AB_wSBR_Batteriestatus 0;
BA_ "GenSigSendType" SG_ 2527679722 Airbag_06_BZ 0;
BA_ "GenSigFuncType" SG_ 2527679722 Airbag_06_BZ 1;
BA_ "GenSigSwitchedByIgnition" SG_ 2527679722 Airbag_06_BZ 0;
BA_ "GenSigSendType" SG_ 2527679722 Airbag_06_CRC 0;
BA_ "GenSigFuncType" SG_ 2527679722 Airbag_06_CRC 2;
BA_ "GenSigSwitchedByIgnition" SG_ 2527679722 Airbag_06_CRC 0;
BA_ "GenSigSendType" SG_ 1633 AAG_Anhaenger_abgesteckt 0;
BA_ "GenSigSwitchedByIgnition" SG_ 1633 AAG_Anhaenger_abgesteckt 0;
BA_ "GenSigSendType" SG_ 1633 AAG_Anhaenger_erkannt 0;
BA_ "NWM-WakeupAllowed" SG_ 1633 AAG_Anhaenger_erkannt 1;
BA_ "GenSigSwitchedByIgnition" SG_ 1633 AAG_Anhaenger_erkannt 0;
BA_ "GenSigSendType" SG_ 1633 AAG_AVS_Fehler_02 0;
BA_ "GenSigSwitchedByIgnition" SG_ 1633 AAG_AVS_Fehler_02 0;
BA_ "Fehlerwert" SG_ 1633 AAG_AVS_Fehler_02 1;
BA_ "GenSigSendType" SG_ 1633 AAG_AVS_Fehler_02_inv 0;
BA_ "GenSigStartValue" SG_ 1633 AAG_AVS_Fehler_02_inv 1;
BA_ "GenSigSwitchedByIgnition" SG_ 1633 AAG_AVS_Fehler_02_inv 0;
BA_ "GenSigSendType" SG_ 1633 AAG_AVS_Stati 0;
BA_ "GenSigSwitchedByIgnition" SG_ 1633 AAG_AVS_Stati 0;
BA_ "GenSigSendType" SG_ 1633 AAG_Blinker_H_aktiv 0;
BA_ "GenSigSwitchedByIgnition" SG_ 1633 AAG_Blinker_H_aktiv 0;
BA_ "GenSigSendType" SG_ 1633 AAG_Blinker_HL_def 0;
BA_ "GenSigSwitchedByIgnition" SG_ 1633 AAG_Blinker_HL_def 0;
BA_ "GenSigSendType" SG_ 1633 AAG_Blinker_HR_def 0;
BA_ "GenSigSwitchedByIgnition" SG_ 1633 AAG_Blinker_HR_def 0;
BA_ "GenSigSendType" SG_ 1633 AAG_Bremsl_durch_ECD 0;
BA_ "GenSigSwitchedByIgnition" SG_ 1633 AAG_Bremsl_durch_ECD 0;
BA_ "GenSigSendType" SG_ 1633 AAG_Bremslicht_H_def 0;
BA_ "GenSigSwitchedByIgnition" SG_ 1633 AAG_Bremslicht_H_def 0;
BA_ "GenSigSendType" SG_ 1633 AAG_Bremslicht_Reku 0;
BA_ "GenSigSwitchedByIgnition" SG_ 1633 AAG_Bremslicht_Reku 0;
BA_ "GenSigSendType" SG_ 1633 AAG_BZ 0;
BA_ "GenSigFuncType" SG_ 1633 AAG_BZ 1;
BA_ "GenSigSwitchedByIgnition" SG_ 1633 AAG_BZ 0;
BA_ "GenSigSendType" SG_ 1633 AAG_LED_aktiv 0;
BA_ "GenSigSwitchedByIgnition" SG_ 1633 AAG_LED_aktiv 0;
BA_ "GenSigSendType" SG_ 1633 AAG_NSL_aktiv 0;
BA_ "GenSigSwitchedByIgnition" SG_ 1633 AAG_NSL_aktiv 0;
BA_ "GenSigSendType" SG_ 1633 AAG_Schlusslicht_HL_def 0;
BA_ "GenSigSwitchedByIgnition" SG_ 1633 AAG_Schlusslicht_HL_def 0;
BA_ "GenSigSendType" SG_ 1633 AAG_Schlusslicht_HR_def 0;
BA_ "GenSigSwitchedByIgnition" SG_ 1633 AAG_Schlusslicht_HR_def 0;
BA_ "GenSigSendType" SG_ 896 APS_Master_Sendestatus 5;
BA_ "GenSigSendType" SG_ 896 US_ACC_BZ 0;
BA_ "GenSigFuncType" SG_ 896 US_ACC_BZ 1;
BA_ "GenSigSendType" SG_ 896 US_ACC_CRC 0;
BA_ "GenSigFuncType" SG_ 896 US_ACC_CRC 2;
BA_ "GenSigSendType" SG_ 896 US_blindness_detected 0;
BA_ "GenSigSendType" SG_ 896 US_Freie_Weglaenge_Front 0;
BA_ "GenSigStartValue" SG_ 896 US_Freie_Weglaenge_Front 510;
BA_ "Fehlerwert" SG_ 896 US_Freie_Weglaenge_Front 511;
BA_ "GenSigSendType" SG_ 896 US_Freie_Weglaenge_Front_Typ 0;
BA_ "GenSigSendType" SG_ 896 US_Freie_Weglaenge_Heck 0;
BA_ "GenSigStartValue" SG_ 896 US_Freie_Weglaenge_Heck 510;
BA_ "GenSigSwitchedByIgnition" SG_ 896 US_Freie_Weglaenge_Heck 0;
BA_ "Fehlerwert" SG_ 896 US_Freie_Weglaenge_Heck 511;
BA_ "GenSigSendType" SG_ 896 US_Freie_Weglaenge_Heck_Typ 0;
BA_ "GenSigSwitchedByIgnition" SG_ 896 US_Freie_Weglaenge_Heck_Typ 0;
BA_ "GenSigSendType" SG_ 896 US_Freisicht_nio 0;
BA_ "GenSigSendType" SG_ 896 US_relevante_Nichtverfuegbarkeit 0;
BA_ "GenSigSendType" SG_ 896 US_relevanter_Fehler 0;
BA_ "GenSigSendType" SG_ 896 US_Sende_Modus 0;
BA_ "Fehlerwert" SG_ 896 US_Sende_Modus 15;
BA_ "GenSigSendType" SG_ 896 US_Sende_Modus_hinten 0;
BA_ "Fehlerwert" SG_ 896 US_Sende_Modus_hinten 15;
BA_ "GenSigSendType" SG_ 345 ARA_Aktiver_Grafikmodus 0;
BA_ "GenSigSendType" SG_ 345 ARA_Bremsfuss 0;
BA_ "GenSigSendType" SG_ 345 ARA_Deaktivierung_sperren 3;
BA_ "GenSigSendType" SG_ 345 ARA_Knickwinkel_Ist 3;
BA_ "GenSigStartValue" SG_ 345 ARA_Knickwinkel_Ist 254;
BA_ "Fehlerwert" SG_ 345 ARA_Knickwinkel_Ist 255;
BA_ "GenSigSendType" SG_ 345 ARA_Knickwinkel_Komfort 3;
BA_ "GenSigStartValue" SG_ 345 ARA_Knickwinkel_Komfort 62;
BA_ "GenSigSwitchedByIgnition" SG_ 345 ARA_Knickwinkel_Komfort 0;
BA_ "Fehlerwert" SG_ 345 ARA_Knickwinkel_Komfort 63;
BA_ "GenSigSendType" SG_ 345 ARA_Knickwinkel_Konfidenz 0;
BA_ "GenSigStartValue" SG_ 345 ARA_Knickwinkel_Konfidenz 126;
BA_ "GenSigSwitchedByIgnition" SG_ 345 ARA_Knickwinkel_Konfidenz 0;
BA_ "Fehlerwert" SG_ 345 ARA_Knickwinkel_Konfidenz 127;
BA_ "GenSigSendType" SG_ 345 ARA_Knickwinkel_Max 3;
BA_ "GenSigStartValue" SG_ 345 ARA_Knickwinkel_Max 126;
BA_ "Fehlerwert" SG_ 345 ARA_Knickwinkel_Max 127;
BA_ "GenSigSendType" SG_ 345 ARA_Knickwinkel_Soll 3;
BA_ "GenSigStartValue" SG_ 345 ARA_Knickwinkel_Soll 254;
BA_ "Fehlerwert" SG_ 345 ARA_Knickwinkel_Soll 255;
BA_ "GenSigSendType" SG_ 345 ARA_Modus 0;
BA_ "GenSigSendType" SG_ 345 ARA_Modus_Anf 0;
BA_ "GenSigSendType" SG_ 345 ARA_Sensor_Aktivierung 3;
BA_ "GenSigSendType" SG_ 345 ARA_Status 3;
BA_ "GenSigStartValue" SG_ 345 ARA_Status 1;
BA_ "Fehlerwert" SG_ 345 ARA_Status 2;
BA_ "GenSigSendType" SG_ 345 ARA_Texte 0;
BA_ "Fehlerwert" SG_ 345 ARA_Texte 63;
BA_ "GenSigSendType" SG_ 2527679661 AWV_AW_Abstand 3;
BA_ "GenSigStartValue" SG_ 2527679661 AWV_AW_Abstand 511;
BA_ "GenSigSendType" SG_ 2527679661 AWV_AW_Texte 3;
BA_ "GenSigSendType" SG_ 2527679661 AWV_AW_Texte_Zusatzanzeige 3;
BA_ "GenSigSendType" SG_ 2527679661 AWV_AW_Zeitluecke 3;
BA_ "GenSigSendType" SG_ 2527679661 AWV_Einstellung_System_FSG 3;
BA_ "GenSigSendType" SG_ 2527679661 AWV_Einstellung_Warnung_FSG 3;
BA_ "GenSigSendType" SG_ 2527679661 AWV_KA_Konfiguration 3;
BA_ "GenSigSendType" SG_ 2527679661 AWV_KA_ObjektFront 3;
BA_ "GenSigSendType" SG_ 2527679661 AWV_Kamera_Objekt_ID 3;
BA_ "GenSigSwitchedByIgnition" SG_ 2527679661 AWV_Kamera_Objekt_ID 0;
BA_ "GenSigSendType" SG_ 2527679661 AWV_LED_Leiste 3;
BA_ "GenSigSendType" SG_ 2527679661 AWV_Priowarnung 3;
BA_ "GenSigSendType" SG_ 2527679661 AWV_Status_Anzeige 3;
BA_ "GenSigSendType" SG_ 2527679661 AWV_Texte_02 3;
BA_ "GenSigSendType" SG_ 2527679661 AWV_Warnlevel 3;
BA_ "GenSigSendType" SG_ 2527679661 AWV_Warnung 3;
BA_ "GenSigSendType" SG_ 2527679661 AWV_Warnung_Richtung 3;
BA_ "GenSigSendType" SG_ 2527679661 WBA_Warnblinken 3;
BA_ "GenSigSendType" SG_ 2463978752 AZK_Kessy_defekt 4;
BA_ "GenSigSwitchedByIgnition" SG_ 2463978752 AZK_Kessy_defekt 0;
BA_ "GenSigSendType" SG_ 2463978752 AZK_Kessy_nicht_gefunden 4;
BA_ "GenSigSwitchedByIgnition" SG_ 2463978752 AZK_Kessy_nicht_gefunden 0;
BA_ "GenSigSendType" SG_ 2463978752 AZK_MobileKey_defekt 4;
BA_ "GenSigSwitchedByIgnition" SG_ 2463978752 AZK_MobileKey_defekt 0;
BA_ "GenSigSendType" SG_ 2463978752 AZK_Mobilgeraet_nicht_gefunden 4;
BA_ "GenSigSwitchedByIgnition" SG_ 2463978752 AZK_Mobilgeraet_nicht_gefunden 0;
BA_ "GenSigSendType" SG_ 2463978752 AZK_Schluessel_im_Fzg 4;
BA_ "GenSigSwitchedByIgnition" SG_ 2463978752 AZK_Schluessel_im_Fzg 0;
BA_ "GenSigSendType" SG_ 2463978752 AZK_Schluessel_nicht_gefunden 4;
BA_ "GenSigSwitchedByIgnition" SG_ 2463978752 AZK_Schluessel_nicht_gefunden 0;
BA_ "GenSigSendType" SG_ 2463978752 AZK_Weiterfahrt_mit_Mobilgeraet 4;
BA_ "GenSigSwitchedByIgnition" SG_ 2463978752 AZK_Weiterfahrt_mit_Mobilgeraet 0;
BA_ "GenSigSendType" SG_ 2463978752 AZK_Weiterfahrt_mit_Schluessel 4;
BA_ "GenSigSwitchedByIgnition" SG_ 2463978752 AZK_Weiterfahrt_mit_Schluessel 0;
BA_ "GenSigSendType" SG_ 2536704256 BAP_Aussenlicht_ASG_01_Header 3;
BA_ "GenSigSwitchedByIgnition" SG_ 2536704256 BAP_Aussenlicht_ASG_01_Header 0;
BA_ "GenSigSendType" SG_ 2536704257 BAP_Aussenlicht_ASG_02_Header 3;
BA_ "GenSigSwitchedByIgnition" SG_ 2536704257 BAP_Aussenlicht_ASG_02_Header 0;
BA_ "GenSigSendType" SG_ 2536704272 BAP_Aussenlicht_FSG_01_Header 3;
BA_ "GenSigSwitchedByIgnition" SG_ 2536704272 BAP_Aussenlicht_FSG_01_Header 0;
BA_ "GenSigSendType" SG_ 2536726786 BAP_Car2X_ASG_03_Header 3;
BA_ "GenSigSwitchedByIgnition" SG_ 2536726786 BAP_Car2X_ASG_03_Header 0;
BA_ "GenSigSendType" SG_ 2536726802 BAP_Car2X_FSG_03_Header 3;
BA_ "GenSigSwitchedByIgnition" SG_ 2536726802 BAP_Car2X_FSG_03_Header 0;
BA_ "GenSigSendType" SG_ 2536767264 BAP_Debug_Cmd 3;
BA_ "GenSigSwitchedByIgnition" SG_ 2536767264 BAP_Debug_Cmd 0;
BA_ "GenSigSendType" SG_ 2536767280 BAP_Debug_Data 3;
BA_ "GenSigSwitchedByIgnition" SG_ 2536767280 BAP_Debug_Data 0;
BA_ "GenSigSendType" SG_ 2536705280 BAP_Doorlocking_ASG_01_Header 3;
BA_ "GenSigSwitchedByIgnition" SG_ 2536705280 BAP_Doorlocking_ASG_01_Header 0;
BA_ "GenSigSendType" SG_ 2536705281 BAP_Doorlocking_ASG_02_Header 3;
BA_ "GenSigSwitchedByIgnition" SG_ 2536705281 BAP_Doorlocking_ASG_02_Header 0;
BA_ "GenSigSendType" SG_ 2536705282 BAP_Doorlocking_ASG_03_Header 3;
BA_ "GenSigSwitchedByIgnition" SG_ 2536705282 BAP_Doorlocking_ASG_03_Header 0;
BA_ "GenSigSendType" SG_ 2536705296 BAP_Doorlocking_FSG_01_Header 3;
BA_ "GenSigSwitchedByIgnition" SG_ 2536705296 BAP_Doorlocking_FSG_01_Header 0;
BA_ "GenSigSendType" SG_ 2536727296 BAP_Doors2_ASG_01_Header 3;
BA_ "GenSigSwitchedByIgnition" SG_ 2536727296 BAP_Doors2_ASG_01_Header 0;
BA_ "GenSigSendType" SG_ 2536727312 BAP_Doors2_FSG_01_Header 3;
BA_ "GenSigSwitchedByIgnition" SG_ 2536727312 BAP_Doors2_FSG_01_Header 0;
BA_ "GenSigSendType" SG_ 2536724736 BAP_Doors_ASG_01_Header 3;
BA_ "GenSigSwitchedByIgnition" SG_ 2536724736 BAP_Doors_ASG_01_Header 0;
BA_ "GenSigSendType" SG_ 2536724752 BAP_Doors_FSG_01_Header 3;
BA_ "GenSigSwitchedByIgnition" SG_ 2536724752 BAP_Doors_FSG_01_Header 0;
BA_ "GenSigSendType" SG_ 2536724480 BAP_ENI2_ASG_01_Header 3;
BA_ "GenSigSwitchedByIgnition" SG_ 2536724480 BAP_ENI2_ASG_01_Header 0;
BA_ "GenSigSendType" SG_ 2536724481 BAP_ENI2_ASG_02_Header 3;
BA_ "GenSigSwitchedByIgnition" SG_ 2536724481 BAP_ENI2_ASG_02_Header 0;
BA_ "GenSigSendType" SG_ 2536724496 BAP_ENI2_FSG_01_Header 3;
BA_ "GenSigSwitchedByIgnition" SG_ 2536724496 BAP_ENI2_FSG_01_Header 0;
BA_ "GenSigSendType" SG_ 2536724497 BAP_ENI2_FSG_02_Header 3;
BA_ "GenSigSwitchedByIgnition" SG_ 2536724497 BAP_ENI2_FSG_02_Header 0;
BA_ "GenSigSendType" SG_ 2536707072 BAP_Homelink_ASG_01_Header 3;
BA_ "GenSigSwitchedByIgnition" SG_ 2536707072 BAP_Homelink_ASG_01_Header 0;
BA_ "GenSigSendType" SG_ 2536707088 BAP_Homelink_FSG_01_Header 3;
BA_ "GenSigSwitchedByIgnition" SG_ 2536707088 BAP_Homelink_FSG_01_Header 0;
BA_ "GenSigSendType" SG_ 2536722946 BAP_IAA_PSO_ASG_03_Header 3;
BA_ "GenSigSwitchedByIgnition" SG_ 2536722946 BAP_IAA_PSO_ASG_03_Header 0;
BA_ "GenSigSendType" SG_ 2536722960 BAP_IAA_PSO_FSG_01_Header 3;
BA_ "GenSigSwitchedByIgnition" SG_ 2536722960 BAP_IAA_PSO_FSG_01_Header 0;
BA_ "GenSigSendType" SG_ 2536704000 BAP_Innenlicht_ASG_01_Header 3;
BA_ "GenSigSwitchedByIgnition" SG_ 2536704000 BAP_Innenlicht_ASG_01_Header 0;
BA_ "GenSigSendType" SG_ 2536704001 BAP_Innenlicht_ASG_02_Header 3;
BA_ "GenSigSwitchedByIgnition" SG_ 2536704001 BAP_Innenlicht_ASG_02_Header 0;
BA_ "GenSigSendType" SG_ 2536704003 BAP_Innenlicht_ASG_04_Header 3;
BA_ "GenSigSwitchedByIgnition" SG_ 2536704003 BAP_Innenlicht_ASG_04_Header 0;
BA_ "GenSigSendType" SG_ 2536704016 BAP_Innenlicht_FSG_01_Header 3;
BA_ "GenSigSwitchedByIgnition" SG_ 2536704016 BAP_Innenlicht_FSG_01_Header 0;
BA_ "GenSigSendType" SG_ 2536705536 BAP_Mirror_ASG_01_Header 3;
BA_ "GenSigSwitchedByIgnition" SG_ 2536705536 BAP_Mirror_ASG_01_Header 0;
BA_ "GenSigSendType" SG_ 2536705537 BAP_Mirror_ASG_02_Header 3;
BA_ "GenSigSwitchedByIgnition" SG_ 2536705537 BAP_Mirror_ASG_02_Header 0;
BA_ "GenSigSendType" SG_ 2536705552 BAP_Mirror_FSG_01_Header 3;
BA_ "GenSigSwitchedByIgnition" SG_ 2536705552 BAP_Mirror_FSG_01_Header 0;
BA_ "GenSigSendType" SG_ 2536732416 BAP_MobDevKey_ASG_01_Header 3;
BA_ "GenSigSwitchedByIgnition" SG_ 2536732416 BAP_MobDevKey_ASG_01_Header 0;
BA_ "GenSigSendType" SG_ 2536732417 BAP_MobDevKey_ASG_02_Header 3;
BA_ "GenSigSwitchedByIgnition" SG_ 2536732417 BAP_MobDevKey_ASG_02_Header 0;
BA_ "GenSigSendType" SG_ 2536732432 BAP_MobDevKey_FSG_01_Header 3;
BA_ "GenSigSwitchedByIgnition" SG_ 2536732432 BAP_MobDevKey_FSG_01_Header 0;
BA_ "GenSigSendType" SG_ 2536734464 BAP_MobDevKeyOnline_ASG_01_Heade 3;
BA_ "GenSigSwitchedByIgnition" SG_ 2536734464 BAP_MobDevKeyOnline_ASG_01_Heade 0;
BA_ "GenSigSendType" SG_ 2536734480 BAP_MobDevKeyOnline_FSG_01_Heade 3;
BA_ "GenSigSwitchedByIgnition" SG_ 2536734480 BAP_MobDevKeyOnline_FSG_01_Heade 0;
BA_ "GenSigSendType" SG_ 2536704517 BAP_OPS_ASG_06_Header 3;
BA_ "GenSigSwitchedByIgnition" SG_ 2536704517 BAP_OPS_ASG_06_Header 0;
BA_ "GenSigSendType" SG_ 2536704528 BAP_OPS_FSG_01_Header 3;
BA_ "GenSigSwitchedByIgnition" SG_ 2536704528 BAP_OPS_FSG_01_Header 0;
BA_ "GenSigSendType" SG_ 2536704529 BAP_OPS_FSG_02_Header 3;
BA_ "GenSigSwitchedByIgnition" SG_ 2536704529 BAP_OPS_FSG_02_Header 0;
BA_ "GenSigSendType" SG_ 2536721920 BAP_RemoteServices_ASG_01_Header 3;
BA_ "GenSigSwitchedByIgnition" SG_ 2536721920 BAP_RemoteServices_ASG_01_Header 0;
BA_ "GenSigSendType" SG_ 2536721921 BAP_RemoteServices_ASG_02_Header 3;
BA_ "GenSigSwitchedByIgnition" SG_ 2536721921 BAP_RemoteServices_ASG_02_Header 0;
BA_ "GenSigSendType" SG_ 2536721936 BAP_RemoteServices_FSG_01_Header 3;
BA_ "GenSigSwitchedByIgnition" SG_ 2536721936 BAP_RemoteServices_FSG_01_Header 0;
BA_ "GenSigSendType" SG_ 2536731904 BAP_RollingAbility_ASG_01_Header 3;
BA_ "GenSigSwitchedByIgnition" SG_ 2536731904 BAP_RollingAbility_ASG_01_Header 0;
BA_ "GenSigSendType" SG_ 2536731920 BAP_RollingAbility_FSG_01_Header 3;
BA_ "GenSigSwitchedByIgnition" SG_ 2536731920 BAP_RollingAbility_FSG_01_Header 0;
BA_ "GenSigSendType" SG_ 2536730624 BAP_RSO_ASG_01_Header 3;
BA_ "GenSigSwitchedByIgnition" SG_ 2536730624 BAP_RSO_ASG_01_Header 0;
BA_ "GenSigSendType" SG_ 2536730640 BAP_RSO_FSG_01_Header 3;
BA_ "GenSigSwitchedByIgnition" SG_ 2536730640 BAP_RSO_FSG_01_Header 0;
BA_ "GenSigSendType" SG_ 2536717056 BAP_SeatPneumatic_ASG_01_Header 3;
BA_ "GenSigSwitchedByIgnition" SG_ 2536717056 BAP_SeatPneumatic_ASG_01_Header 0;
BA_ "GenSigSendType" SG_ 2536717057 BAP_SeatPneumatic_ASG_02_Header 3;
BA_ "GenSigSwitchedByIgnition" SG_ 2536717057 BAP_SeatPneumatic_ASG_02_Header 0;
BA_ "GenSigSendType" SG_ 2536717072 BAP_SeatPneumatic_FSG_01_Header 3;
BA_ "GenSigSwitchedByIgnition" SG_ 2536717072 BAP_SeatPneumatic_FSG_01_Header 0;
BA_ "GenSigSendType" SG_ 2536705024 BAP_Wiper_ASG_01_Header 3;
BA_ "GenSigSwitchedByIgnition" SG_ 2536705024 BAP_Wiper_ASG_01_Header 0;
BA_ "GenSigSendType" SG_ 2536705025 BAP_Wiper_ASG_02_Header 3;
BA_ "GenSigSwitchedByIgnition" SG_ 2536705025 BAP_Wiper_ASG_02_Header 0;
BA_ "GenSigSendType" SG_ 2536705040 BAP_Wiper_FSG_01_Header 3;
BA_ "GenSigSwitchedByIgnition" SG_ 2536705040 BAP_Wiper_FSG_01_Header 0;
BA_ "GenSigSendType" SG_ 2583694872 BCM1_AuthTime_Req_Data 3;
BA_ "GenSigFuncType" SG_ 2583694872 BCM1_AuthTime_Req_Data 9;
BA_ "GenSigSwitchedByIgnition" SG_ 2583694872 BCM1_AuthTime_Req_Data 0;
BA_ "GenSigSendType" SG_ 2583825944 BCM1_AuthTime_Resp_Data 3;
BA_ "GenSigFuncType" SG_ 2583825944 BCM1_AuthTime_Resp_Data 9;
BA_ "GenSigSwitchedByIgnition" SG_ 2583825944 BCM1_AuthTime_Resp_Data 0;
BA_ "GenSigSendType" SG_ 2527679636 BCM1_DML_AbbiegeWa_Variante 3;
BA_ "GenSigSwitchedByIgnition" SG_ 2527679636 BCM1_DML_AbbiegeWa_Variante 0;
BA_ "GenSigSendType" SG_ 2527679636 BCM1_DML_AbsAss_Variante 3;
BA_ "GenSigSwitchedByIgnition" SG_ 2527679636 BCM1_DML_AbsAss_Variante 0;
BA_ "GenSigSendType" SG_ 2527679636 BCM1_DML_AccAss_Variante 3;
BA_ "GenSigSwitchedByIgnition" SG_ 2527679636 BCM1_DML_AccAss_Variante 0;
BA_ "GenSigSendType" SG_ 2527679636 BCM1_DML_aCH_Variante 3;
BA_ "GenSigSwitchedByIgnition" SG_ 2527679636 BCM1_DML_aCH_Variante 0;
BA_ "GenSigSendType" SG_ 2527679636 BCM1_DML_aLH_Variante 3;
BA_ "GenSigSwitchedByIgnition" SG_ 2527679636 BCM1_DML_aLH_Variante 0;
BA_ "GenSigSendType" SG_ 2527679636 BCM1_DML_Aussteigelicht_aktiv 3;
BA_ "GenSigSwitchedByIgnition" SG_ 2527679636 BCM1_DML_Aussteigelicht_aktiv 0;
BA_ "GenSigSendType" SG_ 2527679636 BCM1_DML_BauLi_Variante 3;
BA_ "GenSigSwitchedByIgnition" SG_ 2527679636 BCM1_DML_BauLi_Variante 0;
BA_ "GenSigSendType" SG_ 2527679636 BCM1_DML_BeAss_Variante 3;
BA_ "GenSigSwitchedByIgnition" SG_ 2527679636 BCM1_DML_BeAss_Variante 0;
BA_ "GenSigSendType" SG_ 2527679636 BCM1_DML_EffAss_Variante 3;
BA_ "GenSigSwitchedByIgnition" SG_ 2527679636 BCM1_DML_EffAss_Variante 0;
BA_ "GenSigSendType" SG_ 2527679636 BCM1_DML_Einsteigelicht_aktiv 3;
BA_ "GenSigSwitchedByIgnition" SG_ 2527679636 BCM1_DML_Einsteigelicht_aktiv 0;
BA_ "GenSigSendType" SG_ 2527679636 BCM1_DML_Fahrbereit 3;
BA_ "GenSigSwitchedByIgnition" SG_ 2527679636 BCM1_DML_Fahrbereit 0;
BA_ "GenSigSendType" SG_ 2527679636 BCM1_DML_Lichtassistenz_aktiv 3;
BA_ "GenSigSwitchedByIgnition" SG_ 2527679636 BCM1_DML_Lichtassistenz_aktiv 0;
BA_ "GenSigSendType" SG_ 2527679636 BCM1_DML_Lichtfuehrung_aktiv 3;
BA_ "GenSigSwitchedByIgnition" SG_ 2527679636 BCM1_DML_Lichtfuehrung_aktiv 0;
BA_ "GenSigSendType" SG_ 2527679636 BCM1_DML_PreSAss_Variante 3;
BA_ "GenSigSwitchedByIgnition" SG_ 2527679636 BCM1_DML_PreSAss_Variante 0;
BA_ "GenSigSendType" SG_ 2527679636 BCM1_DML_RouLi_Variante 3;
BA_ "GenSigSwitchedByIgnition" SG_ 2527679636 BCM1_DML_RouLi_Variante 0;
BA_ "GenSigSendType" SG_ 2527679636 BCM1_DML_SitLi_Variante 3;
BA_ "GenSigSwitchedByIgnition" SG_ 2527679636 BCM1_DML_SitLi_Variante 0;
BA_ "GenSigSendType" SG_ 2527679636 BCM1_DML_SpuLi_Variante 3;
BA_ "GenSigSwitchedByIgnition" SG_ 2527679636 BCM1_DML_SpuLi_Variante 0;
BA_ "GenSigSendType" SG_ 2527679636 BCM1_DML_TraLi_Variante 3;
BA_ "GenSigSwitchedByIgnition" SG_ 2527679636 BCM1_DML_TraLi_Variante 0;
BA_ "GenSigSendType" SG_ 1626 APS_Tongeber_defekt 3;
BA_ "GenSigSwitchedByIgnition" SG_ 1626 APS_Tongeber_defekt 0;
BA_ "GenSigSendType" SG_ 1626 BCM1_AFS_Lampe 3;
BA_ "GenSigSwitchedByIgnition" SG_ 1626 BCM1_AFS_Lampe 0;
BA_ "GenSigSendType" SG_ 1626 BCM1_EasyEntry_Status 3;
BA_ "GenSigSwitchedByIgnition" SG_ 1626 BCM1_EasyEntry_Status 0;
BA_ "GenSigSendType" SG_ 1626 BCM1_Fahrlicht_Hinweis 3;
BA_ "GenSigSwitchedByIgnition" SG_ 1626 BCM1_Fahrlicht_Hinweis 0;
BA_ "GenSigSendType" SG_ 1626 BCM1_Hinweis_Lichtnachlauf 3;
BA_ "GenSigSwitchedByIgnition" SG_ 1626 BCM1_Hinweis_Lichtnachlauf 0;
BA_ "GenSigSendType" SG_ 1626 BCM1_Kl_15_HW_erkannt 3;
BA_ "GenSigSwitchedByIgnition" SG_ 1626 BCM1_Kl_15_HW_erkannt 0;
BA_ "GenSigSendType" SG_ 1626 BCM1_Kl_15_Sig_HW_erkannt 3;
BA_ "GenSigSwitchedByIgnition" SG_ 1626 BCM1_Kl_15_Sig_HW_erkannt 0;
BA_ "GenSigSendType" SG_ 1626 BCM1_LDS_Stellung 3;
BA_ "GenSigSwitchedByIgnition" SG_ 1626 BCM1_LDS_Stellung 0;
BA_ "Fehlerwert" SG_ 1626 BCM1_LDS_Stellung 7;
BA_ "GenSigSendType" SG_ 1626 BCM1_Lenksaeule_aktiv 3;
BA_ "GenSigSwitchedByIgnition" SG_ 1626 BCM1_Lenksaeule_aktiv 0;
BA_ "GenSigSendType" SG_ 1626 BCM1_Licht_Warn 3;
BA_ "GenSigSwitchedByIgnition" SG_ 1626 BCM1_Licht_Warn 0;
BA_ "GenSigSendType" SG_ 1626 BCM1_Lichtwarn_Texte 3;
BA_ "GenSigSwitchedByIgnition" SG_ 1626 BCM1_Lichtwarn_Texte 0;
BA_ "GenSigSendType" SG_ 1626 BCM1_MH_Schalter 3;
BA_ "GenSigSwitchedByIgnition" SG_ 1626 BCM1_MH_Schalter 0;
BA_ "GenSigSendType" SG_ 1626 BCM1_MH_WIV_Schalter 3;
BA_ "GenSigSwitchedByIgnition" SG_ 1626 BCM1_MH_WIV_Schalter 0;
BA_ "GenSigSendType" SG_ 1626 BCM1_NV_Taster 0;
BA_ "GenSigSwitchedByIgnition" SG_ 1626 BCM1_NV_Taster 0;
BA_ "GenSigSendType" SG_ 1626 BCM1_Reisemodus_Texte 3;
BA_ "GenSigSwitchedByIgnition" SG_ 1626 BCM1_Reisemodus_Texte 0;
BA_ "GenSigSendType" SG_ 1626 BCM1_Rueckfahrlicht_Schalter 3;
BA_ "GenSigSwitchedByIgnition" SG_ 1626 BCM1_Rueckfahrlicht_Schalter 0;
BA_ "GenSigSendType" SG_ 1626 BCM1_Spannungs_Anf 3;
BA_ "GenSigSwitchedByIgnition" SG_ 1626 BCM1_Spannungs_Anf 0;
BA_ "GenSigSendType" SG_ 1626 BCM1_Valet_Parking_Taster 0;
BA_ "GenSigSwitchedByIgnition" SG_ 1626 BCM1_Valet_Parking_Taster 0;
BA_ "GenSigSendType" SG_ 1626 BCM1_Warnblink_Taster 3;
BA_ "GenSigSwitchedByIgnition" SG_ 1626 BCM1_Warnblink_Taster 0;
BA_ "GenSigSendType" SG_ 1626 BCM_Anf_AAW_MoLaWa 3;
BA_ "GenSigSwitchedByIgnition" SG_ 1626 BCM_Anf_AAW_MoLaWa 0;
BA_ "GenSigSendType" SG_ 1626 BCM_Bremsbelag_Sensor 3;
BA_ "GenSigSwitchedByIgnition" SG_ 1626 BCM_Bremsbelag_Sensor 0;
BA_ "GenSigSendType" SG_ 1626 BCM_Bremsfluessigkeit_Sensor 3;
BA_ "GenSigSwitchedByIgnition" SG_ 1626 BCM_Bremsfluessigkeit_Sensor 0;
BA_ "GenSigSendType" SG_ 1626 BCM_Charisma_Taste2 3;
BA_ "GenSigSwitchedByIgnition" SG_ 1626 BCM_Charisma_Taste2 0;
BA_ "GenSigSendType" SG_ 1626 BCM_Eco_Charisma_Taste 3;
BA_ "GenSigSwitchedByIgnition" SG_ 1626 BCM_Eco_Charisma_Taste 0;
BA_ "GenSigSendType" SG_ 1626 BCM_Handbremse_Hinweis 4;
BA_ "GenSigSwitchedByIgnition" SG_ 1626 BCM_Handbremse_Hinweis 0;
BA_ "GenSigSendType" SG_ 1626 BCM_HBFS_EOE_aktiv 4;
BA_ "GenSigSwitchedByIgnition" SG_ 1626 BCM_HBFS_EOE_aktiv 0;
BA_ "GenSigSendType" SG_ 1626 BCM_HDF_betaetigt 4;
BA_ "GenSigSwitchedByIgnition" SG_ 1626 BCM_HDF_betaetigt 0;
BA_ "GenSigSendType" SG_ 1626 BCM_HFS_EOE_aktiv 4;
BA_ "GenSigSwitchedByIgnition" SG_ 1626 BCM_HFS_EOE_aktiv 0;
BA_ "GenSigSendType" SG_ 1626 BCM_Hybrid_StartStopp_Taste 3;
BA_ "GenSigSwitchedByIgnition" SG_ 1626 BCM_Hybrid_StartStopp_Taste 0;
BA_ "GenSigSendType" SG_ 1626 BCM_Hybrid_StSt_Taste_Fehler 3;
BA_ "GenSigSwitchedByIgnition" SG_ 1626 BCM_Hybrid_StSt_Taste_Fehler 0;
BA_ "GenSigSendType" SG_ 1626 BCM_Kuehlmittel_Sensor 3;
BA_ "GenSigSwitchedByIgnition" SG_ 1626 BCM_Kuehlmittel_Sensor 0;
BA_ "GenSigSendType" SG_ 1626 BCM_Kuehlmittel_Sensor_02 3;
BA_ "GenSigSwitchedByIgnition" SG_ 1626 BCM_Kuehlmittel_Sensor_02 0;
BA_ "GenSigSendType" SG_ 1626 BCM_Offroad_Taste 3;
BA_ "GenSigSwitchedByIgnition" SG_ 1626 BCM_Offroad_Taste 0;
BA_ "GenSigSendType" SG_ 1626 BCM_ValetTaster_Fkts_LED 4;
BA_ "GenSigSwitchedByIgnition" SG_ 1626 BCM_ValetTaster_Fkts_LED 0;
BA_ "GenSigSendType" SG_ 1626 BCM_Waehlhebel_P_Hinweis 4;
BA_ "GenSigSwitchedByIgnition" SG_ 1626 BCM_Waehlhebel_P_Hinweis 0;
BA_ "GenSigSendType" SG_ 1626 BCM_Waschwasser_Sensor 3;
BA_ "GenSigSwitchedByIgnition" SG_ 1626 BCM_Waschwasser_Sensor 0;
BA_ "GenSigSendType" SG_ 1626 DWA_Alarmquelle 0;
BA_ "GenSigStartValue" SG_ 1626 DWA_Alarmquelle 30;
BA_ "GenSigSwitchedByIgnition" SG_ 1626 DWA_Alarmquelle 0;
BA_ "Fehlerwert" SG_ 1626 DWA_Alarmquelle 31;
BA_ "GenSigSendType" SG_ 1626 DWA_Einschraenkung 0;
BA_ "GenSigSwitchedByIgnition" SG_ 1626 DWA_Einschraenkung 0;
BA_ "Fehlerwert" SG_ 1626 DWA_Einschraenkung 1;
BA_ "GenSigSendType" SG_ 1626 Gong_TFL_Umschaltung 3;
BA_ "GenSigSwitchedByIgnition" SG_ 1626 Gong_TFL_Umschaltung 0;
BA_ "GenSigSendType" SG_ 1626 LRH_Taster 3;
BA_ "GenSigSwitchedByIgnition" SG_ 1626 LRH_Taster 0;
BA_ "GenSigSendType" SG_ 2527679637 BCM_anf_VLW 3;
BA_ "GenSigSwitchedByIgnition" SG_ 2527679637 BCM_anf_VLW 0;
BA_ "GenSigSendType" SG_ 2527679637 BCM_Defrost_Taste 3;
BA_ "GenSigStartValue" SG_ 2527679637 BCM_Defrost_Taste 3;
BA_ "GenSigSwitchedByIgnition" SG_ 2527679637 BCM_Defrost_Taste 0;
BA_ "Fehlerwert" SG_ 2527679637 BCM_Defrost_Taste 2;
BA_ "GenSigSendType" SG_ 2527679637 BCM_FAS_Taster 4;
BA_ "GenSigSwitchedByIgnition" SG_ 2527679637 BCM_FAS_Taster 0;
BA_ "GenSigSendType" SG_ 2527679637 BCM_FSH_Taste 3;
BA_ "GenSigStartValue" SG_ 2527679637 BCM_FSH_Taste 3;
BA_ "GenSigSwitchedByIgnition" SG_ 2527679637 BCM_FSH_Taste 0;
BA_ "Fehlerwert" SG_ 2527679637 BCM_FSH_Taste 2;
BA_ "GenSigSendType" SG_ 2527679637 BCM_HSH_Taste 3;
BA_ "GenSigStartValue" SG_ 2527679637 BCM_HSH_Taste 3;
BA_ "GenSigSwitchedByIgnition" SG_ 2527679637 BCM_HSH_Taste 0;
BA_ "Fehlerwert" SG_ 2527679637 BCM_HSH_Taste 2;
BA_ "GenSigSendType" SG_ 2527679637 BCM_LTM_Allwetterl_Status 3;
BA_ "GenSigSwitchedByIgnition" SG_ 2527679637 BCM_LTM_Allwetterl_Status 0;
BA_ "GenSigSendType" SG_ 2527679637 BCM_LTM_Nebell_Status 3;
BA_ "GenSigSwitchedByIgnition" SG_ 2527679637 BCM_LTM_Nebell_Status 0;
BA_ "GenSigSendType" SG_ 2527679637 BCM_LTM_Nebelschluss_Status 3;
BA_ "GenSigSwitchedByIgnition" SG_ 2527679637 BCM_LTM_Nebelschluss_Status 0;
BA_ "GenSigSendType" SG_ 2527679637 BCM_LTM_PopUp_Anf 3;
BA_ "GenSigSwitchedByIgnition" SG_ 2527679637 BCM_LTM_PopUp_Anf 0;
BA_ "GenSigSendType" SG_ 2527679637 BCM_LTM_PopUp_Inhalt 3;
BA_ "GenSigSwitchedByIgnition" SG_ 2527679637 BCM_LTM_PopUp_Inhalt 0;
BA_ "GenSigSendType" SG_ 2527679637 BCM_LTM_PopUp_Status 3;
BA_ "GenSigSwitchedByIgnition" SG_ 2527679637 BCM_LTM_PopUp_Status 0;
BA_ "GenSigSendType" SG_ 2527679637 BCM_LTM_PopUp_Texte 3;
BA_ "GenSigSwitchedByIgnition" SG_ 2527679637 BCM_LTM_PopUp_Texte 0;
BA_ "GenSigSendType" SG_ 2527679637 CPD_Warnung 3;
BA_ "GenSigSwitchedByIgnition" SG_ 2527679637 CPD_Warnung 0;
BA_ "GenSigSendType" SG_ 2527679637 LiSi_Touch_Event 3;
BA_ "GenSigSwitchedByIgnition" SG_ 2527679637 LiSi_Touch_Event 0;
BA_ "Fehlerwert" SG_ 2527679637 LiSi_Touch_Event 15;
BA_ "GenSigSendType" SG_ 2527679637 LTMs_01_alt 0;
BA_ "GenSigStartValue" SG_ 2527679637 LTMs_01_alt 1;
BA_ "GenSigFuncType" SG_ 2527679637 LTMs_01_alt 5;
BA_ "GenSigSwitchedByIgnition" SG_ 2527679637 LTMs_01_alt 0;
BA_ "GenSigSendType" SG_ 2527679637 MiKo_Tisch_Positionswarnung 3;
BA_ "GenSigSwitchedByIgnition" SG_ 2527679637 MiKo_Tisch_Positionswarnung 0;
BA_ "GenSigSendType" SG_ 2463978607 BCM_RGB_Blau 3;
BA_ "GenSigSwitchedByIgnition" SG_ 2463978607 BCM_RGB_Blau 0;
BA_ "GenSigSendType" SG_ 2463978607 BCM_RGB_Dimmrampe 3;
BA_ "GenSigSwitchedByIgnition" SG_ 2463978607 BCM_RGB_Dimmrampe 0;
BA_ "GenSigSendType" SG_ 2463978607 BCM_RGB_Dimmzeit_Zeitbasis 3;
BA_ "GenSigSwitchedByIgnition" SG_ 2463978607 BCM_RGB_Dimmzeit_Zeitbasis 0;
BA_ "GenSigSendType" SG_ 2463978607 BCM_RGB_Gruen 3;
BA_ "GenSigSwitchedByIgnition" SG_ 2463978607 BCM_RGB_Gruen 0;
BA_ "GenSigSendType" SG_ 2463978607 BCM_RGB_Intensitaet 3;
BA_ "GenSigStartValue" SG_ 2463978607 BCM_RGB_Intensitaet 126;
BA_ "GenSigSwitchedByIgnition" SG_ 2463978607 BCM_RGB_Intensitaet 0;
BA_ "Fehlerwert" SG_ 2463978607 BCM_RGB_Intensitaet 127;
BA_ "GenSigSendType" SG_ 2463978607 BCM_RGB_Normierung_Intensitaet 3;
BA_ "GenSigSwitchedByIgnition" SG_ 2463978607 BCM_RGB_Normierung_Intensitaet 0;
BA_ "GenSigSendType" SG_ 2463978607 BCM_RGB_Rot 3;
BA_ "GenSigSwitchedByIgnition" SG_ 2463978607 BCM_RGB_Rot 0;
BA_ "GenSigSendType" SG_ 2463978609 BCM_Relais_2_Batterie 3;
BA_ "GenSigSwitchedByIgnition" SG_ 2463978609 BCM_Relais_2_Batterie 0;
BA_ "GenSigSendType" SG_ 2463978609 FA_Hoehenwert_HL_01 3;
BA_ "GenSigStartValue" SG_ 2463978609 FA_Hoehenwert_HL_01 254;
BA_ "Fehlerwert" SG_ 2463978609 FA_Hoehenwert_HL_01 255;
BA_ "GenSigSendType" SG_ 2463978609 FA_Hoehenwert_VL_01 3;
BA_ "GenSigStartValue" SG_ 2463978609 FA_Hoehenwert_VL_01 254;
BA_ "Fehlerwert" SG_ 2463978609 FA_Hoehenwert_VL_01 255;
BA_ "GenSigSendType" SG_ 2463978609 HSH_LED 3;
BA_ "GenSigSwitchedByIgnition" SG_ 2463978609 HSH_LED 0;
BA_ "GenSigSendType" SG_ 2463978609 HSH_Status 0;
BA_ "GenSigSwitchedByIgnition" SG_ 2463978609 HSH_Status 0;
BA_ "GenSigSendType" SG_ 2463978609 KRH_Stufe_LED_li 3;
BA_ "GenSigSwitchedByIgnition" SG_ 2463978609 KRH_Stufe_LED_li 0;
BA_ "GenSigSendType" SG_ 2463978609 KRH_Stufe_LED_re 3;
BA_ "GenSigSwitchedByIgnition" SG_ 2463978609 KRH_Stufe_LED_re 0;
BA_ "GenSigSendType" SG_ 2463978609 Niveausensor_HL_verbaut 3;
BA_ "GenSigSwitchedByIgnition" SG_ 2463978609 Niveausensor_HL_verbaut 0;
BA_ "GenSigSendType" SG_ 2463978609 Niveausensor_VL_verbaut 3;
BA_ "GenSigSwitchedByIgnition" SG_ 2463978609 Niveausensor_VL_verbaut 0;
BA_ "GenSigSendType" SG_ 2463978609 SIL_Stufe_LED_li 3;
BA_ "GenSigSwitchedByIgnition" SG_ 2463978609 SIL_Stufe_LED_li 0;
BA_ "GenSigSendType" SG_ 2463978609 SIL_Stufe_LED_re 3;
BA_ "GenSigSwitchedByIgnition" SG_ 2463978609 SIL_Stufe_LED_re 0;
BA_ "GenSigSendType" SG_ 526 BCM_Drehwinkel_HL 3;
BA_ "GenSigStartValue" SG_ 526 BCM_Drehwinkel_HL 4094;
BA_ "GenSigSwitchedByIgnition" SG_ 526 BCM_Drehwinkel_HL 0;
BA_ "Fehlerwert" SG_ 526 BCM_Drehwinkel_HL 4095;
BA_ "GenSigSendType" SG_ 526 BCM_Drehwinkel_HR 3;
BA_ "GenSigSwitchedByIgnition" SG_ 526 BCM_Drehwinkel_HR 0;
BA_ "Fehlerwert" SG_ 526 BCM_Drehwinkel_HR 4095;
BA_ "GenSigSendType" SG_ 526 BCM_Drehwinkel_VL 3;
BA_ "GenSigStartValue" SG_ 526 BCM_Drehwinkel_VL 4094;
BA_ "GenSigSwitchedByIgnition" SG_ 526 BCM_Drehwinkel_VL 0;
BA_ "Fehlerwert" SG_ 526 BCM_Drehwinkel_VL 4095;
BA_ "GenSigSendType" SG_ 526 BCM_Drehwinkel_VR 3;
BA_ "GenSigSwitchedByIgnition" SG_ 526 BCM_Drehwinkel_VR 0;
BA_ "Fehlerwert" SG_ 526 BCM_Drehwinkel_VR 4095;
BA_ "GenSigSendType" SG_ 526 BCM_Drehwinkelsensortausch_HL 0;
BA_ "GenSigSwitchedByIgnition" SG_ 526 BCM_Drehwinkelsensortausch_HL 0;
BA_ "GenSigSendType" SG_ 526 BCM_Drehwinkelsensortausch_HR 0;
BA_ "GenSigSwitchedByIgnition" SG_ 526 BCM_Drehwinkelsensortausch_HR 0;
BA_ "GenSigSendType" SG_ 526 BCM_Drehwinkelsensortausch_VL 0;
BA_ "GenSigSwitchedByIgnition" SG_ 526 BCM_Drehwinkelsensortausch_VL 0;
BA_ "GenSigSendType" SG_ 526 BCM_Drehwinkelsensortausch_VR 0;
BA_ "GenSigSwitchedByIgnition" SG_ 526 BCM_Drehwinkelsensortausch_VR 0;
BA_REL_ "GenSigTimeoutTime" BU_SG_REL_ BCM SG_ 2527679923 ADA_HMI_Muedigkeit_Meldung 5000;
BA_REL_ "GenSigTimeoutTime" BU_SG_REL_ BCM SG_ 2527679923 ADA_HMI_Muedigkeit_Event_Meldung 5000;
BA_REL_ "GenSigTimeoutTime" BU_SG_REL_ BCM SG_ 64 Airbag_01_CRC 500;
BA_REL_ "GenSigTimeoutTime" BU_SG_REL_ BCM SG_ 64 Airbag_01_BZ 500;
BA_REL_ "GenSigTimeoutTime" BU_SG_REL_ BCM SG_ 64 AB_Front_Crash 500;
BA_REL_ "GenSigTimeoutTime" BU_SG_REL_ BCM SG_ 64 AB_Heck_Crash 500;
BA_REL_ "GenSigTimeoutTime" BU_SG_REL_ BCM SG_ 64 AB_SF_Crash 500;
BA_REL_ "GenSigTimeoutTime" BU_SG_REL_ BCM SG_ 64 AB_SB_Crash 500;
BA_REL_ "GenSigTimeoutTime" BU_SG_REL_ BCM SG_ 64 AB_Rollover_Crash 500;
BA_REL_ "GenSigTimeoutTime" BU_SG_REL_ BCM SG_ 64 AB_Crash_Int 500;
BA_REL_ "GenSigTimeoutTime" BU_SG_REL_ BCM SG_ 64 AB_Gurtwarn_VF 500;
BA_REL_ "GenSigTimeoutTime" BU_SG_REL_ BCM SG_ 64 AB_Gurtwarn_VB 500;
BA_REL_ "GenSigTimeoutTime" BU_SG_REL_ BCM SG_ 64 AB_Deaktivierung_HV 500;
BA_REL_ "GenSigTimeoutTime" BU_SG_REL_ BCM SG_ 64 AB_Belegung_VF 500;
BA_REL_ "GenSigTimeoutTime" BU_SG_REL_ BCM SG_ 64 AB_Gurtschloss_FA_ext 500;
BA_REL_ "GenSigTimeoutTime" BU_SG_REL_ BCM SG_ 64 AB_Gurtschloss_FA_ext_aktiv 500;
BA_REL_ "GenSigTimeoutTime" BU_SG_REL_ BCM SG_ 1312 Airbag_02_CRC 2000;
BA_REL_ "GenSigTimeoutTime" BU_SG_REL_ BCM SG_ 1312 Airbag_02_BZ 2000;
BA_REL_ "GenSigTimeoutTime" BU_SG_REL_ BCM SG_ 1312 AB_Belegung_VB 2000;
BA_REL_ "GenSigTimeoutTime" BU_SG_REL_ BCM SG_ 1312 SC_PAO_ON_Anf 2000;
BA_REL_ "GenSigTimeoutTime" BU_SG_REL_ BCM SG_ 1312 SC_PAO_OFF_Anf 2000;
BA_REL_ "GenSigTimeoutTime" BU_SG_REL_ BCM SG_ 1312 AB_Gurtschloss_FA 2000;
BA_REL_ "GenSigTimeoutTime" BU_SG_REL_ BCM SG_ 1312 AB_Gurtschloss_BF 2000;
BA_REL_ "GenSigTimeoutTime" BU_SG_REL_ BCM SG_ 1312 AB_Gurtschloss_Reihe2_FA 2000;
BA_REL_ "GenSigTimeoutTime" BU_SG_REL_ BCM SG_ 1312 AB_Gurtschloss_Reihe2_MI 2000;
BA_REL_ "GenSigTimeoutTime" BU_SG_REL_ BCM SG_ 1312 AB_Gurtschloss_Reihe2_BF 2000;
BA_REL_ "GenSigTimeoutTime" BU_SG_REL_ BCM SG_ 1312 AB_Gurtschloss_Reihe3_FA 2000;
BA_REL_ "GenSigTimeoutTime" BU_SG_REL_ BCM SG_ 1312 AB_Gurtschloss_Reihe3_MI 2000;
BA_REL_ "GenSigTimeoutTime" BU_SG_REL_ BCM SG_ 1312 AB_Gurtschloss_Reihe3_BF 2000;
BA_REL_ "GenSigTimeoutTime" BU_SG_REL_ BCM SG_ 1349 Airbag_04_CRC 2000;
BA_REL_ "GenSigTimeoutTime" BU_SG_REL_ BCM SG_ 1349 Airbag_04_BZ 2000;
BA_REL_ "GenSigTimeoutTime" BU_SG_REL_ BCM SG_ 1349 AB_Gurtwarn_Reihe4_FA 2000;
BA_REL_ "GenSigTimeoutTime" BU_SG_REL_ BCM SG_ 1349 AB_Gurtwarn_Reihe4_BF 2000;
BA_REL_ "GenSigTimeoutTime" BU_SG_REL_ BCM SG_ 1349 AB_Gurtwarn_Reihe4_MI 2000;
BA_REL_ "GenSigTimeoutTime" BU_SG_REL_ BCM SG_ 1349 AB_Gurtwarn_Reihe2_FA 2000;
BA_REL_ "GenSigTimeoutTime" BU_SG_REL_ BCM SG_ 1349 AB_Gurtwarn_Reihe2_BF 2000;
BA_REL_ "GenSigTimeoutTime" BU_SG_REL_ BCM SG_ 1349 AB_Gurtwarn_Reihe2_MI 2000;
BA_REL_ "GenSigTimeoutTime" BU_SG_REL_ BCM SG_ 1349 AB_Gurtwarn_Reihe3_FA 2000;
BA_REL_ "GenSigTimeoutTime" BU_SG_REL_ BCM SG_ 1349 AB_Gurtwarn_Reihe3_MI 2000;
BA_REL_ "GenSigTimeoutTime" BU_SG_REL_ BCM SG_ 1349 AB_Gurtwarn_Reihe3_BF 2000;
BA_REL_ "GenSigTimeoutTime" BU_SG_REL_ BCM SG_ 1349 AB_Belegung_VF_ext 2000;
BA_REL_ "GenSigTimeoutTime" BU_SG_REL_ BCM SG_ 1349 AB_Belegung_VF_ext_aktiv 2000;
BA_REL_ "GenSigTimeoutTime" BU_SG_REL_ BCM SG_ 2527679722 AB_Gurtschloss_Reihe4_FA 2000;
BA_REL_ "GenSigTimeoutTime" BU_SG_REL_ BCM SG_ 2527679722 AB_Gurtschloss_Reihe4_BF 2000;
BA_REL_ "GenSigTimeoutTime" BU_SG_REL_ BCM SG_ 2527679722 AB_Gurtschloss_Reihe4_MI 2000;
BA_REL_ "GenSigTimeoutTime" BU_SG_REL_ BCM SG_ 2527679722 AB_Gurtwarn_VM 2000;
BA_REL_ "GenSigTimeoutTime" BU_SG_REL_ BCM SG_ 2527679722 AB_Gurtschloss_MI 2000;
BA_REL_ "GenSigTimeoutTime" BU_SG_REL_ BCM SG_ 1633 AAG_AVS_Fehler_02_inv 1000;
BA_REL_ "GenSigTimeoutTime" BU_SG_REL_ BCM SG_ 1633 AAG_Anhaenger_erkannt 1000;
BA_REL_ "GenSigTimeoutTime" BU_SG_REL_ BCM SG_ 1633 AAG_Blinker_HL_def 1000;
BA_REL_ "GenSigTimeoutTime" BU_SG_REL_ BCM SG_ 1633 AAG_Blinker_HR_def 1000;
BA_REL_ "GenSigTimeoutTime" BU_SG_REL_ BCM SG_ 1633 AAG_AVS_Fehler_02 1000;
BA_REL_ "GenSigTimeoutTime" BU_SG_REL_ BCM SG_ 1633 AAG_AVS_Stati 1000;
BA_REL_ "GenSigTimeoutTime" BU_SG_REL_ BCM SG_ 896 US_Freie_Weglaenge_Heck_Typ 800;
BA_REL_ "GenSigTimeoutTime" BU_SG_REL_ BCM SG_ 896 US_Freie_Weglaenge_Heck 800;
BA_REL_ "GenSigTimeoutTime" BU_SG_REL_ BCM SG_ 2527679661 WBA_Warnblinken 2000;
BA_REL_ "GenSigTimeoutTime" BU_SG_REL_ BCM SG_ 2536704256 BAP_Aussenlicht_ASG_01_Header 800;
BA_REL_ "GenSigTimeoutTime" BU_SG_REL_ BCM SG_ 2536704257 BAP_Aussenlicht_ASG_02_Header 800;
BA_REL_ "GenSigTimeoutTime" BU_SG_REL_ BCM SG_ 2536705280 BAP_Doorlocking_ASG_01_Header 800;
BA_REL_ "GenSigTimeoutTime" BU_SG_REL_ BCM SG_ 2536705281 BAP_Doorlocking_ASG_02_Header 800;
BA_REL_ "GenSigTimeoutTime" BU_SG_REL_ BCM SG_ 2536705282 BAP_Doorlocking_ASG_03_Header 800;
BA_REL_ "GenSigTimeoutTime" BU_SG_REL_ BCM SG_ 2536707072 BAP_Homelink_ASG_01_Header 1200;
BA_REL_ "GenSigTimeoutTime" BU_SG_REL_ BCM SG_ 2536722960 BAP_IAA_PSO_FSG_01_Header 5000;
BA_REL_ "GenSigTimeoutTime" BU_SG_REL_ BCM SG_ 2536704000 BAP_Innenlicht_ASG_01_Header 800;
BA_REL_ "GenSigTimeoutTime" BU_SG_REL_ BCM SG_ 2536704001 BAP_Innenlicht_ASG_02_Header 500;
BA_REL_ "GenSigTimeoutTime" BU_SG_REL_ BCM SG_ 2536704003 BAP_Innenlicht_ASG_04_Header 800;
BA_REL_ "GenSigTimeoutTime" BU_SG_REL_ BCM SG_ 2536705536 BAP_Mirror_ASG_01_Header 800;
BA_REL_ "GenSigTimeoutTime" BU_SG_REL_ BCM SG_ 2536705537 BAP_Mirror_ASG_02_Header 800;
BA_REL_ "GenSigTimeoutTime" BU_SG_REL_ BCM SG_ 2536732416 BAP_MobDevKey_ASG_01_Header 800;
BA_REL_ "GenSigTimeoutTime" BU_SG_REL_ BCM SG_ 2536732417 BAP_MobDevKey_ASG_02_Header 800;
BA_REL_ "GenSigTimeoutTime" BU_SG_REL_ BCM SG_ 2536734480 BAP_MobDevKeyOnline_FSG_01_Heade 5000;
BA_REL_ "GenSigTimeoutTime" BU_SG_REL_ BCM SG_ 2536704528 BAP_OPS_FSG_01_Header 5000;
BA_REL_ "GenSigTimeoutTime" BU_SG_REL_ BCM SG_ 2536704529 BAP_OPS_FSG_02_Header 5000;
BA_REL_ "GenSigTimeoutTime" BU_SG_REL_ BCM SG_ 2536721920 BAP_RemoteServices_ASG_01_Header 800;
BA_REL_ "GenSigTimeoutTime" BU_SG_REL_ BCM SG_ 2536721921 BAP_RemoteServices_ASG_02_Header 800;
BA_REL_ "GenSigTimeoutTime" BU_SG_REL_ BCM SG_ 2536731904 BAP_RollingAbility_ASG_01_Header 800;
BA_REL_ "GenSigTimeoutTime" BU_SG_REL_ BCM SG_ 2536730624 BAP_RSO_ASG_01_Header 800;
BA_REL_ "GenSigTimeoutTime" BU_SG_REL_ BCM SG_ 2536717056 BAP_SeatPneumatic_ASG_01_Header 800;
BA_REL_ "GenSigTimeoutTime" BU_SG_REL_ BCM SG_ 2536717057 BAP_SeatPneumatic_ASG_02_Header 800;
BA_REL_ "GenSigTimeoutTime" BU_SG_REL_ BCM SG_ 2536705024 BAP_Wiper_ASG_01_Header 800;
BA_REL_ "GenSigTimeoutTime" BU_SG_REL_ BCM SG_ 2536705025 BAP_Wiper_ASG_02_Header 800;
BA_REL_ "GenSigTimeoutTime" BU_SG_REL_ Gateway_Max SG_ 1626 BCM_Hybrid_StartStopp_Taste 5000;
BA_REL_ "GenSigTimeoutTime" BU_SG_REL_ Gateway_Max SG_ 1626 BCM1_Rueckfahrlicht_Schalter 5000;
BA_REL_ "GenSigTimeoutTime" BU_SG_REL_ Gateway_Max SG_ 1626 BCM1_MH_Schalter 5000;
BA_REL_ "GenSigTimeoutTime" BU_SG_REL_ Gateway_Max SG_ 1626 BCM_Eco_Charisma_Taste 5000;
BA_REL_ "GenSigTimeoutTime" BU_SG_REL_ Gateway_Max SG_ 1626 BCM1_Spannungs_Anf 5000;
BA_REL_ "GenSigTimeoutTime" BU_SG_REL_ TSGGen3_BFS SG_ 64 Airbag_01_CRC 500;
BA_REL_ "GenSigTimeoutTime" BU_SG_REL_ TSGGen3_BFS SG_ 64 Airbag_01_BZ 500;
BA_REL_ "GenSigTimeoutTime" BU_SG_REL_ TSGGen3_BFS SG_ 64 AB_Front_Crash 500;
BA_REL_ "GenSigTimeoutTime" BU_SG_REL_ TSGGen3_BFS SG_ 64 AB_Heck_Crash 500;
BA_REL_ "GenSigTimeoutTime" BU_SG_REL_ TSGGen3_BFS SG_ 64 AB_SF_Crash 500;
BA_REL_ "GenSigTimeoutTime" BU_SG_REL_ TSGGen3_BFS SG_ 64 AB_SB_Crash 500;
BA_REL_ "GenSigTimeoutTime" BU_SG_REL_ TSGGen3_BFS SG_ 64 AB_Rollover_Crash 500;
BA_REL_ "GenSigTimeoutTime" BU_SG_REL_ TSGGen3_BFS SG_ 64 AB_Crash_Int 500;
BA_REL_ "GenSigTimeoutTime" BU_SG_REL_ TSGGen3_BFS SG_ 64 AB_Gurtwarn_VB 500;
BA_REL_ "GenSigTimeoutTime" BU_SG_REL_ TSGGen3_BFS SG_ 1312 AB_Belegung_VB 2000;
BA_REL_ "GenSigTimeoutTime" BU_SG_REL_ TSGGen3_BFS SG_ 1312 AB_Gurtschloss_BF 2000;
BA_REL_ "GenSigTimeoutTime" BU_SG_REL_ TSGGen3_BFS SG_ 1312 AB_Sitzpos_Sens_BF 2000;
BA_REL_ "GenSigTimeoutTime" BU_SG_REL_ TSGGen3_BFS SG_ 2536727296 BAP_Doors2_ASG_01_Header 500;
BA_REL_ "GenSigTimeoutTime" BU_SG_REL_ TSGGen3_BFS SG_ 1626 BCM1_Rueckfahrlicht_Schalter 5000;
BA_REL_ "GenSigTimeoutTime" BU_SG_REL_ TSGGen3_BFS SG_ 2463978609 HSH_Status 2000;
BA_REL_ "GenSigTimeoutTime" BU_SG_REL_ TSGGen3_FS SG_ 64 Airbag_01_CRC 500;
BA_REL_ "GenSigTimeoutTime" BU_SG_REL_ TSGGen3_FS SG_ 64 Airbag_01_BZ 500;
BA_REL_ "GenSigTimeoutTime" BU_SG_REL_ TSGGen3_FS SG_ 64 AB_Front_Crash 500;
BA_REL_ "GenSigTimeoutTime" BU_SG_REL_ TSGGen3_FS SG_ 64 AB_Heck_Crash 500;
BA_REL_ "GenSigTimeoutTime" BU_SG_REL_ TSGGen3_FS SG_ 64 AB_SF_Crash 500;
BA_REL_ "GenSigTimeoutTime" BU_SG_REL_ TSGGen3_FS SG_ 64 AB_SB_Crash 500;
BA_REL_ "GenSigTimeoutTime" BU_SG_REL_ TSGGen3_FS SG_ 64 AB_Rollover_Crash 500;
BA_REL_ "GenSigTimeoutTime" BU_SG_REL_ TSGGen3_FS SG_ 64 AB_Crash_Int 500;
BA_REL_ "GenSigTimeoutTime" BU_SG_REL_ TSGGen3_FS SG_ 64 AB_Gurtwarn_VF 500;
BA_REL_ "GenSigTimeoutTime" BU_SG_REL_ TSGGen3_FS SG_ 1312 AB_Gurtschloss_FA 2000;
BA_REL_ "GenSigTimeoutTime" BU_SG_REL_ TSGGen3_FS SG_ 1312 AB_Sitzpos_Sens_FA 2000;
BA_REL_ "GenSigTimeoutTime" BU_SG_REL_ TSGGen3_FS SG_ 345 ARA_Modus_Anf 1000;
BA_REL_ "GenSigTimeoutTime" BU_SG_REL_ TSGGen3_FS SG_ 2536724736 BAP_Doors_ASG_01_Header 800;
BA_REL_ "GenSigTimeoutTime" BU_SG_REL_ TSGGen3_FS SG_ 1626 BCM1_Rueckfahrlicht_Schalter 5000;
BA_REL_ "GenSigTimeoutTime" BU_SG_REL_ TSGGen3_FS SG_ 2463978609 HSH_Status 2000;
BA_REL_ "GenSigTimeoutTime" BU_SG_REL_ TSGGen3_HBFS SG_ 64 Airbag_01_CRC 500;
BA_REL_ "GenSigTimeoutTime" BU_SG_REL_ TSGGen3_HBFS SG_ 64 Airbag_01_BZ 500;
BA_REL_ "GenSigTimeoutTime" BU_SG_REL_ TSGGen3_HBFS SG_ 64 AB_Front_Crash 500;
BA_REL_ "GenSigTimeoutTime" BU_SG_REL_ TSGGen3_HBFS SG_ 64 AB_Heck_Crash 500;
BA_REL_ "GenSigTimeoutTime" BU_SG_REL_ TSGGen3_HBFS SG_ 64 AB_SF_Crash 500;
BA_REL_ "GenSigTimeoutTime" BU_SG_REL_ TSGGen3_HBFS SG_ 64 AB_SB_Crash 500;
BA_REL_ "GenSigTimeoutTime" BU_SG_REL_ TSGGen3_HBFS SG_ 64 AB_Rollover_Crash 500;
BA_REL_ "GenSigTimeoutTime" BU_SG_REL_ TSGGen3_HBFS SG_ 64 AB_Crash_Int 500;
BA_REL_ "GenSigTimeoutTime" BU_SG_REL_ TSGGen3_HBFS SG_ 64 AB_Gurtwarn_VF 500;
BA_REL_ "GenSigTimeoutTime" BU_SG_REL_ TSGGen3_HBFS SG_ 64 AB_Gurtwarn_VB 500;
BA_REL_ "GenSigTimeoutTime" BU_SG_REL_ TSGGen3_HBFS SG_ 1312 AB_Gurtschloss_FA 2000;
BA_REL_ "GenSigTimeoutTime" BU_SG_REL_ TSGGen3_HBFS SG_ 1312 AB_Gurtschloss_BF 2000;
BA_REL_ "GenSigTimeoutTime" BU_SG_REL_ TSGGen3_HBFS SG_ 1312 AB_Sitzpos_Sens_FA 2000;
BA_REL_ "GenSigTimeoutTime" BU_SG_REL_ TSGGen3_HBFS SG_ 1312 AB_Sitzpos_Sens_BF 2000;
BA_REL_ "GenSigTimeoutTime" BU_SG_REL_ TSGGen3_HBFS SG_ 1626 BCM1_Rueckfahrlicht_Schalter 5000;
BA_REL_ "GenSigTimeoutTime" BU_SG_REL_ TSGGen3_HFS SG_ 64 Airbag_01_CRC 500;
BA_REL_ "GenSigTimeoutTime" BU_SG_REL_ TSGGen3_HFS SG_ 64 Airbag_01_BZ 500;
BA_REL_ "GenSigTimeoutTime" BU_SG_REL_ TSGGen3_HFS SG_ 64 AB_Front_Crash 500;
BA_REL_ "GenSigTimeoutTime" BU_SG_REL_ TSGGen3_HFS SG_ 64 AB_Heck_Crash 500;
BA_REL_ "GenSigTimeoutTime" BU_SG_REL_ TSGGen3_HFS SG_ 64 AB_SF_Crash 500;
BA_REL_ "GenSigTimeoutTime" BU_SG_REL_ TSGGen3_HFS SG_ 64 AB_SB_Crash 500;
BA_REL_ "GenSigTimeoutTime" BU_SG_REL_ TSGGen3_HFS SG_ 64 AB_Rollover_Crash 500;
BA_REL_ "GenSigTimeoutTime" BU_SG_REL_ TSGGen3_HFS SG_ 64 AB_Crash_Int 500;
BA_REL_ "GenSigTimeoutTime" BU_SG_REL_ TSGGen3_HFS SG_ 64 AB_Gurtwarn_VF 500;
BA_REL_ "GenSigTimeoutTime" BU_SG_REL_ TSGGen3_HFS SG_ 64 AB_Gurtwarn_VB 500;
BA_REL_ "GenSigTimeoutTime" BU_SG_REL_ TSGGen3_HFS SG_ 1312 AB_Gurtschloss_FA 2000;
BA_REL_ "GenSigTimeoutTime" BU_SG_REL_ TSGGen3_HFS SG_ 1312 AB_Gurtschloss_BF 2000;
BA_REL_ "GenSigTimeoutTime" BU_SG_REL_ TSGGen3_HFS SG_ 1312 AB_Sitzpos_Sens_FA 2000;
BA_REL_ "GenSigTimeoutTime" BU_SG_REL_ TSGGen3_HFS SG_ 1312 AB_Sitzpos_Sens_BF 2000;
BA_REL_ "GenSigTimeoutTime" BU_SG_REL_ TSGGen3_HFS SG_ 1626 BCM1_Rueckfahrlicht_Schalter 5000;
VAL_ 2527679923 ADA_DistractionLevel 125 "Ausgeschaltet" 126 "Init" 127 "Fehler" ;
VAL_ 2527679923 ADA_DrowsinessLevel 125 "Ausgeschaltet" 126 "Init" 127 "Fehler" ;
VAL_ 2527679923 ADA_AttentionLevel 126 "Init" 127 "Fehler" ;
VAL_ 2527679923 ADA_DriverIsOperating 0 "Init" 1 "nicht_aktiv" 2 "aktiv" 3 "Fehler" ;
VAL_ 2527679923 ADA_HMI_Ablenkung_Deaktivierung 0 "keine_Meldung" 1 "Ablenkung_deaktiviert" ;
VAL_ 2527679923 ADA_HMI_Ablenkung_Fehler_Popup 0 "keine_Meldung" 1 "Ablenkung_eingesch_verfuegbar" 2 "Ablenkung_nicht_verfuegbar" 3 "Kamera_ausgeschaltet" ;
VAL_ 2527679923 ADA_HMI_Ablenkung_Meldeakustik 0 "Meldeakustik" 1 "keine_Meldeakustik" ;
VAL_ 2527679923 ADA_HMI_Ablenkung_Meldung 0 "keine_Meldung" 1 "Meldung1" 2 "Meldung2" 3 "Meldung3" ;
VAL_ 2527679923 ADA_HMI_Fahrzeit_seit_Pause 1023 "keine_Ausgabe" ;
VAL_ 2527679923 ADA_HMI_Muedigkeit_Deaktivierung 0 "keine_Meldung" 1 "Muedigkeit_deaktiviert" ;
VAL_ 2527679923 ADA_HMI_Muedigkeit_Fehler_Popup 0 "keine_Meldung" 1 "Muedigkeit_eingesch_verfuegbar" 2 "Muedigkeit_nicht_verfuegbar" 3 "Kamera_ausgeschaltet" ;
VAL_ 2527679923 ADA_HMI_Muedigkeit_Meldeakustik 0 "Meldeakustik" 1 "keine_Meldeakustik" ;
VAL_ 2527679923 ADA_HMI_Muedigkeit_Meldung 0 "keine_Meldung" 1 "Meldung1" 2 "Meldung2" 3 "Meldung3" 4 "Meldung_Pausenempfehlung" 5 "reserviert" 6 "reserviert" 7 "reserviert" ;
VAL_ 2527679923 ADA_HMI_Muedigkeit_Event_Meldung 0 "keine_Meldung" 1 "Sekundenschlaf" 2 "Augen_geschlossen" 3 "Gaehnen" ;
VAL_ 2527679923 ADA_DrowsinessSystemState 0 "init" 1 "off" 2 "inactive" 3 "active" 4 "restrictedMode" 5 "reversibleOff" 6 "irreversibleOff" 7 "error" ;
VAL_ 2527679923 ADA_Microsleep 0 "No_microsleep_detected" 1 "Microsleep_imminent" 2 "Microsleep_detected" 6 "Init" 7 "Error" ;
VAL_ 2527679923 ADA_TriggerEmergencyAssist 0 "Aktiver_Fahrer" 1 "Blickabwendung" 2 "Sekundenschlaf" 3 "Schlaf" 6 "Init" 7 "Fehler" ;
VAL_ 2527679923 ADA_Upcoming_Microsleep 0 "no_upcoming_microsleep" 1 "upcoming_microsleep" ;
VAL_ 64 AB_RGS_Anst 4 "aktiv_Niveau_1" 5 "aktiv_Niveau_2" 6 "aktiv_Niveau_3" 7 "aktiv_Niveau_4" 8 "deaktiviert" ;
VAL_ 64 AB_Front_Crash 0 "kein_Front_Crash" 1 "Front_Crash" ;
VAL_ 64 AB_Heck_Crash 0 "kein_Heck_Crash" 1 "Heck_Crash" ;
VAL_ 64 AB_SF_Crash 0 "kein_Seiten_Crash_Fahrer" 1 "Seiten_Crash_Fahrer" ;
VAL_ 64 AB_SB_Crash 0 "kein_Seiten_Crash_Beifahrer" 1 "Seiten_Crash_Beifahrer" ;
VAL_ 64 AB_Rollover_Crash 0 "kein_Rollover" 1 "Rollover" ;
VAL_ 64 AB_Crash_Int 0 "kein_Crash" 1 "Crash_Intensitaet_1" 2 "Crash_Intensitaet_2_(nur_Stellgliedtest_MLB_B8)" 3 "Crash_Intensitaet_2_(nur_D4_C7_Colorado_NF_PAG__Crash_im_MLB_B8)" 4 "Crash_Intensitaet_3_(alt_VW/AUDI__Stellgliedtest_MLB_B8)" 5 "Crash_Intensitaet_3_(alt_PAG)" 7 "Crash_Intensitaet_3" ;
VAL_ 64 AB_Lampe 0 "Aus" 1 "Ein" ;
VAL_ 64 AB_Deaktiviert 0 "aktiv" 1 "deaktiviert" ;
VAL_ 64 AB_VB_deaktiviert 0 "Beifahrerairbag_aktiv" 1 "Beifahrerairbag_deaktiviert" ;
VAL_ 64 AB_Systemfehler 0 "kein_Fehler" 1 "Airbag_Systemfehler" ;
VAL_ 64 AB_Diagnose 0 "nicht_in_Diagnose" 1 "in_Diagnose" ;
VAL_ 64 AB_Stellgliedtest 0 "nicht_im_Stellgliedtest" 1 "Airbag_im_Stellgliedtest" ;
VAL_ 64 AB_Erh_Auf_VB 0 "keine_Anzeige" 1 "Beifahrerairbag_deaktiviert" 2 "Beifahrerairbag_aktiviert" 3 "nicht_definiert" ;
VAL_ 64 AB_Gurtwarn_VF 0 "keine_Warnung" 1 "Gurtwarnung_ausloesen" ;
VAL_ 64 AB_Gurtwarn_VB 0 "keine_Warnung" 1 "Gurtwarnung_ausloesen" ;
VAL_ 64 AB_Anzeige_Fussg 0 "keine_FSG_Aktion_ausgeloest" 1 "Motorhaube_offen" 2 "Systemfehler" ;
VAL_ 64 AB_Texte_AKS 0 "keine_AKS_Ausloesung" 1 "AKS_ausgeloest" 2 "AKS_Systemfehler" ;
VAL_ 64 AB_PAO_Leuchte_Anf 0 "Leuchte_ausschalten" 1 "Leuchte_einschalten" ;
VAL_ 64 AB_MKB_gueltig 0 "Multikollisionsbremsung_nicht_freigeschaltet" 1 "Multikollisionsbremsung_freigeschaltet" ;
VAL_ 64 AB_MKB_Anforderung 0 "Multikollisionsbremsung_nicht_angefordert" 1 "Multikollisionsbremsung_angefordert" ;
VAL_ 64 AB_Versorgungsspannung 0 "plausibel" 1 "unplausibel" ;
VAL_ 64 AB_Deaktivierung_HV 0 "keine_Deaktivierung" 1 "Deaktivierung_1" 2 "Deaktivierung_2" 3 "Deaktivierung_3" 4 "Deaktivierung_4" 5 "Deaktivierung_5" 6 "Deaktivierung_6" 7 "Fehler" ;
VAL_ 64 AB_EDR_Trigger 0 "No_Event" 1 "Start_Event" 2 "NonDeployment_Event" 3 "Deployment_Event" ;
VAL_ 64 AB_Belegung_VF 0 "nicht_verfuegbar" 1 "Fehler" 2 "nicht_belegt" 3 "belegt" ;
VAL_ 64 AB_Gurtschloss_FA_ext 0 "nicht_verbaut" 1 "reserviert" 2 "nicht_gesteckt" 3 "gesteckt" 4 "dauerhaft_nicht_gesteckt" 5 "dauerhaft_gesteckt" 6 "Init" 7 "Fehler" ;
VAL_ 64 AB_Gurtschloss_FA_ext_aktiv 0 "inaktiv" 1 "aktiv" ;
VAL_ 64 AB_eCS_Error 0 "keine_Anzeige" 1 "Anzeige_anfordern" ;
VAL_ 64 ASM_Masterzeit_02 255 "Init" ;
VAL_ 1312 LoGeWa_Event_Kombiwarnung 0 "Init" 1 "Unfall" 2 "Traktionsverlust" 3 "Panne" 4 "Sichtbehinderung" 5 "Aquaplaning" ;
VAL_ 1312 AB_Anforderung_eCall 0 "keine_Anforderung" 1 "Anforderung" ;
VAL_ 1312 AB_Anprall_Seite_Beifahrer 0 "kein_Anprall" 1 "Anprall_erkannt" ;
VAL_ 1312 AB_Anprall_Rollover 0 "kein_Anprall" 1 "Anprall_erkannt" ;
VAL_ 1312 AB_Anprall_FGS 0 "kein_Anprall" 1 "Anprall_erkannt" ;
VAL_ 1312 AB_Anprall_Front_Beifahrer 0 "kein_Anprall" 1 "Anprall_erkannt" ;
VAL_ 1312 AB_Anprall_Front_Fahrer 0 "kein_Anprall" 1 "Anprall_erkannt" ;
VAL_ 1312 AB_Anprall_Heck_Beifahrer 0 "kein_Anprall" 1 "Anprall_erkannt" ;
VAL_ 1312 AB_Anprall_Heck_Fahrer 0 "kein_Anprall" 1 "Anprall_erkannt" ;
VAL_ 1312 AB_Wickelklappung_Reihe2_MI 0 "nicht_verbaut" 1 "nicht_verfuegbar__Fehler_oder_Init" 2 "nicht_verriegelt" 3 "verriegelt" ;
VAL_ 1312 AB_Belegung_VB 0 "nicht_verfuegbar" 1 "Fehler" 2 "nicht_belegt" 3 "belegt" ;
VAL_ 1312 AB_Abschaltanf_SIH_BF 0 "Normalbetrieb" 1 "Abschaltung_angefordert" ;
VAL_ 1312 AB_Anprall_Seite_Fahrer 0 "kein_Anprall" 1 "Anprall_erkannt" ;
VAL_ 1312 SC_PAO_Schriftzug_Anf 0 "LED aus" 1 "LED an" 2 "LED blinken" 3 "reserviert" ;
VAL_ 1312 SC_PAO_ON_Anf 0 "LED aus" 1 "LED an" 2 "LED blinken" 3 "reserviert" ;
VAL_ 1312 SC_PAO_OFF_Anf 0 "LED aus" 1 "LED an" 2 "LED blinken" 3 "reserviert" ;
VAL_ 1312 AB_Crashschwere 0 "kein_Ereignis" 1 "Crashschwere_1" 2 "Crashschwere_2" 3 "Crashschwere_3" 4 "Crashschwere_4" 5 "Crashschwere_5" 6 "Crashschwere_2_bis_5" 7 "Fehler" ;
VAL_ 1312 AB_Anforderung_USM 0 "keine_Anforderung" 1 "Anforderung" ;
VAL_ 1312 AB_Gurtschloss_FA 0 "nicht_verbaut" 1 "nicht_verfügbar (Fehler oder Init)" 2 "nicht_gesteckt" 3 "gesteckt" ;
VAL_ 1312 AB_Gurtschloss_BF 0 "nicht_verbaut" 1 "nicht_verfügbar (Fehler oder Init)" 2 "nicht_gesteckt" 3 "gesteckt" ;
VAL_ 1312 AB_Gurtschloss_Reihe2_FA 0 "nicht_verbaut" 1 "nicht_verfügbar (Fehler oder Init)" 2 "nicht_gesteckt" 3 "gesteckt" ;
VAL_ 1312 AB_Gurtschloss_Reihe2_MI 0 "nicht_verbaut" 1 "nicht_verfügbar (Fehler oder Init)" 2 "nicht_gesteckt" 3 "gesteckt" ;
VAL_ 1312 AB_Gurtschloss_Reihe2_BF 0 "nicht_verbaut" 1 "nicht_verfügbar (Fehler oder Init)" 2 "nicht_gesteckt" 3 "gesteckt" ;
VAL_ 1312 AB_Gurtschloss_Reihe3_FA 0 "nicht_verbaut" 1 "nicht_verfügbar (Fehler oder Init)" 2 "nicht_gesteckt" 3 "gesteckt" ;
VAL_ 1312 AB_Gurtschloss_Reihe3_MI 0 "nicht_verbaut" 1 "nicht_verfügbar (Fehler oder Init)" 2 "nicht_gesteckt" 3 "gesteckt" ;
VAL_ 1312 AB_Gurtschloss_Reihe3_BF 0 "nicht_verbaut" 1 "nicht_verfügbar (Fehler oder Init)" 2 "nicht_gesteckt" 3 "gesteckt" ;
VAL_ 1312 AB_Sitzpos_Sens_FA 0 "nicht verfügbar" 1 "Fehler" 2 "Sitz nicht vorne" 3 "Sitz vorne" ;
VAL_ 1312 AB_Sitzpos_Sens_BF 0 "nicht verfügbar" 1 "Fehler" 2 "Sitz nicht vorne" 3 "Sitz vorne" ;
VAL_ 1312 AB_Wickelklappung_Reihe2_BF 0 "nicht_verbaut" 1 "nicht_verfuegbar__Fehler_oder_Init" 2 "nicht_verriegelt" 3 "verriegelt" ;
VAL_ 1312 AB_Wickelklappung_Reihe2_FA 0 "nicht_verbaut" 1 "nicht_verfuegbar__Fehler_oder_Init" 2 "nicht_verriegelt" 3 "verriegelt" ;
VAL_ 1349 AB_Anprall_Front 0 "kein_Anprall" 1 "Anprall_erkannt" ;
VAL_ 1349 AB_Anprall_Heck 0 "kein_Anprall" 1 "Anprall_erkannt" ;
VAL_ 1349 AB_Gurtwarn_Reihe4_FA 0 "nicht_verbaut" 1 "keine_Gurtwarnung_Sitz_leer" 2 "keine_Gurtwarnung_Sitz_belegt" 3 "Gurtwarnung_Sitz_belegt" ;
VAL_ 1349 AB_Gurtwarn_Reihe4_BF 0 "nicht_verbaut" 1 "keine_Gurtwarnung_Sitz_leer" 2 "keine_Gurtwarnung_Sitz_belegt" 3 "Gurtwarnung_Sitz_belegt" ;
VAL_ 1349 AB_Gurtwarn_Reihe4_MI 0 "nicht_verbaut" 1 "keine_Gurtwarnung_Sitz_leer" 2 "keine_Gurtwarnung_Sitz_belegt" 3 "Gurtwarnung_Sitz_belegt" ;
VAL_ 1349 AB_Gurtwarn_Reihe2_FA 0 "nicht_verbaut" 1 "keine_Gurtwarnung_Sitz_leer" 2 "keine_Gurtwarnung_Sitz_belegt" 3 "Gurtwarnung_Sitz_belegt" ;
VAL_ 1349 AB_Gurtwarn_Reihe2_BF 0 "nicht_verbaut" 1 "keine_Gurtwarnung_Sitz_leer" 2 "keine_Gurtwarnung_Sitz_belegt" 3 "Gurtwarnung_Sitz_belegt" ;
VAL_ 1349 AbstWarn_MV_FAS_Fkt_Status 0 "Init" 1 "Funktion_Ist_Ein" 2 "Funktion_Ist_Aus" 3 "Fehler" ;
VAL_ 1349 WarnBrems_Charisma_Status 0 "Init" 1 "verfügbar" 2 "nicht verfügbar" 3 "asynchron durch Fahrerwunsch" ;
VAL_ 1349 WarnBrems_Charisma_FahrPr 0 "keine_Funktion" 1 "Programm_1" 2 "Programm_2" 3 "Programm_3" 4 "Programm_4" 5 "Programm_5" 6 "Programm_6" 7 "Programm_7" 8 "Programm_8" 9 "Programm_9" 10 "Programm_10" 11 "Programm_11" 12 "Programm_12" 13 "Programm_13" 14 "Programm_14" 15 "Programm_15" ;
VAL_ 1349 AB_Gurtwarn_Reihe2_MI 0 "nicht_verbaut" 1 "keine_Gurtwarnung_Sitz_leer" 2 "keine_Gurtwarnung_Sitz_belegt" 3 "Gurtwarnung_Sitz_belegt" ;
VAL_ 1349 AB_Gurtwarn_Reihe3_FA 0 "nicht_verbaut" 1 "keine_Gurtwarnung_Sitz_leer" 2 "keine_Gurtwarnung_Sitz_belegt" 3 "Gurtwarnung_Sitz_belegt" ;
VAL_ 1349 AB_Gurtwarn_Reihe3_MI 0 "nicht_verbaut" 1 "keine_Gurtwarnung_Sitz_leer" 2 "keine_Gurtwarnung_Sitz_belegt" 3 "Gurtwarnung_Sitz_belegt" ;
VAL_ 1349 AB_Gurtwarn_Reihe3_BF 0 "nicht_verbaut" 1 "keine_Gurtwarnung_Sitz_leer" 2 "keine_Gurtwarnung_Sitz_belegt" 3 "Gurtwarnung_Sitz_belegt" ;
VAL_ 1349 LGI_FAS_Fkt_Status 0 "Init" 1 "Funktion_Ist_Ein" 2 "Funktion_Ist_Aus" 3 "Fehler" ;
VAL_ 1349 PreCrash_FAS_Fkt_Status 0 "Init" 1 "Funktion_Ist_Ein" 2 "Funktion_Ist_Aus" 3 "Fehler" ;
VAL_ 1349 AB_Belegung_VF_ext 0 "nicht_verbaut" 1 "reserviert" 2 "nicht_belegt" 3 "belegt" 4 "dauerhaft_nicht_belegt" 5 "dauerhaft_belegt" 6 "Init" 7 "Fehler" ;
VAL_ 1349 AB_SBR_hinten_verbau 0 "ohne_SBR_hinten" 1 "mit_SBR_hinten" 2 "nicht_definiert" 3 "Init" ;
VAL_ 1349 AB_Belegung_VF_ext_aktiv 0 "inaktiv" 1 "aktiv" ;
VAL_ 1349 AWV_Einstellung_System_ASG 0 "deaktiviert" 1 "aktiviert" ;
VAL_ 1349 AWV_Einstellung_Warnung_ASG 0 "Aus" 1 "Setting_2" 2 "Setting_3" 3 "Setting_4" 4 "Setting_5" 5 "Ein" ;
VAL_ 1349 SC_PreSense_Modus_Warnung_NV 0 "Aus" 1 "Setting_2" 2 "Setting_3" 3 "Setting_4" 4 "Setting_5" 5 "Ein" ;
VAL_ 1349 SC_PreSense_Modus_Warnung_MV 0 "Aus" 1 "Setting_2" 2 "Setting_3" 3 "Setting_4" 4 "Setting_5" 5 "Ein" ;
VAL_ 1349 SC_PreSense_Modus_System_MV 0 "deaktiviert" 1 "aktiviert" ;
VAL_ 1349 SC_PreSense_Modus_System_NV 0 "deaktiviert" 1 "aktiviert" ;
VAL_ 1349 SC_PreSense_Modus_System_KAS 0 "deaktiviert" 1 "aktiviert" ;
VAL_ 2527679722 AB_Gurtschloss_Reihe4_FA 0 "nicht_verbaut" 1 "nicht_verfügbar (Fehler oder Init)" 2 "nicht_gesteckt" 3 "gesteckt" ;
VAL_ 2527679722 AB_Gurtschloss_Reihe4_BF 0 "nicht_verbaut" 1 "nicht_verfügbar (Fehler oder Init)" 2 "nicht_gesteckt" 3 "gesteckt" ;
VAL_ 2527679722 AB_Gurtschloss_Reihe4_MI 0 "nicht_verbaut" 1 "nicht_verfügbar (Fehler oder Init)" 2 "nicht_gesteckt" 3 "gesteckt" ;
VAL_ 2527679722 AB_wSBR_Batteriestatus 0 "Batterien_OK" 1 "mindestens_eine_Batterie_schwach" ;
VAL_ 2527679722 AB_Gurtwarn_VM 0 "keine_Warnung" 1 "Gurtwarnung_ausloesen" ;
VAL_ 2527679722 AB_Gurtschloss_MI 0 "nicht_verbaut" 1 "nicht_verfügbar (Fehler oder Init)" 2 "nicht_gesteckt" 3 "gesteckt" ;
VAL_ 2527679722 AB_Anzeige_Komfort_HBFS 0 "keine_Statusanzeige" 1 "Anzeige_Lehne_ein" 2 "Anzeige_SNV_ein" 3 "Anzeige_Lehne_UND_SNV_ein" ;
VAL_ 2527679722 AB_Anzeige_Komfort_HFS 0 "keine_Statusanzeige" 1 "Anzeige_Lehne_ein" 2 "Anzeige_SNV_ein" 3 "Anzeige_Lehne_UND_SNV_ein" ;
VAL_ 2527679722 AB_Anzeige_Sitz_Komfort_HBFS 0 "keine_Statusanzeige" 1 "Anzeige_Lehne_ein" 2 "Anzeige_SNV_ein" 3 "Anzeige_Lehne_UND_SNV_ein" ;
VAL_ 2527679722 AB_Anzeige_Sitz_Komfort_HFS 0 "keine_Statusanzeige" 1 "Anzeige_Lehne_ein" 2 "Anzeige_SNV_ein" 3 "Anzeige_Lehne_UND_SNV_ein" ;
VAL_ 2527679722 AB_Status_Sitz_SRAB_HBFS 0 "Einschaltung_SRAB" 1 "Abschaltung_SRAB" 2 "Init" 3 "Fehler" ;
VAL_ 2527679722 AB_Status_Sitz_SRAB_HFS 0 "Einschaltung_SRAB" 1 "Abschaltung_SRAB" 2 "Init" 3 "Fehler" ;
VAL_ 2527679722 AB_Anzeige_Kombi_SRAB 0 "keine_Statusanzeige" 1 "HFS_EIN_HFBS_EIN" 2 "HFS_AUS_HFBS_AUS" 3 "HFS_EIN_HFBS_AUS" 4 "HFS_AUS_HFBS_EIN" ;
VAL_ 1633 AAG_AVS_Fehler_02_inv 0 "Fehler" 1 "kein_Fehler" ;
VAL_ 1633 AAG_Bremsl_durch_ECD 0 "Bremslicht_ist_aus" 1 "Bremslicht_durch_ECD_aktiv" ;
VAL_ 1633 AAG_Anhaenger_abgesteckt 1 "Anhaenger_wurde_bei_KL15_aus_abgesteckt" ;
VAL_ 1633 AAG_NSL_aktiv 0 "Init" 1 "Anhaenger_Nebelschusslicht_aktiv" ;
VAL_ 1633 AAG_Anhaenger_erkannt 0 "kein_Anhaenger_erkannt" 1 "AAG_Anhaenger_erkannt" ;
VAL_ 1633 AAG_Blinker_H_aktiv 0 "Init" 1 "Anhaenger_Blinker_aktiv" ;
VAL_ 1633 AAG_Blinker_HL_def 0 "Init" 1 "Anhaenger_Blinker_links_defekt" ;
VAL_ 1633 AAG_Blinker_HR_def 0 "Init" 1 "Anhaenger_Blinker_rechts_defekt" ;
VAL_ 1633 AAG_Bremslicht_H_def 0 "Init" 1 "Anhaenger_Bremslicht_defekt" ;
VAL_ 1633 AAG_Schlusslicht_HL_def 0 "Init" 1 "Anhaenger_Schlusslicht_links_defekt" ;
VAL_ 1633 AAG_Schlusslicht_HR_def 0 "Init" 1 "Anhaenger_Schlusslicht_rechts_defekt" ;
VAL_ 1633 AAG_Bremslicht_Reku 0 "inaktiv" 1 "aktiv" ;
VAL_ 1633 AAG_AVS_Fehler_02 0 "kein_Fehler" 1 "Fehler" ;
VAL_ 1633 AAG_LED_aktiv 0 "Lampen" 1 "LED" ;
VAL_ 1633 AAG_AVS_Stati 0 "endlage_eingefahren_erreicht" 1 "endlage_ausgefahren_erreicht" 2 "ausfahren_automatik" 3 "einfahren_automatik" 4 "ausfahren_manuell" 5 "einfahren_manuell" 6 "zwischenposition" 7 "nicht_initialisiert" ;
VAL_ 896 US_Sende_Modus 0 "keine_fuer_das_ACC_SG_relevanten_Abstandswerte_werden_gesendet" 1 "4K_ext_range__10_Signalwege_verfuegbar__4m" 2 "4K_norm_range__10_Signalwege_verfuegbar__2m" 3 "6K_ext_range__16_Signalwege_verfuegbar__4m" 4 "6K_norm_range__16_Signalwege_verfuegbar__2m" 5 "2K_ext_range__2_Signalwege_verfuegbar__4m" 6 "Modeumschaltung__ext_>_norm__oder__norm_>_ext" 7 "Blindheitspruefung" 8 "4K_ext_range__12_Signalwege_verfuegbar_4m" 9 "4K_norm_range__12_Signalwege_verfuegbar_2m" 10 "6K_ext_range__18_Signalwege_verfuegbar_4m" 11 "6K_norm_range__18_Signalwege_verfuegbar_2m" 15 "Fehler" ;
VAL_ 896 US_relevanter_Fehler 0 "kein_relevanter_Fehler" 1 "relevanter_Fehler" ;
VAL_ 896 US_relevante_Nichtverfuegbarkeit 0 "verfuegbar" 1 "nicht_verfuegbar" ;
VAL_ 896 US_Freisicht_nio 0 "Freisicht_iO" 1 "Freisicht_niO" ;
VAL_ 896 US_blindness_detected 0 "blindness_nicht_detektiert" 1 "blindness_detektiert" ;
VAL_ 896 US_Sende_Modus_hinten 0 "keine_fuer_das_ACC_SG_relevanten_Abstandswerte_werden_gesendet" 5 "2K_ext_range__2_Signalwege_verfuegbar__4m" 6 "Modeumschaltung__ext_>_norm__oder__norm_>_ext" 7 "Blindheitspruefung" 15 "Fehler" ;
VAL_ 896 US_Freie_Weglaenge_Heck_Typ 0 "Maximaler_Messbereich" 1 "Hindernis_detektiert" ;
VAL_ 896 US_Freie_Weglaenge_Heck 510 "Init" 511 "Fehler" ;
VAL_ 896 APS_Master_Sendestatus 0 "Langsame_Zykluszeit_aktiv" 1 "Schnelle_Zykluszeit_aktiv" ;
VAL_ 896 US_Freie_Weglaenge_Front_Typ 0 "Maximaler_Messbereich" 1 "Hindernis_detektiert" ;
VAL_ 896 US_Freie_Weglaenge_Front 509 "freie_Weglaenge_groesser_5m" 510 "Init" 511 "Fehler" ;
VAL_ 345 ARA_Knickwinkel_Konfidenz 126 "Init" 127 "Fehler" ;
VAL_ 345 ARA_Texte 0 "kein Text/Akustik" 63 "Fehler" ;
VAL_ 345 ARA_Modus 0 "Knickwinkelmodus" 1 "Trajektorienmodus" ;
VAL_ 345 ARA_Aktiver_Grafikmodus 0 "keine_Grafik" 1 "Grafikmodus_aktiv" ;
VAL_ 345 ARA_Deaktivierung_sperren 0 "nicht_gesperrt" 1 "gesperrt" ;
VAL_ 345 ARA_Modus_Anf 0 "ARA Modus nicht im TSG angefordert" 1 "ARA Modus im TSG angefordert" ;
VAL_ 345 ARA_Bremsfuss 0 "kein Bremsfuss" 1 "Bremsfuss angefordert" ;
VAL_ 345 ARA_Sensor_Aktivierung 0 "Knickwinkelsensor_deaktivieren" 1 "Knickwinkelsensor_aktivieren" ;
VAL_ 345 ARA_Knickwinkel_Komfort 62 "Init" 63 "Fehler" ;
VAL_ 345 ARA_Status 0 "ARA_Status_inaktiv" 1 "ARA_Status_init" 2 "Fehler" 3 "ARA_Status_Start" 4 "ARA_Status_aktiv" 6 "ARA_Status_Regelung_aktiv" 8 "ARA_Status_betriebsbereit" 9 "ARA_Status_Klemmtraeger_erkannt" 10 "ARA_Status_Abbruch" 11 "ARA_Status_nicht_betriebsbereit" ;
VAL_ 345 ARA_Knickwinkel_Max 126 "Init" 127 "Fehler" ;
VAL_ 345 ARA_Knickwinkel_Soll 254 "Init" 255 "Fehler" ;
VAL_ 345 ARA_Knickwinkel_Ist 254 "Init" 255 "Fehler" ;
VAL_ 2527679661 WBA_Warnblinken 0 "kein_Blinken" 1 "Warnblinken" 2 "Warnblinken_Taster" ;
VAL_ 2527679661 AWV_KA_Konfiguration 0 "Ausgeschaltet" 1 "Eingeschaltet" ;
VAL_ 2527679661 AWV_Warnung 0 "keine_Anzeige" 1 "latente_Vorwarnung" 2 "Vorwarnung" 3 "AWU_ohne_Ton_oder_Akutwarnung" 4 "Eingriff" 5 "Fahreruebernahmeaufforderung" 6 "AWU_mit_Ton" 7 "Querinfo_2" ;
VAL_ 2527679661 AWV_Texte_02 0 "keine_Anzeige" 1 "Systemstoerung" 2 "keine_Sensorsicht" 3 "Initialisierung_gelb" 4 "System_aus" 5 "Initialisierung" 6 "Sensorfusion_eingeschraenkt" 7 "zurzeit_eingeschraenkt" ;
VAL_ 2527679661 AWV_Warnlevel 0 "keine_Gefaehrdung" 63 "max_Gefaehrdung" ;
VAL_ 2527679661 AWV_Einstellung_System_FSG 0 "deaktiviert" 1 "aktiviert" ;
VAL_ 2527679661 AWV_Einstellung_Warnung_FSG 0 "Aus" 1 "Setting_2" 2 "Setting_3" 3 "Setting_4" 4 "Setting_5" 5 "Ein" ;
VAL_ 2527679661 AWV_Status_Anzeige 0 "Init" 1 "verfuegbar" 2 "nicht_verfuegbar" ;
VAL_ 2527679661 AWV_LED_Leiste 0 "keine_Anzeige" 1 "Stufe_1_glimmen" 2 "Stufe_2_leuchten" 3 "nicht_definiert" ;
VAL_ 2527679661 AWV_Priowarnung 0 "HCA_Warnung_nicht_unterdruecken" 1 "HCA_Warnung_unterdruecken" ;
VAL_ 2527679661 AWV_AW_Abstand 509 "Freifahrt" 510 "nicht_definiert" 511 "Keine_Anzeige" ;
VAL_ 2527679661 AWV_AW_Zeitluecke 0 "keine_Anzeige" 1 "Zeitluecke_1" 2 "Zeitluecke_2" 3 "Zeitluecke_3" ;
VAL_ 2527679661 AWV_AW_Texte 0 "Keine_Anzeige" 1 "Systemstoerung" 2 "keine_Sensorsicht" 3 "zurzeit_eingeschraenkt" ;
VAL_ 2527679661 AWV_AW_Texte_Zusatzanzeige 0 "keine_Anzeige" 1 "Abstandsanzeige" 2 "AW_Warnschwelle_1" 3 "AW_Warnschwelle_2" 4 "AW_Warnschwelle_3" 5 "AW_Warnung_1" 6 "AW_Warnung_2" 7 "AW_Warnung_3" ;
VAL_ 2527679661 AWV_KA_ObjektFront 0 "kein_Hindernis" 1 "Hindernis_erkannt" ;
VAL_ 2527679661 AWV_Warnung_Richtung 0 "keine_Richtung" 1 "Links" 2 "Mitte" 3 "Rechts" 4 "Links_und_Rechts" ;
VAL_ 2527679661 AWV_Kamera_Objekt_ID 0 "Kein_Kameraobjekt" ;
VAL_ 2463978752 AZK_Kessy_defekt 0 "keine_Anzeige" 1 "Anzeige" ;
VAL_ 2463978752 AZK_Kessy_nicht_gefunden 0 "keine_Anzeige" 1 "Anzeige" ;
VAL_ 2463978752 AZK_MobileKey_defekt 0 "keine_Anzeige" 1 "Anzeige" ;
VAL_ 2463978752 AZK_Mobilgeraet_nicht_gefunden 0 "keine_Anzeige" 1 "Anzeige" ;
VAL_ 2463978752 AZK_Schluessel_im_Fzg 0 "keine_Anzeige" 1 "Anzeige" ;
VAL_ 2463978752 AZK_Weiterfahrt_mit_Mobilgeraet 0 "keine_Anzeige" 1 "Anzeige" ;
VAL_ 2463978752 AZK_Weiterfahrt_mit_Schluessel 0 "keine_Anzeige" 1 "Anzeige" ;
VAL_ 2463978752 AZK_Schluessel_nicht_gefunden 0 "keine_Anzeige" 1 "Anzeige" ;
VAL_ 2527679636 BCM1_DML_Einsteigelicht_aktiv 0 "inaktiv" 1 "aktiv" ;
VAL_ 2527679636 BCM1_DML_Lichtfuehrung_aktiv 0 "inaktiv" 1 "aktiv" ;
VAL_ 2527679636 BCM1_DML_Lichtassistenz_aktiv 0 "inaktiv" 1 "aktiv" ;
VAL_ 2527679636 BCM1_DML_Fahrbereit 0 "nicht_fahrbereit" 1 "fahrbereit" ;
VAL_ 2527679636 BCM1_DML_Aussteigelicht_aktiv 0 "inaktiv" 1 "aktiv" ;
VAL_ 2527679636 BCM1_DML_TraLi_Variante 0 "deaktiviert" 1 "Projektion_1" 2 "Projektion_2" 3 "Projektion_3" 4 "Projektion_4" ;
VAL_ 2527679636 BCM1_DML_BauLi_Variante 0 "deaktiviert" 1 "Projektion_1" 2 "Projektion_2" 3 "Projektion_3" 4 "Projektion_4" ;
VAL_ 2527679636 BCM1_DML_SitLi_Variante 0 "deaktiviert" 1 "Projektion_1" 2 "Projektion_2" 3 "Projektion_3" 4 "Projektion_4" ;
VAL_ 2527679636 BCM1_DML_aCH_Variante 0 "deaktiviert" 1 "Projektion_1" 2 "Projektion_2" 3 "Projektion_3" 4 "Projektion_4" 5 "Projektion_5" ;
VAL_ 2527679636 BCM1_DML_aLH_Variante 0 "deaktiviert" 1 "Projektion_1" 2 "Projektion_2" 3 "Projektion_3" 4 "Projektion_4" 5 "Projektion_5" ;
VAL_ 2527679636 BCM1_DML_AbbiegeWa_Variante 0 "deaktiviert" 1 "Projektion_1" 2 "Projektion_2" 3 "Projektion_3" 4 "Projektion_4" ;
VAL_ 2527679636 BCM1_DML_AbsAss_Variante 0 "deaktiviert" 1 "Projektion_1" 2 "Projektion_2" 3 "Projektion_3" 4 "Projektion_4" ;
VAL_ 2527679636 BCM1_DML_AccAss_Variante 0 "deaktiviert" 1 "Projektion_1" 2 "Projektion_2" 3 "Projektion_3" 4 "Projektion_4" ;
VAL_ 2527679636 BCM1_DML_BeAss_Variante 0 "deaktiviert" 1 "Projektion_1" 2 "Projektion_2" 3 "Projektion_3" 4 "Projektion_4" ;
VAL_ 2527679636 BCM1_DML_EffAss_Variante 0 "deaktiviert" 1 "Projektion_1" 2 "Projektion_2" 3 "Projektion_3" 4 "Projektion_4" ;
VAL_ 2527679636 BCM1_DML_PreSAss_Variante 0 "deaktiviert" 1 "Projektion_1" 2 "Projektion_2" 3 "Projektion_3" 4 "Projektion_4" ;
VAL_ 2527679636 BCM1_DML_RouLi_Variante 0 "deaktiviert" 1 "Projektion_1" 2 "Projektion_2" 3 "Projektion_3" 4 "Projektion_4" ;
VAL_ 2527679636 BCM1_DML_SpuLi_Variante 0 "deaktiviert" 1 "Projektion_1" 2 "Projektion_2" 3 "Projektion_3" 4 "Projektion_4" ;
VAL_ 1626 BCM_Bremsbelag_Sensor 0 "OK" 1 "Bremsbelag_unter_min" ;
VAL_ 1626 BCM_Bremsfluessigkeit_Sensor 0 "OK" 1 "Bremsfluessigkeit_unter_min" ;
VAL_ 1626 BCM1_Licht_Warn 0 "OK" 1 "Lichtwarnung_aktiv" ;
VAL_ 1626 BCM_Waschwasser_Sensor 0 "OK" 1 "Waschwasser_unter_min" ;
VAL_ 1626 BCM_Kuehlmittel_Sensor 0 "OK" 1 "Kuehlmittel_unter_min" ;
VAL_ 1626 BCM1_Kl_15_HW_erkannt 1 "Klemme 15 erkannt" ;
VAL_ 1626 BCM1_Kl_15_Sig_HW_erkannt 0 "KL15_HW_Signal_von_BCM1_nicht_erkannt" 1 "KL15_HW_Signal_von_BCM1_erkannt" ;
VAL_ 1626 BCM_Kuehlmittel_Sensor_02 0 "OK" 1 "Kuehlmittel_unter_min" ;
VAL_ 1626 BCM1_Hinweis_Lichtnachlauf 0 "inaktiv" 1 "aktiv" ;
VAL_ 1626 BCM_Offroad_Taste 0 "Taster_nicht_betaetigt" 1 "Taster_betaetigt" ;
VAL_ 1626 BCM_Charisma_Taste2 0 "nicht_betaetigt" 1 "betaetigt" ;
VAL_ 1626 BCM_Hybrid_StSt_Taste_Fehler 0 "kein_Fehler_StSt_Taster" 1 "Fehler_StSt_Taster" ;
VAL_ 1626 BCM_Hybrid_StartStopp_Taste 0 "nicht_betaetigt" 1 "betaetigt" ;
VAL_ 1626 BCM1_Warnblink_Taster 0 "nicht_betaetigt" 1 "betaetigt" ;
VAL_ 1626 BCM1_Valet_Parking_Taster 0 "nicht_betaetigt" 1 "betaetigt" ;
VAL_ 1626 BCM1_LDS_Stellung 0 "Init" 1 "Stellung_0" 2 "Auto" 3 "Standlicht" 4 "Abblendlicht" 7 "Fehler" ;
VAL_ 1626 BCM1_Rueckfahrlicht_Schalter 0 "nicht_betaetigt" 1 "betaetigt" ;
VAL_ 1626 BCM1_MH_Schalter 0 "MH_geschlossen" 1 "MH_offen" ;
VAL_ 1626 BCM1_MH_WIV_Schalter 0 "MH_geschlossen" 1 "MH_offen" ;
VAL_ 1626 BCM_Eco_Charisma_Taste 0 "nicht_betaetigt" 1 "betaetigt" ;
VAL_ 1626 BCM1_NV_Taster 0 "Taster_nicht_betaetigt" 1 "Taster_betaetigt" ;
VAL_ 1626 BCM1_AFS_Lampe 0 "Aus" 1 "Ein" ;
VAL_ 1626 BCM1_Reisemodus_Texte 0 "keine_Anzeige" 1 "Umschaltung_auf_Linksverkehr_aktiv" 2 "Umschaltung_auf_Rechtsverkehr_aktiv" ;
VAL_ 1626 BCM1_Lichtwarn_Texte 0 "keine_Warnung" 1 "Standlichtwarnung" 2 "Parklichtwarnung" 3 "Nebelschlusslichtwarnung" ;
VAL_ 1626 Gong_TFL_Umschaltung 0 "kein_Gong" 1 "Gong_einmalig" ;
VAL_ 1626 BCM_ValetTaster_Fkts_LED 0 "LED_aus" 1 "LED_ein" ;
VAL_ 1626 LRH_Taster 0 "nicht_betaetigt" 1 "betaetigt" ;
VAL_ 1626 APS_Tongeber_defekt 0 "iO" 1 "defekt" ;
VAL_ 1626 BCM1_EasyEntry_Status 0 "Aus" 1 "Ein" ;
VAL_ 1626 BCM1_Lenksaeule_aktiv 0 "Lenksaeulenverstellung nicht aktiv" 1 "Lenksaeulenverstellung aktiv" ;
VAL_ 1626 BCM1_Spannungs_Anf 0 "keine_Anforderung" 1 "Anforderung_Stufe_1" 2 "Anforderung_Stufe_2" 3 "Anforderung_Stufe_3" ;
VAL_ 1626 DWA_Alarmquelle 0 "kein_Ausloesegrund" 1 "Tuerkontakt_Fahrertuer" 2 "Tuerkontakt_Beifahrertuer" 3 "Tuerkontakt_hinten_links" 4 "Tuerkontakt_hinten_rechts" 5 "Motorhaubenkontakt_vorne" 6 "Kofferraum_hinten" 7 "Masseschleife_der_Heckscheibe" 8 "Innenraumueberwachung" 9 "Alarm_durch_Noteinstieg" 10 "Sounder" 11 "Neigungssensor" 12 "TSG_FT_am_CAN_Bus" 13 "TSG_BT_am_CAN_Bus" 14 "TSG_HFS_am_CAN_Bus" 15 "TSG_HBFS_am_CAN_Bus" 16 "Klemme_15" 17 "Klemme_15sig" 18 "frei" 19 "Anhaengerueberwachung" 20 "Scheinwerferueberwachung_links" 21 "Scheinwerferueberwachung_rechts" 22 "Handschuhkasten" 23 "Verdeckueberwachung" 24 "OBD_Alarm" 25 "Power_on_Reset" 30 "Init" 31 "Fehler" ;
VAL_ 1626 DWA_Einschraenkung 0 "Init" 1 "Fehler" ;
VAL_ 1626 BCM_HBFS_EOE_aktiv 0 "EOE_inaktiv" 1 "EOE_aktiv" ;
VAL_ 1626 BCM_HFS_EOE_aktiv 0 "EOE_inaktiv" 1 "EOE_aktiv" ;
VAL_ 1626 BCM_Anf_AAW_MoLaWa 0 "Init" 1 "AAW_angefordert" 2 "MoLaWa_angefordert" ;
VAL_ 1626 BCM_Handbremse_Hinweis 0 "inaktiv" 1 "aktiv" ;
VAL_ 1626 BCM_Waehlhebel_P_Hinweis 0 "inaktiv" 1 "aktiv" ;
VAL_ 1626 BCM1_Fahrlicht_Hinweis 0 "kein_Fahrlicht_Hinweis" 1 "Fahrlicht_Hinweis" ;
VAL_ 1626 BCM_HDF_betaetigt 0 "nicht_betaetigt" 1 "betaetigt" ;
VAL_ 2527679637 BCM_FAS_Taster 0 "nicht_betaetigt" 1 "betaetigt" ;
VAL_ 2527679637 CPD_Warnung 0 "keine_Warnung" 1 "Warnung_mit_Ton" 2 "Warnung_ohne_Ton" ;
VAL_ 2527679637 MiKo_Tisch_Positionswarnung 0 "keine_Anzeige_Tisch_unten" 1 "Warnung_Tisch_oben" ;
VAL_ 2527679637 LiSi_Touch_Event 0 "nicht_betaetigt" 1 "Tippen" 2 "Wischen_Slide" 3 "Geste" 4 "Doppeltippen" 5 "Longpress_1" 6 "Longpress_2" 7 "Longpress_3" 8 "Press" 9 "Strongpress" 10 "reserviert" 11 "reserviert" 12 "reserviert" 13 "reserviert" 14 "Taktgeber_Inkrement" 15 "Fehler" ;
VAL_ 2527679637 BCM_anf_VLW 0 "Init" 1 "VLW_angefordert_VLK2_1" 2 "deg_VLW_FT_angefordert" 3 "deg_VLW_Werkstatt_angefordert" 4 "VLW_angefordert_VLK2_2" 5 "Wegrollwarnung_angefordert" 6 "Rollfaehigkeit_ohne_Akustik" 7 "Rollfaehigkeit_mit_Akustik" ;
VAL_ 2527679637 BCM_Defrost_Taste 0 "Taste_nicht_betaetigt" 1 "Taste_betaetigt" 2 "Fehler" 3 "Init_oder_nicht_verbaut" ;
VAL_ 2527679637 BCM_HSH_Taste 0 "Taste_nicht_betaetigt" 1 "Taste_betaetigt" 2 "Fehler" 3 "Init_oder_nicht_verbaut" ;
VAL_ 2527679637 BCM_FSH_Taste 0 "Taste_nicht_betaetigt" 1 "Taste_betaetigt" 2 "Fehler" 3 "Init_oder_nicht_verbaut" ;
VAL_ 2527679637 LTMs_01_alt 0 "aktuell" 1 "veraltet" ;
VAL_ 2527679637 BCM_LTM_Nebelschluss_Status 0 "nicht_aktiv" 1 "aktiv" ;
VAL_ 2527679637 BCM_LTM_PopUp_Texte 0 "keine_Anzeige" 1 "Ausschalt_Hinweis" 2 "Ausschalt_Quittierung" ;
VAL_ 2527679637 BCM_LTM_Allwetterl_Status 0 "nicht_aktiv" 1 "aktiv" ;
VAL_ 2527679637 BCM_LTM_PopUp_Status 0 "Init" 1 "AUTO" 2 "Abblendlicht" 3 "Standlicht" 4 "OFF" ;
VAL_ 2527679637 BCM_LTM_Nebell_Status 0 "nicht_aktiv" 1 "aktiv" ;
VAL_ 2527679637 BCM_LTM_PopUp_Anf 0 "keine_Anforderung" 1 "Licht_PopUp" 2 "Nebellicht_PopUp" 3 "Allwetterlicht_PopUp" 4 "Nebelschlusslicht_PopUp" ;
VAL_ 2527679637 BCM_LTM_PopUp_Inhalt 0 "Init" 1 "AUTO" 2 "Abblendlicht" 4 "Standlicht" 8 "OFF" ;
VAL_ 2463978607 BCM_RGB_Intensitaet 126 "Init" 127 "Fehler" ;
VAL_ 2463978607 BCM_RGB_Normierung_Intensitaet 0 "ohne Normierung" 1 "Normierung der Intensität" ;
VAL_ 2463978607 BCM_RGB_Dimmzeit_Zeitbasis 0 "Zeitbasis_50ms" 1 "Zeitbasis_250ms" ;
VAL_ 2463978609 HSH_LED 0 "Aus" 1 "Ein" ;
VAL_ 2463978609 HSH_Status 0 "aus" 1 "ein" 2 "tbd" 3 "Fehler" ;
VAL_ 2463978609 BCM_Relais_2_Batterie 0 "nicht_betaetigt" 1 "betaetigt" ;
VAL_ 2463978609 Niveausensor_HL_verbaut 0 "nicht_verbaut" 1 "verbaut" ;
VAL_ 2463978609 Niveausensor_VL_verbaut 0 "nicht_verbaut" 1 "verbaut" ;
VAL_ 2463978609 KRH_Stufe_LED_re 0 "Aus" 1 "Stufe_1" 2 "Stufe_2" 3 "Stufe_3" ;
VAL_ 2463978609 KRH_Stufe_LED_li 0 "Aus" 1 "Stufe_1" 2 "Stufe_2" 3 "Stufe_3" ;
VAL_ 2463978609 SIL_Stufe_LED_re 0 "Aus" 1 "Stufe_1" 2 "Stufe_2" 3 "Stufe_3" 4 "Stufe_4" 5 "Stufe_5" 6 "Stufe_6" ;
VAL_ 2463978609 SIL_Stufe_LED_li 0 "Aus" 1 "Stufe_1" 2 "Stufe_2" 3 "Stufe_3" 4 "Stufe_4" 5 "Stufe_5" 6 "Stufe_6" ;
VAL_ 2463978609 FA_Hoehenwert_VL_01 254 "nicht initialisiert" 255 "Fehler" ;
VAL_ 2463978609 FA_Hoehenwert_HL_01 254 "nicht initialisiert" 255 "Fehler" ;
VAL_ 526 BCM_Drehwinkelsensortausch_VR 0 "Init" ;
VAL_ 526 BCM_Drehwinkelsensortausch_HR 0 "Init" ;
VAL_ 526 BCM_Drehwinkel_VR 4091 "nicht_verwendet" 4092 "nicht_verwendet" 4093 "Sensor_nicht_verbaut" 4094 "Init" 4095 "Fehler" ;
VAL_ 526 BCM_Drehwinkel_HR 4091 "nicht_verwendet" 4092 "nicht_verwendet" 4093 "Sensor_nicht_verbaut" 4094 "Init" 4095 "Fehler" ;
VAL_ 526 BCM_Drehwinkel_HL 4091 "nicht_verwendet" 4092 "nicht_verwendet" 4093 "Sensor_nicht_verbaut" 4094 "Init" 4095 "Fehler" ;
VAL_ 526 BCM_Drehwinkel_VL 4091 "nicht_verwendet" 4092 "nicht_verwendet" 4093 "Sensor_nicht_verbaut" 4094 "Init" 4095 "Fehler" ;
VAL_ 526 BCM_Drehwinkelsensortausch_HL 0 "Init" ;
VAL_ 526 BCM_Drehwinkelsensortausch_VL 0 "Init" ;
